VERSION ""

NS_ :

BS_:

BU_: T_Box HUT DMS DVR GW Tester

BO_ 696 ACC_FD4: 64 GW
 SG_ ACC_DataRecReq : 487|3@0+ (1,0) [0|7] ""  DVR

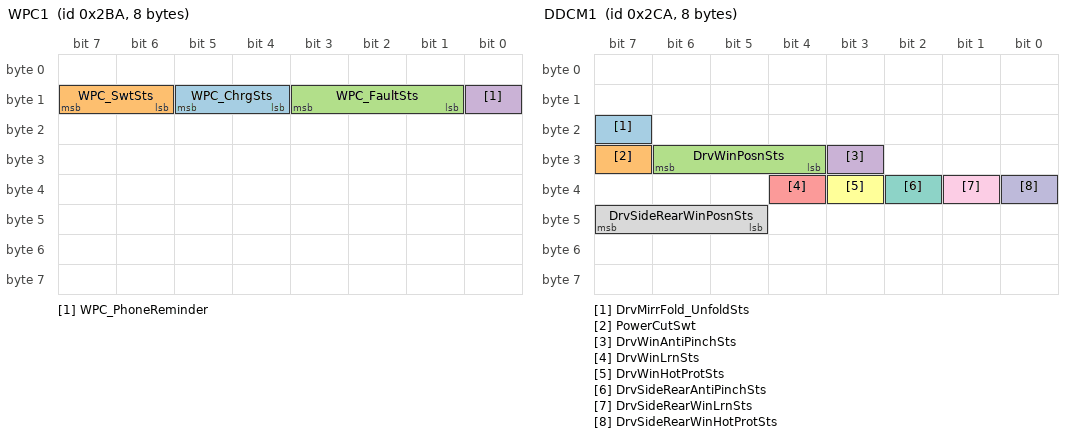
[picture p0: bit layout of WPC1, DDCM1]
BO_ 698 WPC1: 8 GW
 SG_ WPC_ChrgSts : 13|2@0+ (1,0) [0|3] ""  HUT
 SG_ WPC_SwtSts : 15|2@0+ (1,0) [0|3] ""  HUT
 SG_ WPC_FaultSts : 11|3@0+ (1,0) [0|7] ""  HUT
 SG_ WPC_PhoneReminder : 8|1@0+ (1,0) [0|1] ""  HUT

BO_ 699 GW_FD1: 64 GW
 SG_ U_BATT : 71|14@0+ (0.0009765625,3) [3|18] "V"  HUT,T_Box
 SG_ I_RANGE : 73|2@0+ (1,0) [0|3] ""  HUT
 SG_ I_BATT : 87|16@0+ (1,-32768) [-1500|1500] "A"  HUT
 SG_ SOC : 135|8@0+ (1,0) [0|100] "%"  HUT,DVR
 SG_ SOH_SUL : 143|8@0+ (1,0) [0|100] "%"  HUT
 SG_ SOC_STATE : 183|2@0+ (1,0) [0|3] ""  HUT
 SG_ SOH_SUL_STATE : 181|2@0+ (1,0) [0|3] ""  HUT

BO_ 705 DSM1: 8 GW
 SG_ DSM_BuzSoundCmd : 11|2@0+ (1,0) [0|3] ""  HUT

BO_ 707 HUT_FD1: 64 HUT
 SG_ SSSSet_HUT : 64|1@0+ (1,0) [0|1] ""  GW
 SG_ IFC_SnvtySet : 77|2@0+ (1,0) [0|3] ""  GW
 SG_ DOWSwtReq : 104|1@0+ (1,0) [0|1] ""  GW
 SG_ AEB_PedSwtReq : 105|1@0+ (1,0) [0|1] ""  GW
 SG_ ALCMLightLvlSet : 75|4@0+ (1,0) [0|15] "" Vector__XXX
 SG_ FlashLmpSwtReq : 86|1@0+ (1,0) [0|1] ""  GW
 SG_ LCASwtReq : 85|1@0+ (1,0) [0|1] ""  GW
 SG_ RCTASwtReq : 84|1@0+ (1,0) [0|1] ""  GW
 SG_ RCTABrkSwtReq : 83|1@0+ (1,0) [0|1] ""  GW
 SG_ RCWSwtReq : 82|1@0+ (1,0) [0|1] ""  GW
 SG_ FCW_SnvtySet : 81|2@0+ (1,0) [0|3] ""  GW
 SG_ AEB_VehSwtReq : 95|1@0+ (1,0) [0|1] ""  GW
 SG_ LKASwtReq : 93|1@0+ (1,0) [0|1] ""  GW
 SG_ LCKSwtReq : 92|1@0+ (1,0) [0|1] ""  GW
 SG_ ELKSwtReq : 91|1@0+ (1,0) [0|1] ""  GW
 SG_ ESS_PedSwtReq : 90|1@0+ (1,0) [0|1] ""  GW
 SG_ ESS_VehSwtReq : 89|1@0+ (1,0) [0|1] ""  GW
 SG_ LDWSwtReq : 88|1@0+ (1,0) [0|1] ""  GW
 SG_ TSRSwtReq : 102|1@0+ (1,0) [0|1] ""  GW
 SG_ TSRWarnSwtReq : 101|1@0+ (1,0) [0|1] ""  GW
 SG_ ICA_HandsOffSwtReq : 127|1@0+ (1,0) [0|1] ""  GW
 SG_ ISLSwtReq : 126|1@0+ (1,0) [0|1] ""  GW
 SG_ TSR_SnvtySet : 125|5@0+ (1,-15) [-15|15] "km/h"  GW
 SG_ BrkPedalFeelReq : 79|2@0+ (1,0) [0|3] "" Vector__XXX
 SG_ HFASwtSts : 87|1@0+ (1,0) [0|1] ""  GW
 SG_ EPSSteerModSwtReq : 114|2@0+ (1,0) [0|3] ""  GW
 SG_ DSTSwtReq : 112|1@0+ (1,0) [0|1] ""  GW
 SG_ HUT_ESPFuncOffSwtSts : 98|1@0+ (1,0) [0|1] ""  GW
 SG_ DrivingModReq_HUT : 111|4@0+ (1,0) [0|15] ""  GW
 SG_ LSSSwtReq : 106|1@0+ (1,0) [0|1] ""  GW
 SG_ LSSWarnFormSwtReq : 100|2@0+ (1,0) [0|3] ""  GW
 SG_ IntelligentEvaSwtReq : 107|1@0+ (1,0) [0|1] ""  GW
 SG_ HUT_BattSOCLimSaveMod : 119|5@0+ (1,0) [0|31] ""  GW
 SG_ HUTRadioFrq : 143|12@0+ (1,0) [0|4095] "AM; kHzFM; MHz" Vector__XXX
 SG_ MediaPlaySrc : 159|4@0+ (1,0) [0|15] "" Vector__XXX
 SG_ HUT_DrvModReq : 167|4@0+ (1,0) [0|15] ""  GW
 SG_ USB_AudioSts : 169|2@0+ (1,0) [0|3] "" Vector__XXX
 SG_ USB_VideoSts : 177|2@0+ (1,0) [0|3] "" Vector__XXX
 SG_ BT_AudioSts : 179|2@0+ (1,0) [0|3] "" Vector__XXX
 SG_ IPod_Sts : 181|2@0+ (1,0) [0|3] "" Vector__XXX
 SG_ AM_Sts : 183|2@0+ (1,0) [0|3] "" Vector__XXX
 SG_ FM_Sts : 185|2@0+ (1,0) [0|3] "" Vector__XXX
 SG_ APPLink_Sts : 187|2@0+ (1,0) [0|3] "" Vector__XXX
 SG_ QQMusic_Sts : 189|2@0+ (1,0) [0|3] "" Vector__XXX
 SG_ KaolaFM_Sts : 191|2@0+ (1,0) [0|3] "" Vector__XXX
 SG_ OnlineNews_Sts : 145|2@0+ (1,0) [0|3] "" Vector__XXX
 SG_ ChairMemPosnSet : 244|2@0+ (1,0) [0|3] "" Vector__XXX
 SG_ CCOSwtReq_HUT : 242|1@0+ (1,0) [0|1] ""  GW
 SG_ ChairMemPosnSetResult : 255|4@0+ (1,0) [0|15] "" Vector__XXX
 SG_ TABSwtReq_HUT : 224|1@0+ (1,0) [0|1] ""  GW
 SG_ NavVehToTrafEyeDist : 239|10@0+ (1,0) [0|1023] ""  GW
 SG_ NavRoadType : 311|4@0+ (1,0) [0|15] ""  GW
 SG_ NavSpdLimType : 307|2@0+ (1,0) [0|3] ""  GW
 SG_ NavSpdLimValue : 271|6@0+ (1,0) [0|63] ""  GW
 SG_ NavSpdLimUnit_HUT : 265|2@0+ (1,0) [0|3] ""  GW
 SG_ NavCtryType : 279|10@0+ (1,0) [0|1023] ""  GW
 SG_ NavSpdLimSignSts : 285|3@0+ (1,0) [0|7] ""  GW
 SG_ NavTSRTrafSign : 295|8@0+ (1,0) [0|255] ""  GW
 SG_ FCTASwtReq : 301|1@0+ (1,0) [0|1] "" Vector__XXX
 SG_ FCTABrkSwtReq : 300|1@0+ (1,0) [0|1] "" Vector__XXX
 SG_ AEB_JASwtReq : 299|1@0+ (1,0) [0|1] ""  GW
 SG_ AESSwtReq : 298|1@0+ (1,0) [0|1] ""  GW
 SG_ ADAS_Posn_MsgTye : 327|3@0+ (1,0) [0|7] ""  GW
 SG_ ADAS_Posn_Offset : 324|13@0+ (1,0) [0|8190] "m"  GW
 SG_ ADAS_Posn_CycCnt : 343|2@0+ (1,0) [0|3] ""  GW
 SG_ ADAS_Posn_Pathldx : 341|6@0+ (1,0) [0|63] ""  GW
 SG_ ADAS_Posn_Idx : 351|2@0+ (1,0) [0|3] "m"  GW
 SG_ ADAS_Posn_PosProbb : 349|5@0+ (3.33,0) [0|100] ""  GW
 SG_ ADAS_Posn_Age : 344|9@0+ (5,0) [0|2545] "ms"  GW
 SG_ ADAS_Posn_PosConfdc : 366|3@0+ (1,0) [0|7] ""  GW
 SG_ ADAS_Posn_CurLane : 363|3@0+ (1,0) [0|7] ""  GW
 SG_ ADAS_Posn_Spd : 360|9@0+ (0.2,-12.8) [-12.8|89.2] "m/s"  GW
 SG_ ADAS_Posn_Rehead : 383|8@0+ (360,0) [0|358.583] ""  GW
 SG_ FreshnessValue_HUT_FD1 : 455|16@0+ (1,0) [0|65535] ""  GW
 SG_ MAC_Check_HUT_FD1 : 471|48@0+ (1,0) [0|281474976710655] ""  GW

BO_ 708 BMS35: 8 GW
 SG_ BMS_BattSOC : 15|10@0+ (0.1,0) [0|100] "%"  HUT

BO_ 714 DDCM1: 8 GW
 SG_ DrvMirrFold_UnfoldSts : 23|1@0+ (1,0) [0|1] ""  HUT
 SG_ PowerCutSwt : 31|1@0+ (1,0) [0|1] ""  HUT
 SG_ DrvWinPosnSts : 30|3@0+ (1,0) [0|3] ""  HUT,T_Box
 SG_ DrvWinAntiPinchSts : 27|1@0+ (1,0) [0|1] ""  HUT,T_Box
 SG_ DrvWinLrnSts : 36|1@0+ (1,0) [0|1] ""  HUT,T_Box
 SG_ DrvWinHotProtSts : 35|1@0+ (1,0) [0|1] ""  HUT
 SG_ DrvSideRearAntiPinchSts : 34|1@0+ (1,0) [0|1] ""  HUT,T_Box
 SG_ DrvSideRearWinPosnSts : 47|3@0+ (1,0) [0|3] ""  HUT,T_Box
 SG_ DrvSideRearWinLrnSts : 33|1@0+ (1,0) [0|1] ""  HUT,T_Box
 SG_ DrvSideRearWinHotProtSts : 32|1@0+ (1,0) [0|1] ""  HUT

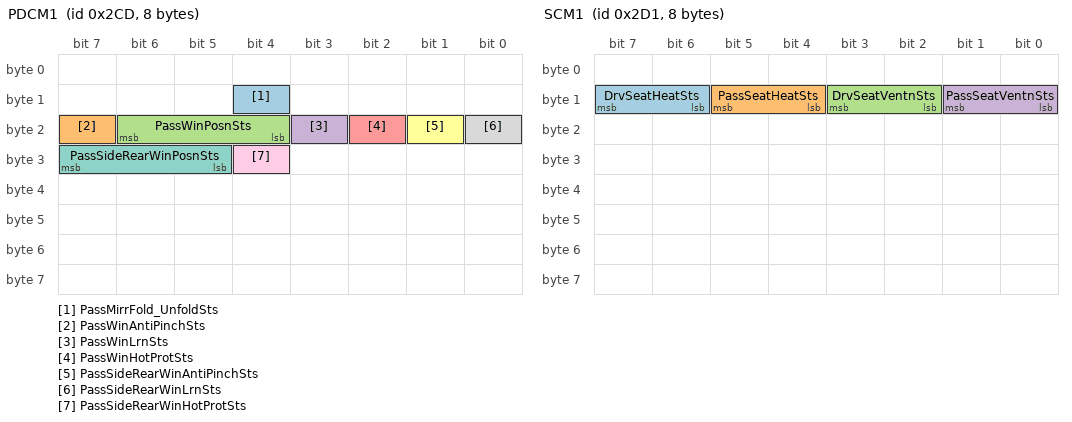
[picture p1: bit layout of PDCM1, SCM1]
BO_ 717 PDCM1: 8 GW
 SG_ PassMirrFold_UnfoldSts : 12|1@0+ (1,0) [0|1] ""  HUT
 SG_ PassWinAntiPinchSts : 23|1@0+ (1,0) [0|1] ""  HUT,T_Box
 SG_ PassWinPosnSts : 22|3@0+ (1,0) [0|3] ""  HUT,T_Box
 SG_ PassWinLrnSts : 19|1@0+ (1,0) [0|1] ""  HUT,T_Box
 SG_ PassWinHotProtSts : 18|1@0+ (1,0) [0|1] ""  HUT
 SG_ PassSideRearWinAntiPinchSts : 17|1@0+ (1,0) [0|1] ""  HUT,T_Box
 SG_ PassSideRearWinPosnSts : 31|3@0+ (1,0) [0|3] ""  HUT,T_Box
 SG_ PassSideRearWinLrnSts : 16|1@0+ (1,0) [0|1] ""  HUT,T_Box
 SG_ PassSideRearWinHotProtSts : 28|1@0+ (1,0) [0|1] ""  HUT

BO_ 719 IFC_FD3: 64 GW
 SG_ TSRResp : 79|1@0+ (1,0) [0|1] ""  HUT
 SG_ TSRSpdLimUnit : 78|2@0+ (1,0) [0|3] ""  HUT
 SG_ TSRSpdLim : 87|6@0+ (1,0) [0|63] ""  HUT
 SG_ TSRSpdLimCfdc : 76|2@0+ (1,0) [0|3] ""  HUT
 SG_ TSRSts : 74|3@0+ (1,0) [0|7] ""  HUT
 SG_ TSRSpdLimSts : 81|2@0+ (1,0) [0|3] ""  HUT
 SG_ TSRTrfcSignValCfdc : 95|2@0+ (1,0) [0|3] ""  HUT
 SG_ TSRTrfcSignVal : 93|8@0+ (1,0) [0|255] ""  HUT
 SG_ TSRSpdLimWarn : 101|1@0+ (1,0) [0|1] ""  HUT
 SG_ TSRWarnResp : 108|1@0+ (1,0) [0|1] ""  HUT
 SG_ TSR_Snvty : 100|5@0+ (1,-15) [-15|15] "km/h"  HUT

BO_ 721 SCM1: 8 GW
 SG_ DrvSeatHeatSts : 15|2@0+ (1,0) [0|3] ""  HUT,T_Box
 SG_ PassSeatHeatSts : 13|2@0+ (1,0) [0|3] ""  HUT,T_Box
 SG_ DrvSeatVentnSts : 11|2@0+ (1,0) [0|3] ""  HUT,T_Box
 SG_ PassSeatVentnSts : 9|2@0+ (1,0) [0|3] ""  HUT,T_Box

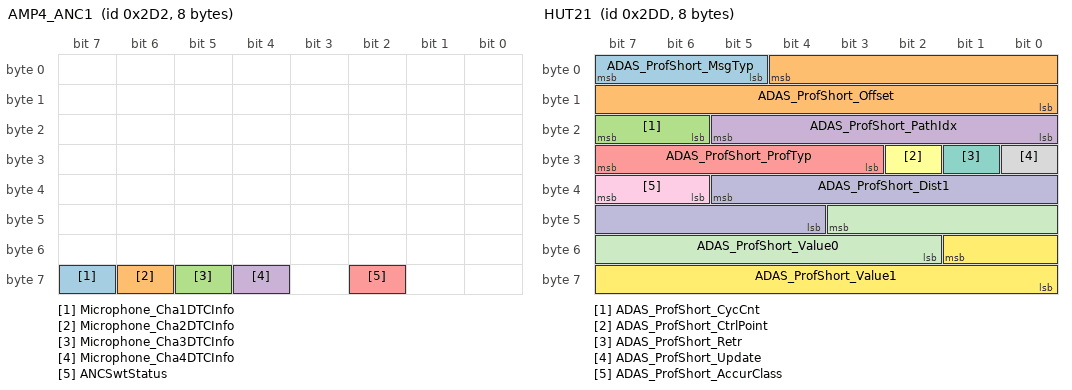
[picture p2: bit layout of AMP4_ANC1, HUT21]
BO_ 722 AMP4_ANC1: 8 GW
 SG_ Microphone_Cha1DTCInfo : 63|1@0+ (1,0) [0|1] ""  HUT
 SG_ Microphone_Cha2DTCInfo : 62|1@0+ (1,0) [0|1] ""  HUT
 SG_ Microphone_Cha3DTCInfo : 61|1@0+ (1,0) [0|1] ""  HUT
 SG_ Microphone_Cha4DTCInfo : 60|1@0+ (1,0) [0|1] ""  HUT
 SG_ ANCSwtStatus : 58|1@0+ (1,0) [0|1] ""  HUT

BO_ 723 ECM11: 8 GW
 SG_ EngSpd_ForIP : 47|16@0+ (0.125,0) [0|8191.875] "rpm"  HUT
 SG_ EWP_Err : 32|1@0+ (1,0) [1|1] ""  HUT

BO_ 728 HUT23: 8 HUT
 SG_ ADAS_Stub_MsgTyp : 7|3@0+ (1,0) [0|7] ""  GW
 SG_ ADAS_Stub_Offset : 4|13@0+ (1,0) [0|8190] "m"  GW
 SG_ ADAS_Stub_CycCnt : 23|2@0+ (1,0) [0|3] ""  GW
 SG_ ADAS_Stub_PathIdx : 21|6@0+ (1,0) [0|63] ""  GW
 SG_ ADAS_Stub_StubPathIdx : 31|6@0+ (1,0) [0|63] ""  GW
 SG_ ADAS_Stub_Retr : 25|1@0+ (1,0) [0|1] ""  GW
 SG_ ADAS_Stub_Update : 24|1@0+ (1,0) [0|1] ""  GW
 SG_ ADAS_Stub_RelProbb : 39|5@0+ (100,0) [0|100] ""  GW
 SG_ ADAS_Stub_FuncRoadClass : 34|3@0+ (1,0) [0|7] ""  GW
 SG_ ADAS_Stub_PartOfCalcRoute : 47|2@0+ (1,0) [0|3] ""  GW
 SG_ ADAS_Stub_CmplxInsct : 45|2@0+ (1,0) [0|3] ""  GW
 SG_ ADAS_Stub_FormOfWay : 43|4@0+ (1,0) [0|15] ""  GW
 SG_ ADAS_Stub_TurnAngl : 55|8@0+ (360,0) [0|358.583] ""  GW
 SG_ ADAS_Stub_LastStub : 63|1@0+ (1,0) [0|1] ""  GW
 SG_ ADAS_Stub_RtOfWay : 62|2@0+ (1,0) [0|3] ""  GW
 SG_ ADAS_Stub_NumOfLaneOppDir : 60|2@0+ (1,0) [0|3] ""  GW
 SG_ ADAS_Stub_NumOfLaneDrvDir : 58|3@0+ (1,0) [0|7] ""  GW

BO_ 730 HUT22: 8 HUT
 SG_ ADAS_Seg_MsgTyp : 7|3@0+ (1,0) [0|7] ""  GW
 SG_ ADAS_Seg_Offset : 4|13@0+ (1,0) [0|8190] "m"  GW
 SG_ ADAS_Seg_CycCnt : 23|2@0+ (1,0) [0|3] ""  GW
 SG_ ADAS_Seg_PathIdx : 21|6@0+ (1,0) [0|63] ""  GW
 SG_ ADAS_Seg_Tunnel : 31|2@0+ (1,0) [0|3] ""  GW
 SG_ ADAS_Seg_Brdg : 29|2@0+ (1,0) [0|3] ""  GW
 SG_ ADAS_Seg_BuildUpArea : 27|2@0+ (1,0) [0|3] ""  GW
 SG_ ADAS_Seg_Retr : 25|1@0+ (1,0) [0|1] ""  GW
 SG_ ADAS_Seg_Update : 24|1@0+ (1,0) [0|1] ""  GW
 SG_ ADAS_Seg_RelProbb : 39|5@0+ (100,0) [0|100] ""  GW
 SG_ ADAS_Seg_FuncRoadClass : 34|3@0+ (1,0) [0|7] ""  GW
 SG_ ADAS_Seg_PartOfCalcRoute : 47|2@0+ (1,0) [0|3] ""  GW
 SG_ ADAS_Seg_CmplxInsct : 45|2@0+ (1,0) [0|3] ""  GW
 SG_ ADAS_Seg_FormOfWay : 43|4@0+ (1,0) [0|15] ""  GW
 SG_ ADAS_Seg_EffSpdLmt : 55|5@0+ (1,0) [0|31] ""  GW
 SG_ ADAS_Seg_EffSpdLmtTyp : 50|3@0+ (1,0) [0|7] ""  GW
 SG_ ADAS_Seg_DivideRoad : 62|2@0+ (1,0) [0|3] ""  GW
 SG_ ADAS_Seg_NumOfLaneOppDir : 60|2@0+ (1,0) [0|3] ""  GW
 SG_ ADAS_Seg_NumOfLaneDrvDir : 58|3@0+ (1,0) [0|7] ""  GW

BO_ 731 ALCM1: 8 GW
 SG_ ALCMSwtSts : 8|1@0+ (1,0) [0|1] ""  HUT

BO_ 733 HUT21: 8 HUT
 SG_ ADAS_ProfShort_MsgTyp : 7|3@0+ (1,0) [0|7] ""  GW
 SG_ ADAS_ProfShort_Offset : 4|13@0+ (1,0) [0|8190] "m"  GW
 SG_ ADAS_ProfShort_CycCnt : 23|2@0+ (1,0) [0|3] ""  GW
 SG_ ADAS_ProfShort_PathIdx : 21|6@0+ (1,0) [0|63] ""  GW
 SG_ ADAS_ProfShort_ProfTyp : 31|5@0+ (1,0) [0|31] ""  GW
 SG_ ADAS_ProfShort_CtrlPoint : 26|1@0+ (1,0) [0|1] ""  GW
 SG_ ADAS_ProfShort_Retr : 25|1@0+ (1,0) [0|1] ""  GW
 SG_ ADAS_ProfShort_Update : 24|1@0+ (1,0) [0|1] ""  GW
 SG_ ADAS_ProfShort_AccurClass : 39|2@0+ (1,0) [0|3] ""  GW
 SG_ ADAS_ProfShort_Dist1 : 37|10@0+ (1,0) [0|1022] "m"  GW
 SG_ ADAS_ProfShort_Value0 : 43|10@0+ (1,0) [0|1022] ""  GW
 SG_ ADAS_ProfShort_Value1 : 49|10@0+ (1,0) [0|1022] ""  GW

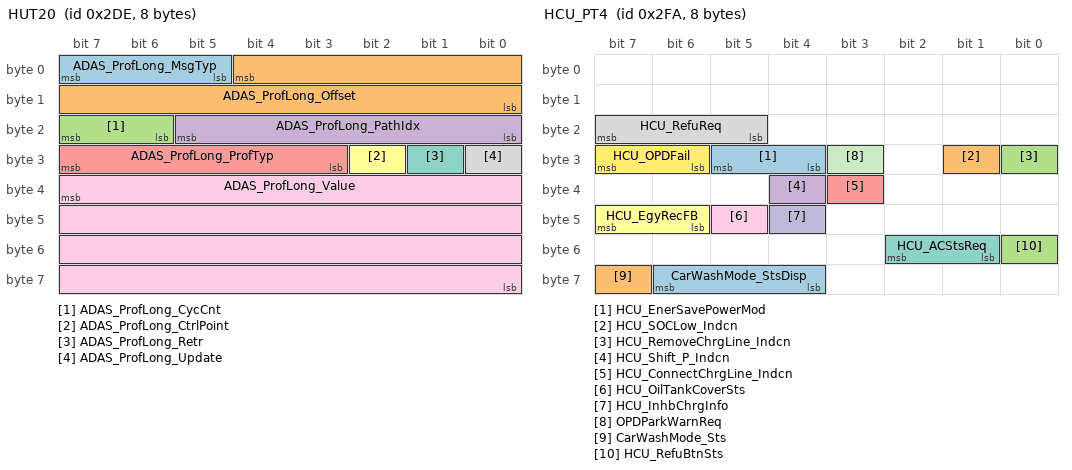
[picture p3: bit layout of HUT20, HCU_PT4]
BO_ 734 HUT20: 8 HUT
 SG_ ADAS_ProfLong_MsgTyp : 7|3@0+ (1,0) [0|7] ""  GW
 SG_ ADAS_ProfLong_Offset : 4|13@0+ (1,0) [0|8190] "m"  GW
 SG_ ADAS_ProfLong_CycCnt : 23|2@0+ (1,0) [0|3] ""  GW
 SG_ ADAS_ProfLong_PathIdx : 21|6@0+ (1,0) [0|63] ""  GW
 SG_ ADAS_ProfLong_ProfTyp : 31|5@0+ (1,0) [0|31] ""  GW
 SG_ ADAS_ProfLong_CtrlPoint : 26|1@0+ (1,0) [0|1] ""  GW
 SG_ ADAS_ProfLong_Retr : 25|1@0+ (1,0) [0|1] ""  GW
 SG_ ADAS_ProfLong_Update : 24|1@0+ (1,0) [0|1] ""  GW
 SG_ ADAS_ProfLong_Value : 39|32@0+ (1,0) [0|4294967295] ""  GW

BO_ 737 VSG1: 8 GW
 SG_ VSG_Sts : 15|2@0+ (1,0) [0|3] ""  HUT
 SG_ VSG_HUTSoundResp : 11|2@0+ (1,0) [0|3] ""  HUT

BO_ 748 DVR_FD1: 64 DVR
 SG_ DVRRemtCnSts : 11|2@0+ (1,0) [0|3] ""  T_Box
 SG_ DVR_360VideoCaptureReq : 9|1@0+ (1,0) [0|1] ""  GW
 SG_ DVRSN : 71|48@0+ (1,0) [0|1] ""  T_Box

BO_ 749 RPAS2: 8 GW
 SG_ RPAS_NearBrrdstn : 15|8@0+ (1,0) [0|150] ""  HUT

BO_ 762 HCU_PT4: 8 GW
 SG_ HCU_EnerSavePowerMod : 29|2@0+ (1,0) [0|3] ""  HUT
 SG_ HCU_SOCLow_Indcn : 25|1@0+ (1,0) [0|1] ""  HUT
 SG_ HCU_RemoveChrgLine_Indcn : 24|1@0+ (1,0) [0|1] ""  HUT
 SG_ HCU_Shift_P_Indcn : 36|1@0+ (1,0) [0|1] ""  HUT
 SG_ HCU_ConnectChrgLine_Indcn : 35|1@0+ (1,0) [0|1] ""  HUT
 SG_ HCU_EgyRecFB : 47|2@0+ (1,0) [0|3] ""  HUT
 SG_ HCU_ACStsReq : 50|2@0+ (1,0) [0|3] ""  HUT
 SG_ HCU_RefuReq : 23|3@0+ (1,0) [0|7] ""  HUT
 SG_ HCU_OilTankCoverSts : 45|1@0+ (1,0) [0|1] ""  HUT
 SG_ HCU_InhbChrgInfo : 44|1@0+ (1,0) [0|1] ""  HUT
 SG_ OPDParkWarnReq : 27|1@0+ (1,0) [0|1] ""  HUT
 SG_ HCU_OPDFail : 31|2@0+ (1,0) [0|3] ""  HUT
 SG_ CarWashMode_StsDisp : 62|3@0+ (1,0) [0|7] ""  HUT
 SG_ CarWashMode_Sts : 63|1@0+ (1,0) [0|1] ""  HUT
 SG_ HCU_RefuBtnSts : 48|1@0+ (1,0) [0|1] ""  T_Box

BO_ 766 PLG_1: 8 GW
 SG_ PLG_Sts : 15|3@0+ (1,0) [0|7] ""  HUT

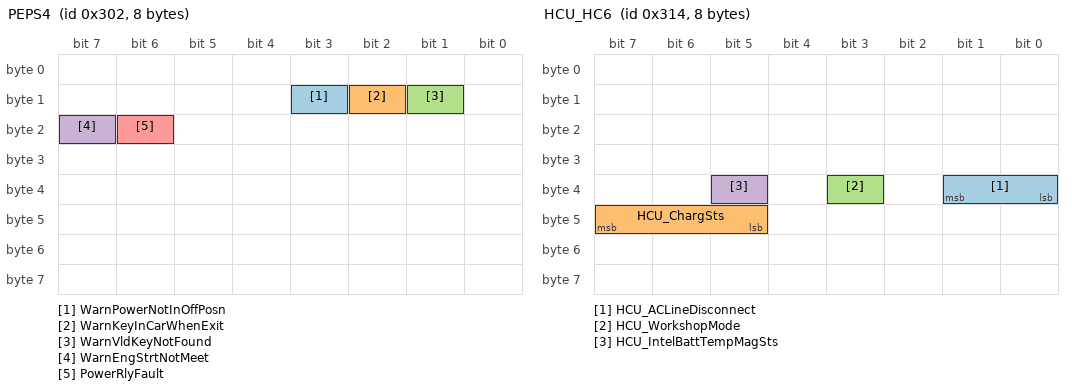
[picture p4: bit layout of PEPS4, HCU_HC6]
BO_ 770 PEPS4: 8 GW
 SG_ WarnPowerNotInOffPosn : 11|1@0+ (1,0) [0|1] ""  HUT
 SG_ WarnKeyInCarWhenExit : 10|1@0+ (1,0) [0|1] ""  HUT
 SG_ WarnVldKeyNotFound : 9|1@0+ (1,0) [0|1] ""  HUT
 SG_ WarnEngStrtNotMeet : 23|1@0+ (1,0) [0|1] ""  HUT
 SG_ PowerRlyFault : 22|1@0+ (1,0) [0|1] ""  HUT

BO_ 771 ESCL2: 8 GW
 SG_ RotSteerWheel : 21|1@0+ (1,0) [0|1] ""  HUT

BO_ 773 BCM11: 8 GW
 SG_ ClsWinRmd : 16|1@0+ (1,0) [0|1] ""  T_Box

BO_ 788 HCU_HC6: 8 GW
 SG_ HCU_ACLineDisconnect : 33|2@0+ (1,0) [0|3] ""  HUT,T_Box
 SG_ HCU_ChargSts : 47|3@0+ (1,0) [0|7] ""  HUT,T_Box
 SG_ HCU_WorkshopMode : 35|1@0+ (1,0) [0|1] ""  HUT
 SG_ HCU_IntelBattTempMagSts : 37|1@0+ (1,0) [0|1] ""  HUT,T_Box

BO_ 790 OBC1: 8 GW
 SG_ OBC_ModSts : 19|4@0+ (1,0) [0|15] ""  HUT

BO_ 791 OBC2: 8 GW
 SG_ OBC_ConnectSts : 15|2@0+ (1,0) [0|3] ""  HUT

BO_ 793 BCM1: 16 GW
 SG_ IPBackgroundLmpCmd : 18|1@0+ (1,0) [0|1] ""  HUT
 SG_ TrunkSts : 23|1@0+ (1,0) [0|1] ""  HUT,T_Box,DVR
 SG_ DrvDoorSts : 22|1@0+ (1,0) [0|1] ""  HUT,T_Box,DMS,DVR
 SG_ LRDoorSts : 21|1@0+ (1,0) [0|1] ""  HUT,T_Box,DVR
 SG_ PassengerDoorSts : 20|1@0+ (1,0) [0|1] ""  HUT,T_Box,DVR
 SG_ RRDoorSts : 19|1@0+ (1,0) [0|1] ""  HUT,T_Box,DVR
 SG_ BrkPedalSts_BCM : 16|1@0+ (1,0) [0|1] ""  HUT
 SG_ BackgroundLightLvl : 39|8@0+ (1,0) [0|255] ""  HUT
 SG_ DrowsyDrvDetWarn : 44|2@0+ (1,0) [0|3] ""  HUT
 SG_ RLSFailSts : 63|1@0+ (1,0) [0|1] ""  HUT
 SG_ ReversGearSts : 42|2@0+ (1,0) [0|3] ""  T_Box
 SG_ PosnLightReq : 61|1@0+ (1,0) [0|1] ""  HUT
 SG_ FreshnessValue_BCM1 : 71|16@0+ (1,0) [0|65535] ""  HUT,T_Box
 SG_ MAC_Check_BCM1 : 87|48@0+ (1,0) [0|281474976710655] ""  HUT,T_Box

BO_ 796 HUT13: 8 HUT
 SG_ AudioMuteSts : 15|2@0+ (1,0) [0|3] ""  T_Box
 SG_ VSGSwtSet : 8|1@0+ (1,0) [0|1] ""  GW

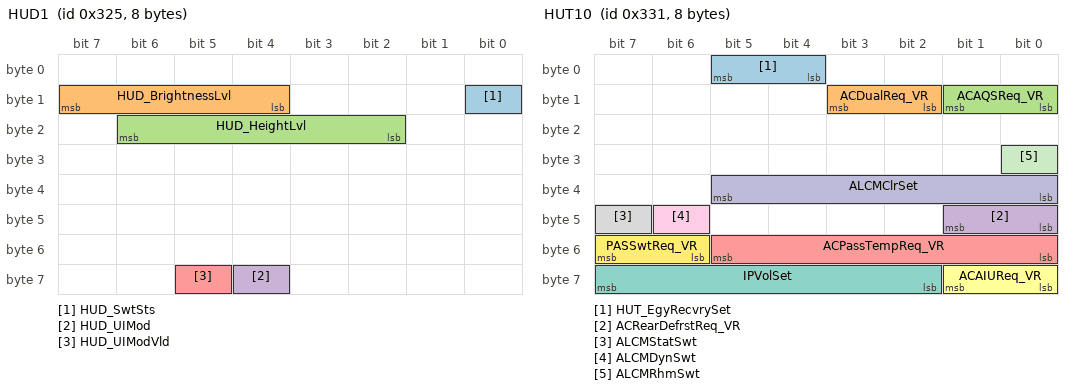
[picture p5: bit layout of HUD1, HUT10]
BO_ 805 HUD1: 8 GW
 SG_ HUD_SwtSts : 8|1@0+ (1,0) [0|1] ""  HUT
 SG_ HUD_BrightnessLvl : 15|4@0+ (1,0) [0|15] ""  HUT
 SG_ HUD_HeightLvl : 22|5@0+ (1,0) [0|31] ""  HUT
 SG_ HUD_UIMod : 60|1@0+ (1,0) [0|1] ""  HUT
 SG_ HUD_UIModVld : 61|1@0+ (1,0) [0|1] ""  HUT

BO_ 817 HUT10: 8 HUT
 SG_ HUT_EgyRecvrySet : 5|2@0+ (1,0) [0|3] ""  GW
 SG_ ACDualReq_VR : 11|2@0+ (1,0) [0|3] ""  GW
 SG_ ACAQSReq_VR : 9|2@0+ (1,0) [0|3] ""  GW
 SG_ ACRearDefrstReq_VR : 41|2@0+ (1,0) [0|3] ""  GW
 SG_ ACPassTempReq_VR : 53|6@0+ (0.5,15.5) [16|32] "°C"  GW
 SG_ ACAIUReq_VR : 57|2@0+ (1,0) [0|3] ""  GW
 SG_ IPVolSet : 63|6@0+ (1,0) [0|63] ""  GW
 SG_ ALCMStatSwt : 47|1@0+ (1,0) [0|1] "" Vector__XXX
 SG_ ALCMDynSwt : 46|1@0+ (1,0) [0|1] "" Vector__XXX
 SG_ ALCMClrSet : 37|6@0+ (1,0) [0|63] "" Vector__XXX
 SG_ ALCMRhmSwt : 24|1@0+ (1,0) [0|1] "" Vector__XXX
 SG_ PASSwtReq_VR : 55|2@0+ (1,0) [0|3] ""  GW

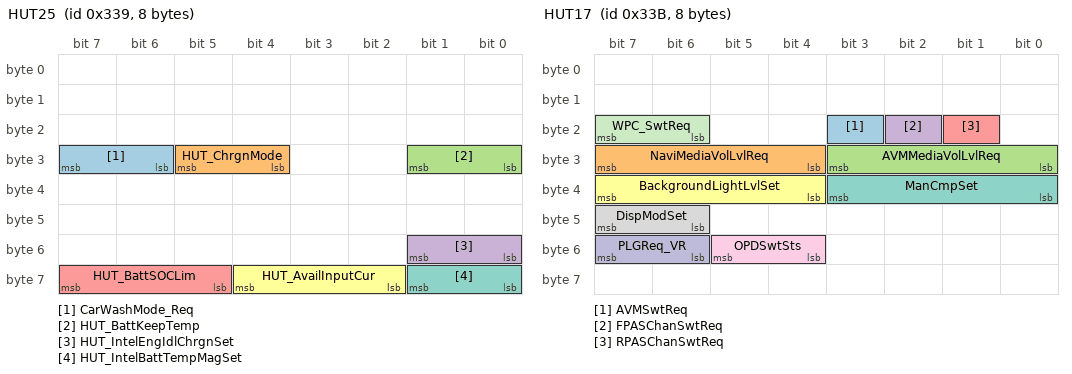
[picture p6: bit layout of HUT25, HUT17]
BO_ 825 HUT25: 8 HUT
 SG_ CarWashMode_Req : 31|2@0+ (1,0) [0|3] ""  GW
 SG_ HUT_ChrgnMode : 29|2@0+ (1,0) [0|3] ""  GW,T_Box
 SG_ HUT_BattKeepTemp : 25|2@0+ (1,0) [0|3] ""  GW,T_Box
 SG_ HUT_IntelEngIdlChrgnSet : 49|2@0+ (1,0) [0|3] ""  GW
 SG_ HUT_BattSOCLim : 63|3@0+ (1,0) [0|7] ""  GW,T_Box
 SG_ HUT_AvailInputCur : 60|3@0+ (1,0) [0|7] ""  GW,T_Box
 SG_ HUT_IntelBattTempMagSet : 57|2@0+ (1,0) [0|3] ""  GW,T_Box

BO_ 827 HUT17: 8 HUT
 SG_ AVMSwtReq : 19|1@0+ (1,0) [0|1] ""  GW
 SG_ NaviMediaVolLvlReq : 31|4@0+ (1,0) [0|15] ""  GW
 SG_ AVMMediaVolLvlReq : 27|4@0+ (1,0) [0|15] ""  GW
 SG_ FPASChanSwtReq : 18|1@0+ (1,0) [0|1] ""  GW
 SG_ RPASChanSwtReq : 17|1@0+ (1,0) [0|1] ""  GW
 SG_ BackgroundLightLvlSet : 39|4@0+ (1,0) [0|15] ""  GW
 SG_ ManCmpSet : 35|4@0+ (1,0) [0|15] "" Vector__XXX
 SG_ DispModSet : 47|2@0+ (1,0) [0|3] "" Vector__XXX
 SG_ OPDSwtSts : 53|2@0+ (1,0) [0|3] ""  GW
 SG_ PLGReq_VR : 55|2@0+ (1,0) [0|3] ""  GW
 SG_ WPC_SwtReq : 23|2@0+ (1,0) [0|3] ""  GW

BO_ 833 TPMS1: 16 GW
 SG_ FLTirePressIndSts : 15|3@0+ (1,0) [0|7] ""  HUT,T_Box
 SG_ FRTirePressIndSts : 12|3@0+ (1,0) [0|7] ""  HUT,T_Box
 SG_ TirePressSysFailrIndcn : 9|2@0+ (1,0) [0|3] ""  HUT,T_Box
 SG_ RLTirePressIndSts : 23|3@0+ (1,0) [0|7] ""  HUT,T_Box
 SG_ RRTirePressIndSts : 20|3@0+ (1,0) [0|7] ""  HUT,T_Box
 SG_ FLTireTempSts : 31|2@0+ (1,0) [0|3] ""  HUT,T_Box
 SG_ FRTireTempSts : 29|2@0+ (1,0) [0|3] ""  HUT,T_Box
 SG_ RLTireTempSts : 27|2@0+ (1,0) [0|3] ""  HUT,T_Box
 SG_ RRTireTempSts : 25|2@0+ (1,0) [0|3] ""  HUT,T_Box
 SG_ TPMS_AutoLoctSts : 39|4@0+ (1,0) [0|5] ""  T_Box
 SG_ FreshnessValue_TPMS1 : 71|16@0+ (1,0) [0|65535] ""  HUT,T_Box
 SG_ MAC_Check_TPMS1 : 87|48@0+ (1,0) [0|281474976710655] ""  HUT,T_Box

BO_ 837 BCM3: 16 GW
 SG_ LasHdLmpSts : 35|1@0+ (1,0) [0|1] ""  HUT
 SG_ AntitheftSts : 15|2@0+ (1,0) [0|3] ""  T_Box,DVR
 SG_ DrvDoorLockSts : 34|1@0+ (1,0) [0|1] ""  HUT,T_Box,DMS
 SG_ DoorLockSts : 13|2@0+ (1,0) [0|3] ""  HUT,T_Box
 SG_ RLDoorLockSts : 11|1@0+ (1,0) [0|1] ""  T_Box
 SG_ PassDoorLockSts : 10|1@0+ (1,0) [0|1] ""  T_Box
 SG_ RRDoorLockSts : 9|1@0+ (1,0) [0|1] ""  T_Box
 SG_ HiLowBeamSts : 33|2@0+ (1,0) [0|2] ""  HUT
 SG_ FreshnessValue_BCM3 : 71|16@0+ (1,0) [0|65535] ""  HUT,T_Box
 SG_ MAC_Check_BCM3 : 87|48@0+ (1,0) [0|281474976710655] ""  HUT,T_Box

BO_ 840 HUT16: 8 HUT
 SG_ PowerSet : 39|1@0+ (1,0) [0|1] ""  GW

BO_ 842 HUT_IP3: 16 HUT
 SG_ IP_RemainDistance : 15|12@0+ (1,0) [0|2000] "km"  T_Box
 SG_ IP_InstFuelConsUnit : 19|1@0+ (1,0) [0|1] "" Vector__XXX
 SG_ IP_EBDFailSts : 18|1@0+ (1,0) [0|1] "" Vector__XXX
 SG_ IP_AvgFuelCons : 31|12@0+ (0.01,0) [0|29.99] "L/100km"  T_Box
 SG_ IP_InstFuelCons : 35|14@0+ (0.01,0) [0|99.99] "L/100km
"  T_Box

BO_ 849 ABM1: 16 GW
 SG_ CheckSum_ABM1 : 7|8@0+ (1,0) [0|255] ""  HUT
 SG_ SecRowLSBR : 14|1@0+ (1,0) [0|1] ""  HUT
 SG_ AirbFailLmpCmd : 13|1@0+ (1,0) [0|1] ""  HUT
 SG_ SecRowMidSBR : 12|1@0+ (1,0) [0|1] ""  HUT
 SG_ DrvSBR : 11|1@0+ (1,0) [0|1] ""  HUT
 SG_ SecRowRSBR : 10|1@0+ (1,0) [0|1] ""  HUT
 SG_ PassSBR : 9|1@0+ (1,0) [0|1] ""  HUT
 SG_ PassSBR_Visual : 27|2@0+ (1,0) [0|3] ""  HUT
 SG_ DrvSBR_Visual : 25|2@0+ (1,0) [0|3] ""  HUT
 SG_ SecRowLSBR_Visual : 29|2@0+ (1,0) [0|3] ""  HUT
 SG_ SecRowMidSBR_Visual : 31|2@0+ (1,0) [0|3] ""  HUT
 SG_ SecRowRSBR_Visual : 33|2@0+ (1,0) [0|3] ""  HUT
 SG_ CrashOutputSts : 23|8@0+ (1,0) [0|18] ""  T_Box,DVR
 SG_ RollingCounter_ABM1 : 59|4@0+ (1,0) [0|15] ""  HUT
 SG_ FreshnessValue_ABM1 : 71|16@0+ (1,0) [0|65535] ""  HUT,T_Box
 SG_ MAC_Check_ABM1 : 87|48@0+ (1,0) [0|281474976710655] ""  HUT,T_Box

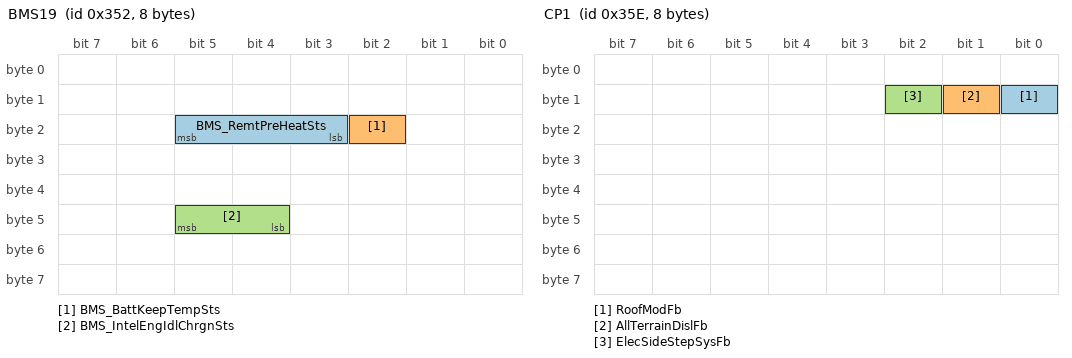
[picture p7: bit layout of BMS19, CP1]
BO_ 850 BMS19: 8 GW
 SG_ BMS_RemtPreHeatSts : 21|3@0+ (1,0) [0|7] ""  T_Box
 SG_ BMS_BattKeepTempSts : 18|1@0+ (1,0) [0|1] ""  HUT,T_Box
 SG_ BMS_IntelEngIdlChrgnSts : 45|2@0+ (1,0) [0|3] ""  HUT,T_Box

BO_ 862 CP1: 8 GW
 SG_ RoofModFb : 8|1@0+ (1,0) [0|1] ""  HUT
 SG_ AllTerrainDislFb : 9|1@0+ (1,0) [0|1] ""  HUT
 SG_ ElecSideStepSysFb : 10|1@0+ (1,0) [0|1] ""  HUT

BO_ 871 HUT1: 8 HUT
 SG_ DomeLmpDlyTimSet : 7|3@0+ (1,0) [0|7] ""  GW
 SG_ FolwMeHomeDlyTimSet : 3|3@0+ (1,0) [0|7] ""  GW
 SG_ TranPMode_Req : 15|1@0+ (1,0) [0|1] ""  GW
 SG_ RearviewFoldModSet : 14|1@0+ (1,0) [0|1] ""  GW
 SG_ BattSaveDelayTimeSet : 13|2@0+ (1,0) [0|3] ""  GW
 SG_ ACDualReq_TC : 21|2@0+ (1,0) [0|3] ""  GW
 SG_ ACAutoModReq_TC : 19|2@0+ (1,0) [0|3] ""  GW
 SG_ ACAirInletReq_TC : 17|2@0+ (1,0) [0|3] ""  GW
 SG_ ACAQSReq_TC : 31|2@0+ (1,0) [0|3] ""  GW
 SG_ ACCmprReq_TC : 29|2@0+ (1,0) [0|3] ""  GW
 SG_ ACFrntDefrstReq_TC : 27|2@0+ (1,0) [0|3] ""  GW
 SG_ ACFrntBlwrSpdDecReq_TC : 25|2@0+ (1,0) [0|3] ""  GW
 SG_ DrvDrowsnsDetnSet : 36|1@0+ (1,0) [0|1] ""  GW
 SG_ ACFrntBlwrSpdIncReq_TC : 47|2@0+ (1,0) [0|3] ""  GW
 SG_ ACDrvAirDistribModReq_TC : 45|3@0+ (1,0) [0|7] ""  GW
 SG_ ACDrvTempDecReq_TC : 42|2@0+ (1,0) [0|3] ""  GW
 SG_ ChairMemPosnEna : 40|1@0+ (1,0) [0|1] "" Vector__XXX
 SG_ ACDrvTempIncReq_TC : 55|2@0+ (1,0) [0|3] ""  GW
 SG_ ACFrntPassTempDecReq_TC : 53|2@0+ (1,0) [0|3] ""  GW
 SG_ ACFrntPassTempIncReq_TC : 51|2@0+ (1,0) [0|3] ""  GW
 SG_ ACAIUReq_TC : 48|1@0+ (1,0) [0|1] ""  GW
 SG_ ACOffReq_TC : 63|2@0+ (1,0) [0|3] ""  GW
 SG_ ACBlwrsteplsSpdReq_TC : 59|4@0+ (1,0) [0|15] ""  GW

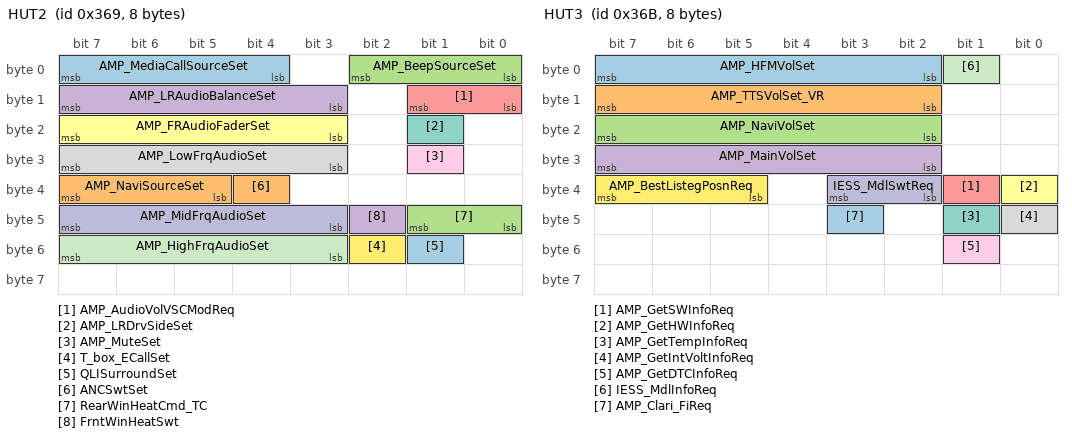
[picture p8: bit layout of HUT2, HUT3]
BO_ 873 HUT2: 8 HUT
 SG_ AMP_MediaCallSourceSet : 7|4@0+ (1,0) [0|15] ""  GW
 SG_ AMP_NaviSourceSet : 39|3@0+ (1,0) [0|7] ""  GW
 SG_ AMP_BeepSourceSet : 2|3@0+ (1,0) [0|7] ""  GW
 SG_ AMP_LRAudioBalanceSet : 15|5@0+ (1,0) [0|20] ""  GW
 SG_ AMP_AudioVolVSCModReq : 9|2@0+ (1,0) [0|3] ""  GW
 SG_ AMP_FRAudioFaderSet : 23|5@0+ (1,0) [0|20] ""  GW
 SG_ AMP_LRDrvSideSet : 17|1@0+ (1,0) [0|1] ""  GW
 SG_ AMP_LowFrqAudioSet : 31|5@0+ (1,0) [0|20] ""  GW
 SG_ AMP_MuteSet : 25|1@0+ (1,0) [0|1] ""  GW
 SG_ AMP_MidFrqAudioSet : 47|5@0+ (1,0) [0|20] ""  GW
 SG_ AMP_HighFrqAudioSet : 55|5@0+ (1,0) [0|20] ""  GW
 SG_ T_box_ECallSet : 50|1@0+ (1,0) [0|1] ""  GW
 SG_ QLISurroundSet : 49|1@0+ (1,0) [0|1] ""  GW
 SG_ ANCSwtSet : 36|1@0+ (1,0) [0|1] ""  GW
 SG_ RearWinHeatCmd_TC : 41|2@0+ (1,0) [0|3] ""  GW
 SG_ FrntWinHeatSwt : 42|1@0+ (1,0) [0|1] ""  GW

BO_ 875 HUT3: 8 HUT
 SG_ AMP_HFMVolSet : 7|6@0+ (1,0) [0|39] ""  GW
 SG_ AMP_TTSVolSet_VR : 15|6@0+ (1,0) [0|39] ""  GW
 SG_ AMP_NaviVolSet : 23|6@0+ (1,0) [0|39] ""  GW
 SG_ AMP_MainVolSet : 31|6@0+ (1,0) [0|39] ""  GW
 SG_ AMP_GetSWInfoReq : 33|1@0+ (1,0) [0|1] ""  GW
 SG_ AMP_GetHWInfoReq : 32|1@0+ (1,0) [0|1] ""  GW
 SG_ AMP_GetTempInfoReq : 41|1@0+ (1,0) [0|1] ""  GW
 SG_ AMP_GetIntVoltInfoReq : 40|1@0+ (1,0) [0|1] ""  GW
 SG_ AMP_GetDTCInfoReq : 49|1@0+ (1,0) [0|1] ""  GW
 SG_ IESS_MdlSwtReq : 35|2@0+ (1,0) [0|3] ""  GW
 SG_ IESS_MdlInfoReq : 1|1@0+ (1,0) [0|1] ""  GW
 SG_ AMP_BestListegPosnReq : 39|3@0+ (1,0) [0|7] ""  GW
 SG_ AMP_Clari_FiReq : 43|1@0+ (1,0) [0|1] ""  GW

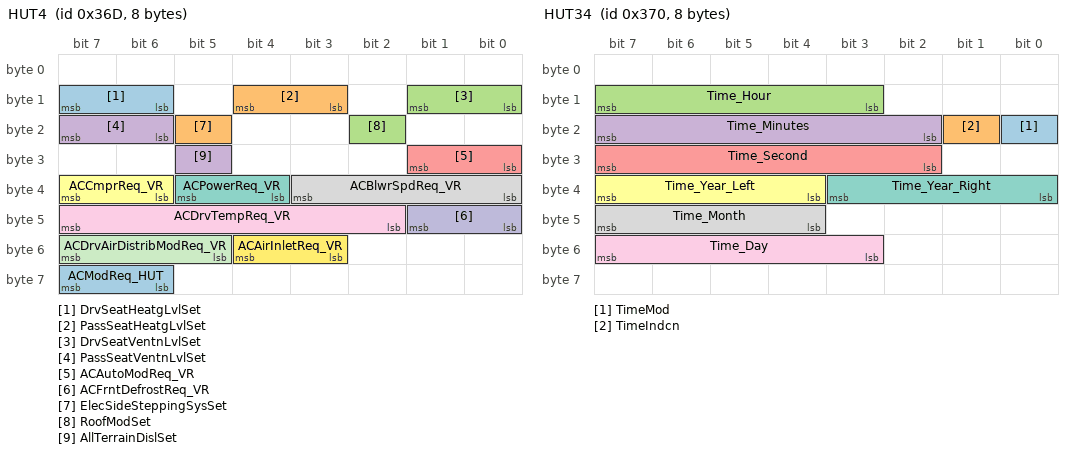
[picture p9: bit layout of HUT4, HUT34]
BO_ 877 HUT4: 8 HUT
 SG_ DrvSeatHeatgLvlSet : 15|2@0+ (1,0) [0|3] ""  GW
 SG_ PassSeatHeatgLvlSet : 12|2@0+ (1,0) [0|3] ""  GW
 SG_ DrvSeatVentnLvlSet : 9|2@0+ (1,0) [0|3] ""  GW
 SG_ PassSeatVentnLvlSet : 23|2@0+ (1,0) [0|3] ""  GW
 SG_ ACAutoModReq_VR : 25|2@0+ (1,0) [0|3] ""  GW
 SG_ ACCmprReq_VR : 39|2@0+ (1,0) [0|3] ""  GW
 SG_ ACPowerReq_VR : 37|2@0+ (1,0) [0|3] ""  GW
 SG_ ACBlwrSpdReq_VR : 35|4@0+ (1,0) [0|15] ""  GW
 SG_ ACDrvTempReq_VR : 47|6@0+ (0.5,15.5) [16|32] "°C"  GW
 SG_ ACFrntDefrostReq_VR : 41|2@0+ (1,0) [0|3] ""  GW
 SG_ ACDrvAirDistribModReq_VR : 55|3@0+ (1,0) [0|7] ""  GW
 SG_ ACAirInletReq_VR : 52|2@0+ (1,0) [0|3] ""  GW
 SG_ ACModReq_HUT : 63|2@0+ (1,0) [0|3] "" Vector__XXX
 SG_ ElecSideSteppingSysSet : 21|1@0+ (1,0) [0|1] ""  GW
 SG_ RoofModSet : 18|1@0+ (1,0) [0|1] ""  GW
 SG_ AllTerrainDislSet : 29|1@0+ (1,0) [0|1] ""  GW

BO_ 880 HUT34: 8 HUT
 SG_ TimeMod : 16|1@0+ (1,0) [0|1] ""  GW,DMS,DVR
 SG_ TimeIndcn : 17|1@0+ (1,0) [0|1] ""  GW,DMS,DVR
 SG_ Time_Hour : 15|5@0+ (1,0) [0|31] ""  GW,T_Box,DMS,DVR
 SG_ Time_Minutes : 23|6@0+ (1,0) [0|63] ""  GW,T_Box,DMS,DVR
 SG_ Time_Second : 31|6@0+ (1,0) [0|63] ""  GW,T_Box,DMS,DVR
 SG_ Time_Year_Left : 39|4@0+ (1,0) [0|15] ""  GW,T_Box,DMS,DVR
 SG_ Time_Year_Right : 35|4@0+ (1,0) [0|15] ""  GW,T_Box,DMS,DVR
 SG_ Time_Month : 47|4@0+ (1,0) [0|15] ""  GW,T_Box,DMS,DVR
 SG_ Time_Day : 55|5@0+ (1,0) [0|31] ""  GW,T_Box,DMS,DVR

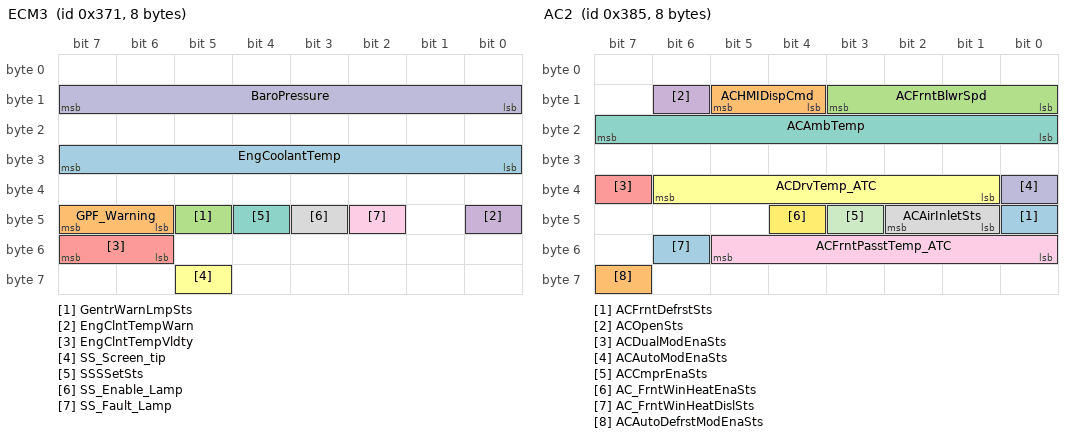
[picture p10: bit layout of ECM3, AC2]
BO_ 881 ECM3: 8 GW
 SG_ EngCoolantTemp : 31|8@0+ (0.75,-48) [-48|143.25] "Deg C"  HUT,T_Box
 SG_ GPF_Warning : 47|2@0+ (1,0) [0|3] ""  HUT
 SG_ GentrWarnLmpSts : 45|1@0+ (1,0) [0|1] ""  HUT
 SG_ EngClntTempWarn : 40|1@0+ (1,0) [0|1] ""  HUT,T_Box
 SG_ EngClntTempVldty : 55|2@0+ (1,0) [0|2] ""  HUT,T_Box
 SG_ SS_Screen_tip : 61|1@0+ (1,0) [0|1] ""  HUT
 SG_ SSSSetSts : 44|1@0+ (1,0) [0|1] ""  HUT
 SG_ SS_Enable_Lamp : 43|1@0+ (1,0) [0|1] ""  HUT
 SG_ SS_Fault_Lamp : 42|1@0+ (1,0) [0|1] ""  HUT
 SG_ BaroPressure : 15|8@0+ (0.59,0) [0|149.86] "kPa"  HUT

BO_ 901 AC2: 8 GW
 SG_ ACFrntDefrstSts : 40|1@0+ (1,0) [0|1] ""  HUT,T_Box
 SG_ ACHMIDispCmd : 13|2@0+ (1,0) [0|3] ""  HUT,T_Box
 SG_ ACFrntBlwrSpd : 11|4@0+ (1,0) [0|15] ""  HUT,T_Box
 SG_ ACOpenSts : 14|1@0+ (1,0) [0|1] ""  HUT,T_Box
 SG_ ACDualModEnaSts : 39|1@0+ (1,0) [0|1] ""  HUT
 SG_ ACDrvTemp_ATC : 38|6@0+ (0.5,16) [16|32] "°C"  HUT,T_Box
 SG_ ACAmbTemp : 23|8@0+ (0.5,-40) [-40|86.5] "°C"  HUT
 SG_ ACAirInletSts : 42|2@0+ (1,0) [0|3] ""  HUT
 SG_ ACFrntPasstTemp_ATC : 53|6@0+ (0.5,16) [16|32] "°C"  HUT,T_Box
 SG_ ACAutoModEnaSts : 32|1@0+ (1,0) [0|1] ""  HUT,T_Box
 SG_ ACCmprEnaSts : 43|1@0+ (1,0) [0|1] ""  HUT
 SG_ AC_FrntWinHeatEnaSts : 44|1@0+ (1,0) [0|1] ""  HUT
 SG_ AC_FrntWinHeatDislSts : 54|1@0+ (1,0) [0|1] ""  HUT
 SG_ ACAutoDefrstModEnaSts : 63|1@0+ (1,0) [0|1] ""  HUT

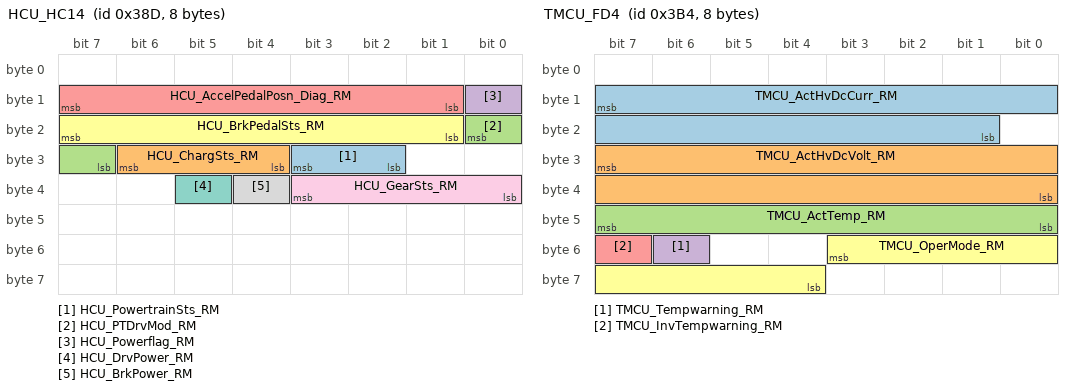
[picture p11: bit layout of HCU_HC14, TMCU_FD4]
BO_ 909 HCU_HC14: 8 GW
 SG_ HCU_PowertrainSts_RM : 27|2@0+ (1,0) [0|3] ""  T_Box
 SG_ HCU_ChargSts_RM : 30|3@0+ (1,0) [0|7] ""  T_Box
 SG_ HCU_PTDrvMod_RM : 16|2@0+ (1,0) [0|3] ""  T_Box
 SG_ HCU_Powerflag_RM : 8|1@0+ (1,0) [0|1] ""  T_Box
 SG_ HCU_AccelPedalPosn_Diag_RM : 15|7@0+ (1,0) [0|100] "%"  T_Box
 SG_ HCU_BrkPedalSts_RM : 23|7@0+ (1,0) [0|101] ""  T_Box
 SG_ HCU_DrvPower_RM : 37|1@0+ (1,0) [0|1] ""  T_Box
 SG_ HCU_BrkPower_RM : 36|1@0+ (1,0) [0|1] ""  T_Box
 SG_ HCU_GearSts_RM : 35|4@0+ (1,0) [0|15] ""  T_Box

BO_ 917 TPMS2: 16 GW
 SG_ FLTirePress : 7|8@0+ (1.3725,0) [0|348.615] "kPa"  HUT,T_Box
 SG_ FLTireTemp : 15|8@0+ (1,-50) [-50|204] "°C"  HUT,T_Box
 SG_ FRTirePress : 23|8@0+ (1.3725,0) [0|348.615] "kPa"  HUT,T_Box
 SG_ FRTireTemp : 31|8@0+ (1,-50) [-50|204] "°C"  HUT,T_Box
 SG_ RLTirePress : 39|8@0+ (1.3725,0) [0|348.615] "kPa"  HUT,T_Box
 SG_ RLTireTemp : 47|8@0+ (1,-50) [-50|204] "°C"  HUT,T_Box
 SG_ RRTirePress : 55|8@0+ (1.3725,0) [0|348.615] "kPa"  HUT,T_Box
 SG_ RRTireTemp : 63|8@0+ (1,-50) [-50|204] "°C"  HUT,T_Box
 SG_ FreshnessValue_TPMS2 : 71|16@0+ (1,0) [0|65535] ""  HUT,T_Box
 SG_ MAC_Check_TPMS2 : 87|48@0+ (1,0) [0|281474976710655] ""  HUT,T_Box

BO_ 929 AMP5_IESS1: 8 GW
 SG_ IESS_SwitchModel : 53|2@0+ (1,0) [0|3] ""  HUT

BO_ 948 TMCU_FD4: 8 GW
 SG_ TMCU_ActHvDcCurr_RM : 15|15@0+ (0.1,-1000) [-1000|1000] "A"  T_Box
 SG_ TMCU_ActHvDcVolt_RM : 31|16@0+ (0.1,0) [0|6000] "V"  T_Box
 SG_ TMCU_ActTemp_RM : 47|8@0+ (1,-40) [-40|210] "°C"  T_Box
 SG_ TMCU_Tempwarning_RM : 54|1@0+ (1,0) [0|1] ""  T_Box
 SG_ TMCU_InvTempwarning_RM : 55|1@0+ (1,0) [0|1] ""  T_Box
 SG_ TMCU_OperMode_RM : 51|8@0+ (1,0) [0|255] ""  T_Box

BO_ 949 ECM19: 8 GW
 SG_ ECM_VIN : 7|64@0+ (1,0) [0|1.84467440737096E+019] ""  HUT

BO_ 951 ECM20: 8 GW
 SG_ ECM_VehDstBackup : 7|24@0+ (0.1,0) [0|999999.9] "Km"  HUT
 SG_ EngRoStrt_Failure : 47|11@0+ (1,0) [0|2047] ""  T_Box

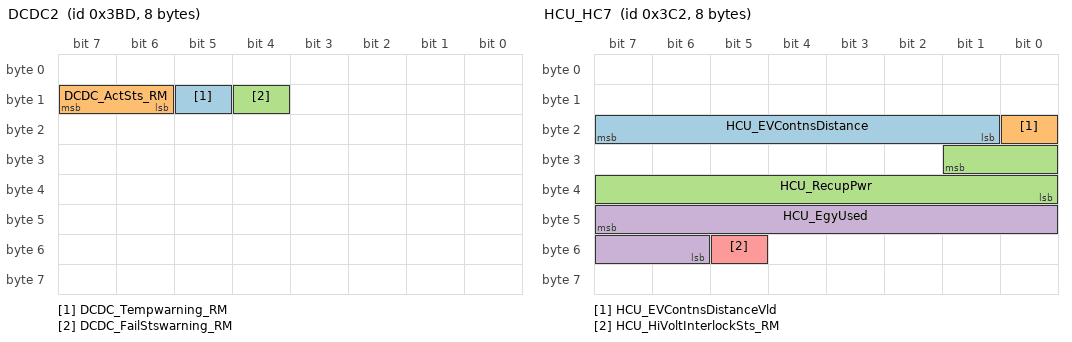
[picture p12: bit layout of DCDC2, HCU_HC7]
BO_ 957 DCDC2: 8 GW
 SG_ DCDC_Tempwarning_RM : 13|1@0+ (1,0) [0|1] ""  T_Box
 SG_ DCDC_ActSts_RM : 15|2@0+ (1,0) [0|3] ""  T_Box
 SG_ DCDC_FailStswarning_RM : 12|1@0+ (1,0) [0|1] ""  T_Box

BO_ 959 BMS22: 8 GW
 SG_ BMS_ChrgDurationTime : 47|10@0+ (1,0) [0|1022] "minute"  HUT

BO_ 962 HCU_HC7: 8 GW
 SG_ HCU_EVContnsDistance : 23|7@0+ (1,0) [0|100] "Km"  HUT,T_Box
 SG_ HCU_EVContnsDistanceVld : 16|1@0+ (1,0) [0|1] ""  HUT
 SG_ HCU_RecupPwr : 25|10@0+ (10,0) [0|10230] "Wh"  HUT
 SG_ HCU_EgyUsed : 47|10@0+ (0.01,0) [0|10.23] "KWh"  HUT
 SG_ HCU_HiVoltInterlockSts_RM : 53|1@0+ (1,0) [0|1] ""  T_Box

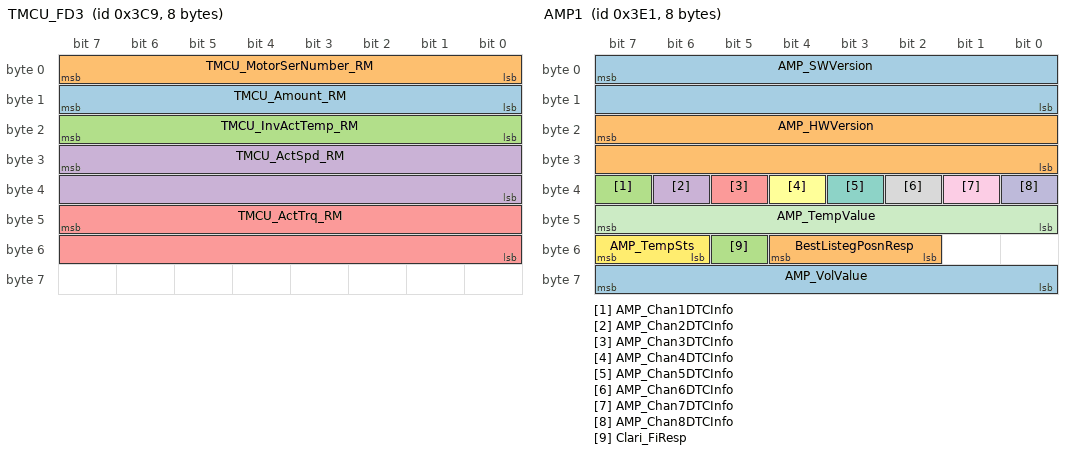
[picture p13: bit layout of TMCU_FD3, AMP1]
BO_ 969 TMCU_FD3: 8 GW
 SG_ TMCU_Amount_RM : 15|8@0+ (1,0) [1|253] ""  T_Box
 SG_ TMCU_MotorSerNumber_RM : 7|8@0+ (1,0) [1|253] ""  T_Box
 SG_ TMCU_InvActTemp_RM : 23|8@0+ (1,-40) [-40|210] "°C"  T_Box
 SG_ TMCU_ActSpd_RM : 31|16@0+ (1,-20000) [-20000|45531] "rpm"  T_Box
 SG_ TMCU_ActTrq_RM : 47|16@0+ (0.1,-2000) [-2000|4553.1] "Nm"  T_Box

BO_ 976 BMS26: 8 GW
 SG_ BMS_BattTempMax : 15|8@0+ (1,-40) [-40|125] "°C"  T_Box
 SG_ BMS_BattTempMin : 23|8@0+ (1,-40) [-40|125] "°C"  T_Box

BO_ 977 BMS_FD5: 64 GW
 SG_ BMS_BattModuleTe_11 : 135|8@0+ (1,-40) [-40|125] "°C"  T_Box
 SG_ BMS_BattModuleTe_12 : 143|8@0+ (1,-40) [-40|125] "°C"  T_Box
 SG_ BMS_BattModuleTe_21 : 151|8@0+ (1,-40) [-40|125] "°C"  T_Box
 SG_ BMS_BattModuleTe_22 : 159|8@0+ (1,-40) [-40|125] "°C"  T_Box
 SG_ BMS_BattModuleTe_31 : 167|8@0+ (1,-40) [-40|125] "°C"  T_Box
 SG_ BMS_BattModuleTe_32 : 175|8@0+ (1,-40) [-40|125] "°C"  T_Box
 SG_ BMS_BattModuleTe_41 : 183|8@0+ (1,-40) [-40|125] "°C"  T_Box
 SG_ BMS_BattModuleTe_42 : 191|8@0+ (1,-40) [-40|125] "°C"  T_Box
 SG_ BMS_BattModuleTe_51 : 71|8@0+ (1,-40) [-40|125] "oC"  T_Box
 SG_ BMS_BattModuleTe_52 : 79|8@0+ (1,-40) [-40|125] "oC"  T_Box
 SG_ BMS_BattModuleTe_61 : 87|8@0+ (1,-40) [-40|125] "oC"  T_Box
 SG_ BMS_BattModuleTe_62 : 95|8@0+ (1,-40) [-40|125] "oC"  T_Box
 SG_ BMS_BattModuleTe_71 : 103|8@0+ (1,-40) [-40|125] "oC"  T_Box
 SG_ BMS_BattModuleTe_72 : 111|8@0+ (1,-40) [-40|125] "oC"  T_Box
 SG_ BMS_BattModuleTe_81 : 119|8@0+ (1,-40) [-40|125] "oC"  T_Box
 SG_ BMS_BattModuleTe_82 : 127|8@0+ (1,-40) [-40|125] "oC"  T_Box
 SG_ BMS_SingleCellVolt_1 : 263|16@0+ (0.001,0) [0|60] "V"  T_Box
 SG_ BMS_SingleCellVolt_2 : 279|16@0+ (0.001,0) [0|60] "V"  T_Box
 SG_ BMS_SingleCellVolt_3 : 295|16@0+ (0.001,0) [0|60] "V"  T_Box
 SG_ BMS_SingleCellVolt_4 : 311|16@0+ (0.001,0) [0|60] "V"  T_Box
 SG_ BMS_SingleCellVolt_5 : 327|16@0+ (0.001,0) [0|60] "V"  T_Box
 SG_ BMS_SingleCellVolt_6 : 343|16@0+ (0.001,0) [0|60] "V"  T_Box
 SG_ BMS_SingleCellVolt_7 : 359|16@0+ (0.001,0) [0|60] "V"  T_Box
 SG_ BMS_SingleCellVolt_8 : 375|16@0+ (0.001,0) [0|60] "V"  T_Box
 SG_ BMS_SingleCellVolt_9 : 391|16@0+ (0.001,0) [0|60] "V"  T_Box
 SG_ BMS_SingleCellVolt_10 : 407|16@0+ (0.001,0) [0|60] "V"  T_Box
 SG_ BMS_SingleCellVolt_11 : 423|16@0+ (0.001,0) [0|60] "V"  T_Box
 SG_ BMS_SingleCellVolt_12 : 439|16@0+ (0.001,0) [0|60] "V"  T_Box

BO_ 978 BMS_FD6: 64 GW
 SG_ BMS_SingleCellVolt_13 : 7|16@0+ (0.001,0) [0|60] "V"  T_Box
 SG_ BMS_SingleCellVolt_14 : 23|16@0+ (0.001,0) [0|60] "V"  T_Box
 SG_ BMS_SingleCellVolt_15 : 39|16@0+ (0.001,0) [0|60] "V"  T_Box
 SG_ BMS_SingleCellVolt_16 : 55|16@0+ (0.001,0) [0|60] "V"  T_Box
 SG_ BMS_SingleCellVolt_17 : 71|16@0+ (0.001,0) [0|60] "V"  T_Box
 SG_ BMS_SingleCellVolt_18 : 87|16@0+ (0.001,0) [0|60] "V"  T_Box
 SG_ BMS_SingleCellVolt_19 : 103|16@0+ (0.001,0) [0|60] "V"  T_Box
 SG_ BMS_SingleCellVolt_20 : 119|16@0+ (0.001,0) [0|60] "V"  T_Box
 SG_ BMS_SingleCellVolt_21 : 135|16@0+ (0.001,0) [0|60] "V"  T_Box
 SG_ BMS_SingleCellVolt_22 : 151|16@0+ (0.001,0) [0|60] "V"  T_Box
 SG_ BMS_SingleCellVolt_23 : 167|16@0+ (0.001,0) [0|60] "V"  T_Box
 SG_ BMS_SingleCellVolt_24 : 183|16@0+ (0.001,0) [0|60] "V"  T_Box
 SG_ BMS_SingleCellVolt_25 : 199|16@0+ (0.001,0) [0|60] "V"  T_Box
 SG_ BMS_SingleCellVolt_26 : 215|16@0+ (0.001,0) [0|60] "V"  T_Box
 SG_ BMS_SingleCellVolt_27 : 231|16@0+ (0.001,0) [0|60] "V"  T_Box
 SG_ BMS_SingleCellVolt_28 : 247|16@0+ (0.001,0) [0|60] "V"  T_Box
 SG_ BMS_SingleCellVolt_29 : 263|16@0+ (0.001,0) [0|60] "V"  T_Box
 SG_ BMS_SingleCellVolt_30 : 279|16@0+ (0.001,0) [0|60] "V"  T_Box
 SG_ BMS_SingleCellVolt_31 : 295|16@0+ (0.001,0) [0|60] "V"  T_Box
 SG_ BMS_SingleCellVolt_32 : 311|16@0+ (0.001,0) [0|60] "V"  T_Box
 SG_ BMS_SingleCellVolt_33 : 327|16@0+ (0.001,0) [0|60] "V"  T_Box
 SG_ BMS_SingleCellVolt_34 : 343|16@0+ (0.001,0) [0|60] "V"  T_Box
 SG_ BMS_SingleCellVolt_35 : 359|16@0+ (0.001,0) [0|60] "V"  T_Box
 SG_ BMS_SingleCellVolt_36 : 375|16@0+ (0.001,0) [0|60] "V"  T_Box
 SG_ BMS_SingleCellVolt_37 : 391|16@0+ (0.001,0) [0|60] "V"  T_Box
 SG_ BMS_SingleCellVolt_38 : 407|16@0+ (0.001,0) [0|60] "V"  T_Box
 SG_ BMS_SingleCellVolt_39 : 423|16@0+ (0.001,0) [0|60] "V"  T_Box
 SG_ BMS_SingleCellVolt_40 : 439|16@0+ (0.001,0) [0|60] "V"  T_Box

BO_ 979 BMS_FD7: 64 GW
 SG_ BMS_SingleCellVolt_41 : 7|16@0+ (0.001,0) [0|60] "V"  T_Box
 SG_ BMS_SingleCellVolt_42 : 23|16@0+ (0.001,0) [0|60] "V"  T_Box
 SG_ BMS_SingleCellVolt_43 : 39|16@0+ (0.001,0) [0|60] "V"  T_Box
 SG_ BMS_SingleCellVolt_44 : 55|16@0+ (0.001,0) [0|60] "V"  T_Box
 SG_ BMS_SingleCellVolt_45 : 71|16@0+ (0.001,0) [0|60] "V"  T_Box
 SG_ BMS_SingleCellVolt_46 : 87|16@0+ (0.001,0) [0|60] "V"  T_Box
 SG_ BMS_SingleCellVolt_47 : 103|16@0+ (0.001,0) [0|60] "V"  T_Box
 SG_ BMS_SingleCellVolt_48 : 119|16@0+ (0.001,0) [0|60] "V"  T_Box
 SG_ BMS_SingleCellVolt_49 : 135|16@0+ (0.001,0) [0|60] "V"  T_Box
 SG_ BMS_SingleCellVolt_50 : 151|16@0+ (0.001,0) [0|60] "V"  T_Box
 SG_ BMS_SingleCellVolt_51 : 167|16@0+ (0.001,0) [0|60] "V"  T_Box
 SG_ BMS_SingleCellVolt_52 : 183|16@0+ (0.001,0) [0|60] "V"  T_Box
 SG_ BMS_SingleCellVolt_53 : 199|16@0+ (0.001,0) [0|60] "V"  T_Box
 SG_ BMS_SingleCellVolt_54 : 215|16@0+ (0.001,0) [0|60] "V"  T_Box
 SG_ BMS_SingleCellVolt_55 : 231|16@0+ (0.001,0) [0|60] "V"  T_Box
 SG_ BMS_SingleCellVolt_56 : 247|16@0+ (0.001,0) [0|60] "V"  T_Box
 SG_ BMS_SingleCellVolt_57 : 263|16@0+ (0.001,0) [0|60] "V"  T_Box
 SG_ BMS_SingleCellVolt_58 : 279|16@0+ (0.001,0) [0|60] "V"  T_Box
 SG_ BMS_SingleCellVolt_59 : 295|16@0+ (0.001,0) [0|60] "V"  T_Box
 SG_ BMS_SingleCellVolt_60 : 311|16@0+ (0.001,0) [0|60] "V"  T_Box
 SG_ BMS_SingleCellVolt_61 : 327|16@0+ (0.001,0) [0|60] "V"  T_Box
 SG_ BMS_SingleCellVolt_62 : 343|16@0+ (0.001,0) [0|60] "V"  T_Box
 SG_ BMS_SingleCellVolt_63 : 359|16@0+ (0.001,0) [0|60] "V"  T_Box
 SG_ BMS_SingleCellVolt_64 : 375|16@0+ (0.001,0) [0|60] "V"  T_Box
 SG_ BMS_SingleCellVolt_65 : 391|16@0+ (0.001,0) [0|60] "V"  T_Box
 SG_ BMS_SingleCellVolt_66 : 407|16@0+ (0.001,0) [0|60] "V"  T_Box
 SG_ BMS_SingleCellVolt_67 : 423|16@0+ (0.001,0) [0|60] "V"  T_Box
 SG_ BMS_SingleCellVolt_68 : 439|16@0+ (0.001,0) [0|60] "V"  T_Box

BO_ 980 BMS_FD8: 64 GW
 SG_ BMS_SingleCellVolt_69 : 7|16@0+ (0.001,0) [0|60] "V"  T_Box
 SG_ BMS_SingleCellVolt_70 : 23|16@0+ (0.001,0) [0|60] "V"  T_Box
 SG_ BMS_SingleCellVolt_71 : 39|16@0+ (0.001,0) [0|60] "V"  T_Box
 SG_ BMS_SingleCellVolt_72 : 55|16@0+ (0.001,0) [0|60] "V"  T_Box
 SG_ BMS_SingleCellVolt_73 : 71|16@0+ (0.001,0) [0|60] "V"  T_Box
 SG_ BMS_SingleCellVolt_74 : 87|16@0+ (0.001,0) [0|60] "V"  T_Box
 SG_ BMS_SingleCellVolt_75 : 103|16@0+ (0.001,0) [0|60] "V"  T_Box
 SG_ BMS_SingleCellVolt_76 : 119|16@0+ (0.001,0) [0|60] "V"  T_Box
 SG_ BMS_SingleCellVolt_77 : 135|16@0+ (0.001,0) [0|60] "V"  T_Box
 SG_ BMS_SingleCellVolt_78 : 151|16@0+ (0.001,0) [0|60] "V"  T_Box
 SG_ BMS_SingleCellVolt_79 : 167|16@0+ (0.001,0) [0|60] "V"  T_Box
 SG_ BMS_SingleCellVolt_80 : 183|16@0+ (0.001,0) [0|60] "V"  T_Box
 SG_ BMS_SingleCellVolt_81 : 199|16@0+ (0.001,0) [0|60] "V"  T_Box
 SG_ BMS_SingleCellVolt_82 : 215|16@0+ (0.001,0) [0|60] "V"  T_Box
 SG_ BMS_SingleCellVolt_83 : 231|16@0+ (0.001,0) [0|60] "V"  T_Box
 SG_ BMS_SingleCellVolt_84 : 247|16@0+ (0.001,0) [0|60] "V"  T_Box
 SG_ BMS_SingleCellVolt_85 : 263|16@0+ (0.001,0) [0|60] "V"  T_Box
 SG_ BMS_SingleCellVolt_86 : 279|16@0+ (0.001,0) [0|60] "V"  T_Box
 SG_ BMS_SingleCellVolt_87 : 295|16@0+ (0.001,0) [0|60] "V"  T_Box
 SG_ BMS_SingleCellVolt_88 : 311|16@0+ (0.001,0) [0|60] "V"  T_Box
 SG_ BMS_SingleCellVolt_89 : 327|16@0+ (0.001,0) [0|60] "V"  T_Box
 SG_ BMS_SingleCellVolt_90 : 343|16@0+ (0.001,0) [0|60] "V"  T_Box
 SG_ BMS_SingleCellVolt_91 : 359|16@0+ (0.001,0) [0|60] "V"  T_Box
 SG_ BMS_SingleCellVolt_92 : 375|16@0+ (0.001,0) [0|60] "V"  T_Box
 SG_ BMS_SingleCellVolt_93 : 391|16@0+ (0.001,0) [0|60] "V"  T_Box
 SG_ BMS_SingleCellVolt_94 : 407|16@0+ (0.001,0) [0|60] "V"  T_Box
 SG_ BMS_SingleCellVolt_95 : 423|16@0+ (0.001,0) [0|60] "V"  T_Box
 SG_ BMS_SingleCellVolt_96 : 439|16@0+ (0.001,0) [0|60] "V"  T_Box

BO_ 981 BMS_FD9: 64 GW
 SG_ BMS_SingleCellVolt_97 : 7|16@0+ (0.001,0) [0|60] "V"  T_Box
 SG_ BMS_SingleCellVolt_98 : 23|16@0+ (0.001,0) [0|60] "V"  T_Box
 SG_ BMS_SingleCellVolt_99 : 39|16@0+ (0.001,0) [0|60] "V"  T_Box
 SG_ BMS_SingleCellVolt_100 : 55|16@0+ (0.001,0) [0|60] "V"  T_Box
 SG_ BMS_SingleCellVolt_101 : 71|16@0+ (0.001,0) [0|60] "V"  T_Box
 SG_ BMS_SingleCellVolt_102 : 87|16@0+ (0.001,0) [0|60] "V"  T_Box
 SG_ BMS_SingleCellVolt_103 : 103|16@0+ (0.001,0) [0|60] "V"  T_Box
 SG_ BMS_SingleCellVolt_104 : 119|16@0+ (0.001,0) [0|60] "V"  T_Box
 SG_ BMS_SingleCellVolt_105 : 135|16@0+ (0.001,0) [0|60] "V"  T_Box
 SG_ BMS_SingleCellVolt_106 : 151|16@0+ (0.001,0) [0|60] "V"  T_Box
 SG_ BMS_SingleCellVolt_107 : 167|16@0+ (0.001,0) [0|60] "V"  T_Box
 SG_ BMS_SingleCellVolt_108 : 183|16@0+ (0.001,0) [0|60] "V"  T_Box
 SG_ BMS_SingleCellVolt_109 : 199|16@0+ (0.001,0) [0|60] "V"  T_Box
 SG_ BMS_SingleCellVolt_110 : 215|16@0+ (0.001,0) [0|60] "V"  T_Box
 SG_ BMS_SingleCellVolt_111 : 231|16@0+ (0.001,0) [0|60] "V"  T_Box
 SG_ BMS_SingleCellVolt_112 : 247|16@0+ (0.001,0) [0|60] "V"  T_Box
 SG_ BMS_BattModuleTe_91 : 263|8@0+ (1,-40) [-40|125] "°C"  T_Box
 SG_ BMS_BattModuleTe_92 : 271|8@0+ (1,-40) [-40|125] "°C"  T_Box
 SG_ BMS_DTCNumber : 279|9@0+ (1,0) [0|501] ""  T_Box
 SG_ BMS_SWVersion_PHEV : 286|16@0+ (1,0) [0|65535] ""  T_Box
 SG_ BMS_NumberCellVoltMin_RM : 311|8@0+ (1,0) [1|250] ""  T_Box
 SG_ BMS_ModuleMaxTemp_RM : 319|8@0+ (1,-40) [-40|210] "℃"  T_Box

BO_ 993 AMP1: 8 GW
 SG_ AMP_SWVersion : 7|16@0+ (1,0) [0|65535] ""  HUT
 SG_ AMP_HWVersion : 23|16@0+ (1,0) [0|65535] ""  HUT
 SG_ AMP_Chan1DTCInfo : 39|1@0+ (1,0) [0|1] ""  HUT
 SG_ AMP_Chan2DTCInfo : 38|1@0+ (1,0) [0|1] ""  HUT
 SG_ AMP_Chan3DTCInfo : 37|1@0+ (1,0) [0|1] ""  HUT
 SG_ AMP_Chan4DTCInfo : 36|1@0+ (1,0) [0|1] ""  HUT
 SG_ AMP_Chan5DTCInfo : 35|1@0+ (1,0) [0|1] ""  HUT
 SG_ AMP_Chan6DTCInfo : 34|1@0+ (1,0) [0|1] ""  HUT
 SG_ AMP_Chan7DTCInfo : 33|1@0+ (1,0) [0|1] ""  HUT
 SG_ AMP_Chan8DTCInfo : 32|1@0+ (1,0) [0|1] ""  HUT
 SG_ AMP_TempValue : 47|8@0+ (1,-50) [-50|204] ""  HUT
 SG_ AMP_TempSts : 55|2@0+ (1,0) [0|3] ""  HUT
 SG_ AMP_VolValue : 63|8@0+ (0.1,0) [0|25.5] ""  HUT
 SG_ BestListegPosnResp : 52|3@0+ (1,0) [0|7] ""  HUT
 SG_ Clari_FiResp : 53|1@0+ (1,0) [0|1] ""  HUT

BO_ 995 AMP2: 16 GW
 SG_ MediaCallSourceState : 7|4@0+ (1,0) [0|15] ""  HUT
 SG_ BeepSourceSts : 2|3@0+ (1,0) [0|7] ""  HUT
 SG_ BalanceSetState : 15|5@0+ (1,0) [0|20] ""  HUT
 SG_ VSCModeState : 9|2@0+ (1,0) [0|3] ""  HUT
 SG_ FadeSetState : 23|5@0+ (1,0) [0|20] ""  HUT
 SG_ DriveSideSts : 17|1@0+ (1,0) [0|1] ""  HUT
 SG_ BassSetState : 31|5@0+ (1,0) [0|20] ""  HUT
 SG_ MuteState : 25|1@0+ (1,0) [0|1] ""  HUT
 SG_ NaviSourceState : 39|3@0+ (1,0) [0|7] ""  HUT
 SG_ MidrangeSetState : 47|5@0+ (1,0) [0|20] ""  HUT
 SG_ T_box_ECallSts : 42|1@0+ (1,0) [0|1] ""  HUT
 SG_ GetHUTInfoSts : 41|1@0+ (1,0) [0|1] ""  HUT
 SG_ TrebleSetState : 55|5@0+ (1,0) [0|20] ""  HUT
 SG_ QLISurroundSetSt : 49|1@0+ (1,0) [0|1] ""  HUT
 SG_ AVMStResp : 3|1@0+ (1,0) [0|1] ""  HUT
 SG_ NaviMediaVolLvlResp : 63|4@0+ (1,0) [0|15] ""  HUT
 SG_ AVMMediaVolLvlResp : 59|4@0+ (1,0) [0|15] ""  HUT
 SG_ FPASChStResp : 10|1@0+ (1,0) [0|1] ""  HUT
 SG_ RPASChStResp : 18|1@0+ (1,0) [0|1] ""  HUT
 SG_ FreshnessValue_AMP2 : 71|16@0+ (1,0) [0|65535] ""  HUT
 SG_ MAC_Check_AMP2 : 87|48@0+ (1,0) [0|281474976710655] ""  HUT

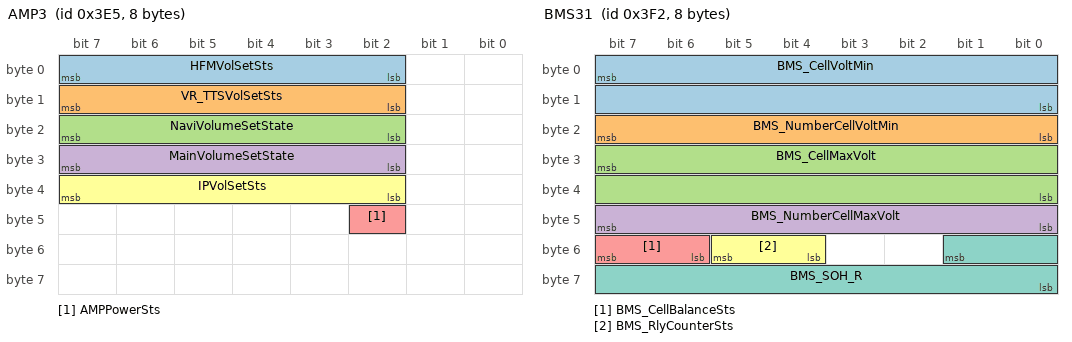
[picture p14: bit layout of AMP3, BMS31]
BO_ 997 AMP3: 8 GW
 SG_ HFMVolSetSts : 7|6@0+ (1,0) [0|39] ""  HUT
 SG_ VR_TTSVolSetSts : 15|6@0+ (1,0) [0|39] ""  HUT
 SG_ NaviVolumeSetState : 23|6@0+ (1,0) [0|39] ""  HUT
 SG_ MainVolumeSetState : 31|6@0+ (1,0) [0|39] ""  HUT
 SG_ AMPPowerSts : 42|1@0+ (1,0) [0|1] ""  HUT
 SG_ IPVolSetSts : 39|6@0+ (1,0) [0|39] ""  HUT

BO_ 1001 T_Box_FD3: 16 T_Box
 SG_ T_Box_SWUpdSts : 18|3@0+ (1,0) [0|7] ""  HUT
 SG_ T_Box_SysErrSts : 7|5@0+ (1,0) [0|1] ""  GW,HUT
 SG_ FreshnessValue_T_Box_FD3 : 71|16@0+ (1,0) [0|65535] ""  GW,HUT
 SG_ MAC_Check_T_Box_FD3 : 87|48@0+ (1,0) [0|281474976710655] ""  GW,HUT

BO_ 1008 BMS_FD12: 64 GW
 SG_ BMS_CellMaxVolt_RM : 327|16@0+ (0.001,0) [0|15] "V"  T_Box
 SG_ BMS_CellVoltMin_RM : 343|16@0+ (0.001,0) [0|15] "V"  T_Box
 SG_ BMS_NumCellMaxTemp_RM : 359|8@0+ (1,0) [1|250] ""  T_Box
 SG_ BMS_NumCellMinTemp_RM : 367|8@0+ (1,0) [1|250] ""  T_Box
 SG_ BMS_ModuleMinTemp_RM : 375|8@0+ (1,-40) [-40|210] "℃"  T_Box
 SG_ BMS_NumberCellVoltMax_RM : 383|8@0+ (1,0) [1|250] ""  T_Box
 SG_ BMS_SocJumpWarn_RM : 391|1@0+ (1,0) [0|1] ""  T_Box
 SG_ BMS_PackOverChrgWarn_RM : 390|1@0+ (1,0) [0|1] ""  T_Box
 SG_ BMS_IsolationRValue_RM : 399|16@0+ (1,0) [0|60000] "Kohm"  T_Box
 SG_ BMS_PackCurr_RM : 415|15@0+ (0.1,-1000) [-1000|1000] "A"  T_Box
 SG_ BMS_SocOverWarn_RM : 416|1@0+ (1,0) [0|1] ""  T_Box
 SG_ BMS_BattOverTempRank_RM : 431|1@0+ (1,0) [0|1] ""  T_Box
 SG_ BMS_BattOverVoltRank_RM : 430|1@0+ (1,0) [0|1] ""  T_Box
 SG_ BMS_BattSOCLowRank_RM : 429|1@0+ (1,0) [0|1] ""  T_Box
 SG_ BMS_VCUIsolateErr_RM : 428|1@0+ (1,0) [0|1] ""  T_Box
 SG_ BMS_BattUnderVoltRank_RM : 427|1@0+ (1,0) [0|1] ""  T_Box
 SG_ BMS_CellDeltaVoltRank_RM : 426|1@0+ (1,0) [0|1] ""  T_Box
 SG_ BMS_CellOverVoltRank_RM : 425|1@0+ (1,0) [0|1] ""  T_Box
 SG_ BMS_CellUnderVoltRank_RM : 424|1@0+ (1,0) [0|1] ""  T_Box
 SG_ BMS_DeltaTempRank_RM : 439|1@0+ (1,0) [0|1] ""  T_Box
 SG_ BMS_PackMismatchWarn_RM : 438|1@0+ (1,0) [0|1] ""  T_Box
 SG_ BMS_PackVolt_RM : 437|14@0+ (0.1,0) [0|1000] "V"  T_Box
 SG_ BMS_SysNumberCellVoltMax_RM : 455|8@0+ (1,0) [1|250] ""  T_Box
 SG_ BMS_SysNumberCellVoltMin_RM : 463|8@0+ (1,0) [1|250] ""  T_Box
 SG_ BMS_SysNumCellMaxTemp_RM : 471|8@0+ (1,0) [0|250] ""  T_Box
 SG_ BMS_SysNumCellMinTemp_RM : 479|8@0+ (1,0) [0|250] ""  T_Box
 SG_ BMS_BattSysNum_RM : 487|8@0+ (1,0) [0|250] ""  T_Box

BO_ 1009 BMS30: 8 GW
 SG_ BMS_CellUnderVolt : 15|1@0+ (1,0) [0|1] ""  T_Box
 SG_ BMS_CellOverVolt : 14|1@0+ (1,0) [0|1] ""  T_Box
 SG_ BMS_CellDeltaVolt : 13|1@0+ (1,0) [0|1] ""  T_Box
 SG_ BMS_BattUnderVolt : 12|1@0+ (1,0) [0|1] ""  T_Box
 SG_ BMS_BattOverVolt : 11|1@0+ (1,0) [0|1] ""  T_Box
 SG_ BMS_BattUnderTemp : 10|1@0+ (1,0) [0|1] ""  T_Box
 SG_ BMS_SOC_Plaucheck : 9|1@0+ (1,0) [0|1] ""  T_Box
 SG_ BMS_DeltaTemp : 8|1@0+ (1,0) [0|1] ""  T_Box
 SG_ BMS_CANComErr : 23|1@0+ (1,0) [0|1] ""  T_Box
 SG_ BMS_SOCLowWarn : 31|1@0+ (1,0) [0|1] ""  HUT
 SG_ BMS_BattSOCLow : 22|1@0+ (1,0) [0|1] ""  T_Box
 SG_ BMS_BattSOCTooLow : 21|1@0+ (1,0) [0|1] ""  T_Box
 SG_ BMS_BattSOCHigh : 20|1@0+ (1,0) [0|1] ""  T_Box
 SG_ BMS_ChrgnCurrLager : 19|1@0+ (1,0) [0|1] ""  T_Box
 SG_ BMS_DischrgnCurrLager : 18|1@0+ (1,0) [0|1] ""  T_Box
 SG_ BMS_ModuleMismatchWarn : 17|1@0+ (1,0) [0|1] ""  T_Box
 SG_ BMS_cohrnc : 16|1@0+ (1,0) [0|1] ""  T_Box
 SG_ BMS_moduleNumber : 43|4@0+ (1,1) [1|8] ""  T_Box
 SG_ BMS_NumModuleTempSnsr : 28|5@0+ (1,1) [1|15] ""  T_Box
 SG_ BMS_NumCell : 39|8@0+ (1,1) [1|108] ""  T_Box

BO_ 1010 BMS31: 8 GW
 SG_ BMS_CellVoltMin : 7|16@0+ (0.001,0) [0|5] "V"  T_Box
 SG_ BMS_NumberCellVoltMin : 23|8@0+ (1,1) [1|108] ""  T_Box
 SG_ BMS_CellMaxVolt : 31|16@0+ (0.001,0) [0|5] "V"  T_Box
 SG_ BMS_NumberCellMaxVolt : 47|8@0+ (1,1) [1|108] ""  T_Box
 SG_ BMS_CellBalanceSts : 55|2@0+ (1,0) [0|1] ""  T_Box
 SG_ BMS_RlyCounterSts : 53|2@0+ (1,0) [0|3] ""  T_Box
 SG_ BMS_SOH_R : 49|10@0+ (0.1,100) [100|200] "%"  T_Box

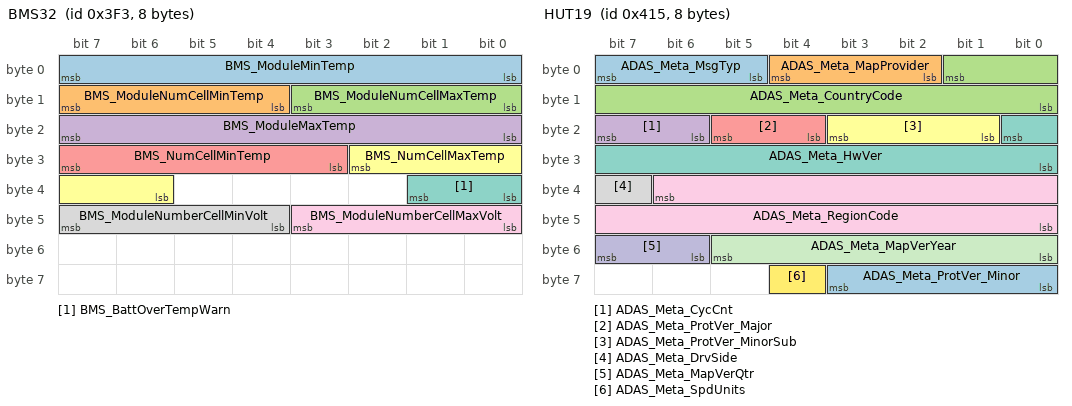
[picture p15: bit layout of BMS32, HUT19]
BO_ 1011 BMS32: 8 GW
 SG_ BMS_ModuleMinTemp : 7|8@0+ (1,-40) [-40|90] "oC"  T_Box
 SG_ BMS_ModuleNumCellMinTemp : 15|4@0+ (1,1) [1|9] ""  T_Box
 SG_ BMS_ModuleNumCellMaxTemp : 11|4@0+ (1,1) [1|9] ""  T_Box
 SG_ BMS_ModuleMaxTemp : 23|8@0+ (1,-40) [-40|90] "oC"  T_Box
 SG_ BMS_NumCellMinTemp : 31|5@0+ (1,1) [1|18] "_"  T_Box
 SG_ BMS_NumCellMaxTemp : 26|5@0+ (1,1) [1|18] "_"  T_Box
 SG_ BMS_BattOverTempWarn : 33|2@0+ (1,0) [0|3] ""  T_Box
 SG_ BMS_ModuleNumberCellMinVolt : 47|4@0+ (1,1) [1|9] ""  T_Box
 SG_ BMS_ModuleNumberCellMaxVolt : 43|4@0+ (1,1) [1|9] ""  T_Box

BO_ 1045 HUT19: 8 HUT
 SG_ ADAS_Meta_MsgTyp : 7|3@0+ (1,0) [0|7] ""  GW
 SG_ ADAS_Meta_MapProvider : 4|3@0+ (1,0) [0|7] ""  GW
 SG_ ADAS_Meta_CountryCode : 1|10@0+ (1,0) [0|1023] ""  GW
 SG_ ADAS_Meta_CycCnt : 23|2@0+ (1,0) [0|3] ""  GW
 SG_ ADAS_Meta_ProtVer_Major : 21|2@0+ (1,0) [0|3] ""  GW
 SG_ ADAS_Meta_ProtVer_MinorSub : 19|3@0+ (1,0) [0|7] ""  GW
 SG_ ADAS_Meta_HwVer : 16|9@0+ (1,0) [0|511] ""  GW
 SG_ ADAS_Meta_DrvSide : 39|1@0+ (1,0) [0|1] ""  GW
 SG_ ADAS_Meta_RegionCode : 38|15@0+ (1,0) [0|32767] ""  GW
 SG_ ADAS_Meta_MapVerQtr : 55|2@0+ (1,0) [0|3] ""  GW
 SG_ ADAS_Meta_MapVerYear : 53|6@0+ (1,0) [0|63] ""  GW
 SG_ ADAS_Meta_SpdUnits : 60|1@0+ (1,0) [0|1] ""  GW
 SG_ ADAS_Meta_ProtVer_Minor : 59|4@0+ (1,0) [0|15] ""  GW

BO_ 1290 T_Box_NM: 8 T_Box
 SG_ Destination_T_Box_NM : 7|8@0+ (1,0) [0|63] ""  GW,HUT,DMS,DVR
 SG_ OpCode_T_Box_NM : 15|8@0+ (1,0) [0|63] ""  GW,HUT,DMS,DVR

BO_ 1289 HUT_NM: 8 HUT
 SG_ Destination_HUT_NM : 7|8@0+ (1,0) [0|63] ""  GW,T_Box,DMS,DVR
 SG_ OpCode_HUT_NM : 15|8@0+ (1,0) [0|63] ""  GW,T_Box,DMS,DVR

BO_ 1302 DMS_NM: 8 DMS
 SG_ Destination_DMS_NM : 7|8@0+ (1,0) [0|63] ""  GW,T_Box,HUT,DVR
 SG_ OpCode_DMS_NM : 15|8@0+ (1,0) [0|63] ""  GW,T_Box,HUT,DVR

BO_ 1303 DVR_NM: 8 DVR
 SG_ Destination_DVR_NM : 7|8@0+ (1,0) [0|63] ""  GW,T_Box,HUT,DMS
 SG_ OpCode_DVR_NM : 15|8@0+ (1,0) [0|63] ""  GW,T_Box,HUT,DMS

BO_ 1281 GW_NM: 8 GW
 SG_ Destination_GW_NM : 7|8@0+ (1,0) [0|63] ""  T_Box,HUT,DMS,DVR
 SG_ OpCode_GW_NM : 15|8@0+ (1,0) [0|63] ""  T_Box,HUT,DMS,DVR

BO_ 1888 DiagFuncReq: 8 Tester
 SG_ DiagFuncReq : 7|64@0+ (1,0) [0|1.84467440737096E+019] ""  GW,T_Box,HUT,DMS,DVR

BO_ 1889 GW_Phy_Req: 8 Tester
 SG_ GW_Phy_Req : 7|64@0+ (1,0) [0|1.84467440737096E+019] ""  GW

BO_ 1918 T_Box_Phy_Req: 8 Tester
 SG_ T_Box_Phy_Req : 7|64@0+ (1,0) [0|1.84467440737096E+019] ""  GW,T_Box

BO_ 1907 HUT_Phy_Req: 8 Tester
 SG_ HUT_Phy_Req : 7|64@0+ (1,0) [0|1.84467440737096E+019] ""  GW,HUT

BO_ 1566 DMS_Phy_Req: 8 Tester
 SG_ DMS_Phy_Req : 7|64@0+ (1,0) [0|1.84467440737096E+019] ""  GW,DMS

BO_ 1560 DVR_Phy_Req: 8 Tester
 SG_ DVR_Phy_Req : 7|64@0+ (1,0) [0|1.84467440737096E+019] ""  GW,DVR

BO_ 1953 GW_Phy_Resp: 8 GW
 SG_ GW_Phy_Resp : 7|64@0+ (1,0) [0|1.84467440737096E+019] ""  Tester

BO_ 1982 T_Box_Phy_Resp: 8 T_Box
 SG_ T_Box_Phy_Resp : 7|64@0+ (1,0) [0|1.84467440737096E+019] ""  GW

BO_ 1971 HUT_Phy_Resp: 8 HUT
 SG_ HUT_Phy_Resp : 7|64@0+ (1,0) [0|1.84467440737096E+019] ""  GW,Tester

BO_ 1567 DMS_Phy_Resp: 8 DMS
 SG_ DMS_Phy_Resp : 7|64@0+ (1,0) [0|1.84467440737096E+019] ""  GW,Tester

BO_ 1561 DVR_Phy_Resp: 8 DVR
 SG_ DVR_Phy_Resp : 7|64@0+ (1,0) [0|1.84467440737096E+019] ""  GW,Tester

CM_ SG_ 762 HCU_RefuReq "/";
CM_ SG_ 762 HCU_OilTankCoverSts "/";
CM_ SG_ 762 HCU_InhbChrgInfo "/";
CM_ SG_ 862 RoofModFb "QM";
CM_ SG_ 862 AllTerrainDislFb "QM";
CM_ SG_ 862 ElecSideStepSysFb "QM";
BA_DEF_ BO_  "DiagState" ENUM  "No","Yes";
BA_DEF_ BO_  "NmMessage" ENUM  "no","yes";
BA_DEF_ BO_  "GenMsgILSupport" ENUM  "No","Yes";
BA_DEF_ BO_  "GenMsgCycleTime" INT 0 65535;
BA_DEF_ BO_  "GenMsgMinAcceptLength" INT 0 8;
BA_DEF_ BO_  "GenMsgSendType" ENUM  "Cyclic","CyclicAndSpontanX","Event";
BA_DEF_ BO_  "CANFD_BRS" ENUM  "0","1";
BA_DEF_ BO_  "VFrameFormat" ENUM  "StandardCAN","ExtendedCAN","reserved","reserved","reserved","reserved","reserved","reserved","reserved","reserved","reserved","reserved","reserved","reserved","StandardCAN_FD","ExtendedCAN_FD";
BA_DEF_ SG_  "GenSigEnvVarType" ENUM  "undef","int","float";
BA_DEF_ SG_  "GenSigSendType" ENUM  "Cyclic","OnWrite","OnWriteWithRepetition","OnChange","OnChangeWithRepetition","IfActive","IfActiveWithRepetition","NoSigSendType","NotUsed","NotUsed","NotUsed","NotUsed","NotUsed";
BA_DEF_ SG_  "GenSigStartValue" FLOAT 0 1215752192;
BA_DEF_DEF_  "DiagState" "No";
BA_DEF_DEF_  "NmMessage" "no";
BA_DEF_DEF_  "GenMsgILSupport" "Yes";
BA_DEF_DEF_  "GenMsgCycleTime" 10;
BA_DEF_DEF_  "GenMsgMinAcceptLength" 8;
BA_DEF_DEF_  "GenMsgSendType" "Cyclic";
BA_DEF_DEF_  "CANFD_BRS" "1";
BA_DEF_DEF_  "VFrameFormat" "StandardCAN";
BA_DEF_DEF_  "GenSigEnvVarType" "undef";
BA_DEF_DEF_  "GenSigSendType" "Cyclic";
BA_DEF_DEF_  "GenSigStartValue" 0;
BA_ "GenMsgCycleTime" BO_ 696 100;
BA_ "VFrameFormat" BO_ 696 14;
BA_ "GenMsgCycleTime" BO_ 698 100;
BA_ "VFrameFormat" BO_ 698 14;
BA_ "GenMsgCycleTime" BO_ 699 100;
BA_ "VFrameFormat" BO_ 699 14;
BA_ "GenMsgCycleTime" BO_ 705 100;
BA_ "VFrameFormat" BO_ 705 14;
BA_ "GenMsgCycleTime" BO_ 707 100;
BA_ "VFrameFormat" BO_ 707 14;
BA_ "GenMsgCycleTime" BO_ 708 100;
BA_ "VFrameFormat" BO_ 708 14;
BA_ "GenMsgCycleTime" BO_ 714 100;
BA_ "VFrameFormat" BO_ 714 14;
BA_ "GenMsgCycleTime" BO_ 717 100;
BA_ "VFrameFormat" BO_ 717 14;
BA_ "GenMsgCycleTime" BO_ 719 100;
BA_ "VFrameFormat" BO_ 719 14;
BA_ "GenMsgCycleTime" BO_ 721 100;
BA_ "VFrameFormat" BO_ 721 14;
BA_ "GenMsgSendType" BO_ 722 2;
BA_ "GenMsgCycleTime" BO_ 722 0;
BA_ "VFrameFormat" BO_ 722 14;
BA_ "GenMsgCycleTime" BO_ 723 100;
BA_ "VFrameFormat" BO_ 723 14;
BA_ "GenMsgSendType" BO_ 728 2;
BA_ "GenMsgCycleTime" BO_ 728 0;
BA_ "VFrameFormat" BO_ 728 14;
BA_ "GenMsgSendType" BO_ 730 2;
BA_ "GenMsgCycleTime" BO_ 730 0;
BA_ "VFrameFormat" BO_ 730 14;
BA_ "GenMsgSendType" BO_ 731 2;
BA_ "GenMsgCycleTime" BO_ 731 0;
BA_ "VFrameFormat" BO_ 731 14;
BA_ "GenMsgSendType" BO_ 733 2;
BA_ "GenMsgCycleTime" BO_ 733 0;
BA_ "VFrameFormat" BO_ 733 14;
BA_ "GenMsgSendType" BO_ 734 2;
BA_ "GenMsgCycleTime" BO_ 734 0;
BA_ "VFrameFormat" BO_ 734 14;
BA_ "GenMsgCycleTime" BO_ 737 100;
BA_ "VFrameFormat" BO_ 737 14;
BA_ "GenMsgCycleTime" BO_ 748 100;
BA_ "VFrameFormat" BO_ 748 14;
BA_ "GenMsgCycleTime" BO_ 749 100;
BA_ "VFrameFormat" BO_ 749 14;
BA_ "GenMsgCycleTime" BO_ 762 100;
BA_ "VFrameFormat" BO_ 762 14;
BA_ "GenMsgCycleTime" BO_ 766 100;
BA_ "VFrameFormat" BO_ 766 14;
BA_ "GenMsgSendType" BO_ 770 1;
BA_ "GenMsgCycleTime" BO_ 770 200;
BA_ "VFrameFormat" BO_ 770 14;
BA_ "GenMsgSendType" BO_ 771 1;
BA_ "GenMsgCycleTime" BO_ 771 200;
BA_ "VFrameFormat" BO_ 771 14;
BA_ "GenMsgCycleTime" BO_ 773 100;
BA_ "VFrameFormat" BO_ 773 14;
BA_ "GenMsgCycleTime" BO_ 788 200;
BA_ "VFrameFormat" BO_ 788 14;
BA_ "GenMsgCycleTime" BO_ 790 200;
BA_ "VFrameFormat" BO_ 790 14;
BA_ "GenMsgCycleTime" BO_ 791 200;
BA_ "VFrameFormat" BO_ 791 14;
BA_ "GenMsgCycleTime" BO_ 793 50;
BA_ "VFrameFormat" BO_ 793 14;
BA_ "GenMsgCycleTime" BO_ 796 100;
BA_ "VFrameFormat" BO_ 796 14;
BA_ "GenMsgCycleTime" BO_ 805 200;
BA_ "VFrameFormat" BO_ 805 14;
BA_ "GenMsgSendType" BO_ 817 2;
BA_ "GenMsgCycleTime" BO_ 817 0;
BA_ "VFrameFormat" BO_ 817 14;
BA_ "GenMsgSendType" BO_ 825 2;
BA_ "GenMsgCycleTime" BO_ 825 0;
BA_ "VFrameFormat" BO_ 825 14;
BA_ "GenMsgSendType" BO_ 827 2;
BA_ "GenMsgCycleTime" BO_ 827 0;
BA_ "VFrameFormat" BO_ 827 14;
BA_ "GenMsgCycleTime" BO_ 833 500;
BA_ "VFrameFormat" BO_ 833 14;
BA_ "GenMsgCycleTime" BO_ 837 50;
BA_ "VFrameFormat" BO_ 837 14;
BA_ "GenMsgCycleTime" BO_ 840 500;
BA_ "VFrameFormat" BO_ 840 14;
BA_ "GenMsgCycleTime" BO_ 842 500;
BA_ "VFrameFormat" BO_ 842 14;
BA_ "GenMsgSendType" BO_ 849 1;
BA_ "GenMsgCycleTime" BO_ 849 500;
BA_ "VFrameFormat" BO_ 849 14;
BA_ "GenMsgCycleTime" BO_ 850 500;
BA_ "VFrameFormat" BO_ 850 14;
BA_ "GenMsgCycleTime" BO_ 862 500;
BA_ "VFrameFormat" BO_ 862 14;
BA_ "GenMsgSendType" BO_ 871 2;
BA_ "GenMsgCycleTime" BO_ 871 0;
BA_ "VFrameFormat" BO_ 871 14;
BA_ "GenMsgSendType" BO_ 873 2;
BA_ "GenMsgCycleTime" BO_ 873 0;
BA_ "VFrameFormat" BO_ 873 14;
BA_ "GenMsgSendType" BO_ 875 2;
BA_ "GenMsgCycleTime" BO_ 875 0;
BA_ "VFrameFormat" BO_ 875 14;
BA_ "GenMsgSendType" BO_ 877 2;
BA_ "GenMsgCycleTime" BO_ 877 0;
BA_ "VFrameFormat" BO_ 877 14;
BA_ "GenMsgCycleTime" BO_ 880 1000;
BA_ "VFrameFormat" BO_ 880 14;
BA_ "GenMsgCycleTime" BO_ 881 100;
BA_ "VFrameFormat" BO_ 881 14;
BA_ "GenMsgCycleTime" BO_ 901 100;
BA_ "VFrameFormat" BO_ 901 14;
BA_ "GenMsgCycleTime" BO_ 909 1000;
BA_ "VFrameFormat" BO_ 909 14;
BA_ "GenMsgCycleTime" BO_ 917 500;
BA_ "VFrameFormat" BO_ 917 14;
BA_ "GenMsgSendType" BO_ 929 2;
BA_ "GenMsgCycleTime" BO_ 929 0;
BA_ "VFrameFormat" BO_ 929 14;
BA_ "GenMsgCycleTime" BO_ 948 1000;
BA_ "VFrameFormat" BO_ 948 14;
BA_ "GenMsgCycleTime" BO_ 949 1000;
BA_ "VFrameFormat" BO_ 949 14;
BA_ "GenMsgCycleTime" BO_ 951 1000;
BA_ "VFrameFormat" BO_ 951 14;
BA_ "GenMsgCycleTime" BO_ 957 1000;
BA_ "VFrameFormat" BO_ 957 14;
BA_ "GenMsgCycleTime" BO_ 959 1000;
BA_ "VFrameFormat" BO_ 959 14;
BA_ "GenMsgCycleTime" BO_ 962 1000;
BA_ "VFrameFormat" BO_ 962 14;
BA_ "GenMsgCycleTime" BO_ 969 1000;
BA_ "VFrameFormat" BO_ 969 14;
BA_ "GenMsgCycleTime" BO_ 976 1000;
BA_ "VFrameFormat" BO_ 976 14;
BA_ "GenMsgCycleTime" BO_ 977 1000;
BA_ "VFrameFormat" BO_ 977 14;
BA_ "GenMsgCycleTime" BO_ 978 1000;
BA_ "VFrameFormat" BO_ 978 14;
BA_ "GenMsgCycleTime" BO_ 979 1000;
BA_ "VFrameFormat" BO_ 979 14;
BA_ "GenMsgCycleTime" BO_ 980 1000;
BA_ "VFrameFormat" BO_ 980 14;
BA_ "GenMsgCycleTime" BO_ 981 1000;
BA_ "VFrameFormat" BO_ 981 14;
BA_ "GenMsgSendType" BO_ 993 2;
BA_ "GenMsgCycleTime" BO_ 993 0;
BA_ "VFrameFormat" BO_ 993 14;
BA_ "GenMsgSendType" BO_ 995 2;
BA_ "GenMsgCycleTime" BO_ 995 0;
BA_ "VFrameFormat" BO_ 995 14;
BA_ "GenMsgSendType" BO_ 997 2;
BA_ "GenMsgCycleTime" BO_ 997 0;
BA_ "VFrameFormat" BO_ 997 14;
BA_ "GenMsgCycleTime" BO_ 1001 1000;
BA_ "VFrameFormat" BO_ 1001 14;
BA_ "GenMsgCycleTime" BO_ 1008 1000;
BA_ "VFrameFormat" BO_ 1008 14;
BA_ "GenMsgCycleTime" BO_ 1009 1000;
BA_ "VFrameFormat" BO_ 1009 14;
BA_ "GenMsgCycleTime" BO_ 1010 1000;
BA_ "VFrameFormat" BO_ 1010 14;
BA_ "GenMsgCycleTime" BO_ 1011 1000;
BA_ "VFrameFormat" BO_ 1011 14;
BA_ "GenMsgCycleTime" BO_ 1045 5000;
BA_ "VFrameFormat" BO_ 1045 14;
BA_ "GenMsgSendType" BO_ 1290 2;
BA_ "GenMsgCycleTime" BO_ 1290 0;
BA_ "NmMessage" BO_ 1290 1;
BA_ "GenMsgSendType" BO_ 1289 2;
BA_ "GenMsgCycleTime" BO_ 1289 0;
BA_ "NmMessage" BO_ 1289 1;
BA_ "GenMsgSendType" BO_ 1302 2;
BA_ "GenMsgCycleTime" BO_ 1302 0;
BA_ "NmMessage" BO_ 1302 1;
BA_ "GenMsgSendType" BO_ 1303 2;
BA_ "GenMsgCycleTime" BO_ 1303 0;
BA_ "NmMessage" BO_ 1303 1;
BA_ "GenMsgSendType" BO_ 1281 2;
BA_ "GenMsgCycleTime" BO_ 1281 0;
BA_ "NmMessage" BO_ 1281 1;
BA_ "GenMsgSendType" BO_ 1888 2;
BA_ "GenMsgCycleTime" BO_ 1888 0;
BA_ "DiagState" BO_ 1888 1;
BA_ "GenMsgSendType" BO_ 1889 2;
BA_ "GenMsgCycleTime" BO_ 1889 0;
BA_ "GenMsgSendType" BO_ 1918 2;
BA_ "GenMsgCycleTime" BO_ 1918 0;
BA_ "GenMsgSendType" BO_ 1907 2;
BA_ "GenMsgCycleTime" BO_ 1907 0;
BA_ "GenMsgSendType" BO_ 1566 2;
BA_ "GenMsgCycleTime" BO_ 1566 0;
BA_ "GenMsgSendType" BO_ 1560 2;
BA_ "GenMsgCycleTime" BO_ 1560 0;
BA_ "GenMsgSendType" BO_ 1953 2;
BA_ "GenMsgCycleTime" BO_ 1953 0;
BA_ "GenMsgSendType" BO_ 1982 2;
BA_ "GenMsgCycleTime" BO_ 1982 0;
BA_ "GenMsgSendType" BO_ 1971 2;
BA_ "GenMsgCycleTime" BO_ 1971 0;
BA_ "GenMsgSendType" BO_ 1567 2;
BA_ "GenMsgCycleTime" BO_ 1567 0;
BA_ "GenMsgSendType" BO_ 1561 2;
BA_ "GenMsgCycleTime" BO_ 1561 0;
BA_ "GenSigStartValue" SG_ 699 U_BATT 16383;
BA_ "GenSigStartValue" SG_ 699 I_RANGE 3;
BA_ "GenSigStartValue" SG_ 699 I_BATT 65535;
BA_ "GenSigStartValue" SG_ 699 SOC 255;
BA_ "GenSigStartValue" SG_ 699 SOH_SUL 255;
BA_ "GenSigStartValue" SG_ 699 SOC_STATE 3;
BA_ "GenSigStartValue" SG_ 699 SOH_SUL_STATE 3;
BA_ "GenSigStartValue" SG_ 707 SSSSet_HUT 1;
BA_ "GenSigStartValue" SG_ 707 AEB_PedSwtReq 1;
BA_ "GenSigStartValue" SG_ 707 ALCMLightLvlSet 5;
BA_ "GenSigStartValue" SG_ 707 FlashLmpSwtReq 1;
BA_ "GenSigStartValue" SG_ 707 AEB_VehSwtReq 1;
BA_ "GenSigStartValue" SG_ 707 TSR_SnvtySet 15;
BA_ "GenSigStartValue" SG_ 707 HFASwtSts 1;
BA_ "GenSigStartValue" SG_ 707 HUT_BattSOCLimSaveMod 4;
BA_ "GenSigStartValue" SG_ 707 NavSpdLimUnit_HUT 1;
BA_ "GenSigStartValue" SG_ 707 NavCtryType 156;
BA_ "GenSigStartValue" SG_ 707 ADAS_Posn_Offset 8191;
BA_ "GenSigStartValue" SG_ 707 ADAS_Posn_Spd 511;
BA_ "GenSigStartValue" SG_ 719 TSRSpdLimUnit 1;
BA_ "GenSigStartValue" SG_ 719 TSR_Snvty 15;
BA_ "GenSigSendType" SG_ 722 Microphone_Cha1DTCInfo 10;
BA_ "GenSigSendType" SG_ 722 Microphone_Cha2DTCInfo 10;
BA_ "GenSigSendType" SG_ 722 Microphone_Cha3DTCInfo 10;
BA_ "GenSigSendType" SG_ 722 Microphone_Cha4DTCInfo 10;
BA_ "GenSigSendType" SG_ 722 ANCSwtStatus 10;
BA_ "GenSigStartValue" SG_ 722 ANCSwtStatus 1;
BA_ "GenSigSendType" SG_ 728 ADAS_Stub_MsgTyp 10;
BA_ "GenSigSendType" SG_ 728 ADAS_Stub_Offset 10;
BA_ "GenSigSendType" SG_ 728 ADAS_Stub_CycCnt 10;
BA_ "GenSigSendType" SG_ 728 ADAS_Stub_PathIdx 10;
BA_ "GenSigSendType" SG_ 728 ADAS_Stub_StubPathIdx 10;
BA_ "GenSigSendType" SG_ 728 ADAS_Stub_Retr 10;
BA_ "GenSigSendType" SG_ 728 ADAS_Stub_Update 10;
BA_ "GenSigSendType" SG_ 728 ADAS_Stub_RelProbb 10;
BA_ "GenSigSendType" SG_ 728 ADAS_Stub_FuncRoadClass 10;
BA_ "GenSigSendType" SG_ 728 ADAS_Stub_PartOfCalcRoute 10;
BA_ "GenSigSendType" SG_ 728 ADAS_Stub_CmplxInsct 10;
BA_ "GenSigSendType" SG_ 728 ADAS_Stub_FormOfWay 10;
BA_ "GenSigSendType" SG_ 728 ADAS_Stub_TurnAngl 10;
BA_ "GenSigSendType" SG_ 728 ADAS_Stub_LastStub 10;
BA_ "GenSigSendType" SG_ 728 ADAS_Stub_RtOfWay 10;
BA_ "GenSigSendType" SG_ 728 ADAS_Stub_NumOfLaneOppDir 10;
BA_ "GenSigSendType" SG_ 728 ADAS_Stub_NumOfLaneDrvDir 10;
BA_ "GenSigSendType" SG_ 730 ADAS_Seg_MsgTyp 10;
BA_ "GenSigSendType" SG_ 730 ADAS_Seg_Offset 10;
BA_ "GenSigSendType" SG_ 730 ADAS_Seg_CycCnt 10;
BA_ "GenSigSendType" SG_ 730 ADAS_Seg_PathIdx 10;
BA_ "GenSigSendType" SG_ 730 ADAS_Seg_Tunnel 10;
BA_ "GenSigSendType" SG_ 730 ADAS_Seg_Brdg 10;
BA_ "GenSigSendType" SG_ 730 ADAS_Seg_BuildUpArea 10;
BA_ "GenSigSendType" SG_ 730 ADAS_Seg_Retr 10;
BA_ "GenSigSendType" SG_ 730 ADAS_Seg_Update 10;
BA_ "GenSigSendType" SG_ 730 ADAS_Seg_RelProbb 10;
BA_ "GenSigSendType" SG_ 730 ADAS_Seg_FuncRoadClass 10;
BA_ "GenSigSendType" SG_ 730 ADAS_Seg_PartOfCalcRoute 10;
BA_ "GenSigSendType" SG_ 730 ADAS_Seg_CmplxInsct 10;
BA_ "GenSigSendType" SG_ 730 ADAS_Seg_FormOfWay 10;
BA_ "GenSigSendType" SG_ 730 ADAS_Seg_EffSpdLmt 10;
BA_ "GenSigSendType" SG_ 730 ADAS_Seg_EffSpdLmtTyp 10;
BA_ "GenSigSendType" SG_ 730 ADAS_Seg_DivideRoad 10;
BA_ "GenSigSendType" SG_ 730 ADAS_Seg_NumOfLaneOppDir 10;
BA_ "GenSigSendType" SG_ 730 ADAS_Seg_NumOfLaneDrvDir 10;
BA_ "GenSigSendType" SG_ 731 ALCMSwtSts 10;
BA_ "GenSigSendType" SG_ 733 ADAS_ProfShort_MsgTyp 10;
BA_ "GenSigSendType" SG_ 733 ADAS_ProfShort_Offset 10;
BA_ "GenSigSendType" SG_ 733 ADAS_ProfShort_CycCnt 10;
BA_ "GenSigSendType" SG_ 733 ADAS_ProfShort_PathIdx 10;
BA_ "GenSigSendType" SG_ 733 ADAS_ProfShort_ProfTyp 10;
BA_ "GenSigSendType" SG_ 733 ADAS_ProfShort_CtrlPoint 10;
BA_ "GenSigSendType" SG_ 733 ADAS_ProfShort_Retr 10;
BA_ "GenSigSendType" SG_ 733 ADAS_ProfShort_Update 10;
BA_ "GenSigSendType" SG_ 733 ADAS_ProfShort_AccurClass 10;
BA_ "GenSigStartValue" SG_ 733 ADAS_ProfShort_AccurClass 3;
BA_ "GenSigSendType" SG_ 733 ADAS_ProfShort_Dist1 10;
BA_ "GenSigSendType" SG_ 733 ADAS_ProfShort_Value0 10;
BA_ "GenSigSendType" SG_ 733 ADAS_ProfShort_Value1 10;
BA_ "GenSigSendType" SG_ 734 ADAS_ProfLong_MsgTyp 10;
BA_ "GenSigSendType" SG_ 734 ADAS_ProfLong_Offset 10;
BA_ "GenSigSendType" SG_ 734 ADAS_ProfLong_CycCnt 10;
BA_ "GenSigSendType" SG_ 734 ADAS_ProfLong_PathIdx 10;
BA_ "GenSigSendType" SG_ 734 ADAS_ProfLong_ProfTyp 10;
BA_ "GenSigSendType" SG_ 734 ADAS_ProfLong_CtrlPoint 10;
BA_ "GenSigSendType" SG_ 734 ADAS_ProfLong_Retr 10;
BA_ "GenSigSendType" SG_ 734 ADAS_ProfLong_Update 10;
BA_ "GenSigSendType" SG_ 734 ADAS_ProfLong_Value 10;
BA_ "GenSigStartValue" SG_ 749 RPAS_NearBrrdstn 255;
BA_ "GenSigStartValue" SG_ 762 HCU_ACStsReq 2;
BA_ "GenSigStartValue" SG_ 790 OBC_ModSts 1;
BA_ "GenSigStartValue" SG_ 793 BackgroundLightLvl 128;
BA_ "GenSigStartValue" SG_ 796 VSGSwtSet 1;
BA_ "GenSigStartValue" SG_ 805 HUD_SwtSts 1;
BA_ "GenSigStartValue" SG_ 805 HUD_BrightnessLvl 4;
BA_ "GenSigStartValue" SG_ 805 HUD_HeightLvl 10;
BA_ "GenSigSendType" SG_ 817 HUT_EgyRecvrySet 10;
BA_ "GenSigSendType" SG_ 817 ACDualReq_VR 10;
BA_ "GenSigSendType" SG_ 817 ACAQSReq_VR 10;
BA_ "GenSigSendType" SG_ 817 ACRearDefrstReq_VR 10;
BA_ "GenSigSendType" SG_ 817 ACPassTempReq_VR 10;
BA_ "GenSigSendType" SG_ 817 ACAIUReq_VR 10;
BA_ "GenSigSendType" SG_ 817 IPVolSet 10;
BA_ "GenSigStartValue" SG_ 817 IPVolSet 15;
BA_ "GenSigSendType" SG_ 817 ALCMStatSwt 10;
BA_ "GenSigSendType" SG_ 817 ALCMDynSwt 10;
BA_ "GenSigSendType" SG_ 817 ALCMClrSet 10;
BA_ "GenSigSendType" SG_ 817 ALCMRhmSwt 10;
BA_ "GenSigStartValue" SG_ 817 ALCMRhmSwt 1;
BA_ "GenSigSendType" SG_ 817 PASSwtReq_VR 10;
BA_ "GenSigSendType" SG_ 825 CarWashMode_Req 10;
BA_ "GenSigSendType" SG_ 825 HUT_ChrgnMode 10;
BA_ "GenSigSendType" SG_ 825 HUT_BattKeepTemp 10;
BA_ "GenSigSendType" SG_ 825 HUT_IntelEngIdlChrgnSet 10;
BA_ "GenSigSendType" SG_ 825 HUT_BattSOCLim 10;
BA_ "GenSigSendType" SG_ 825 HUT_AvailInputCur 10;
BA_ "GenSigSendType" SG_ 825 HUT_IntelBattTempMagSet 10;
BA_ "GenSigSendType" SG_ 827 AVMSwtReq 10;
BA_ "GenSigSendType" SG_ 827 NaviMediaVolLvlReq 10;
BA_ "GenSigStartValue" SG_ 827 NaviMediaVolLvlReq 3;
BA_ "GenSigSendType" SG_ 827 AVMMediaVolLvlReq 10;
BA_ "GenSigStartValue" SG_ 827 AVMMediaVolLvlReq 3;
BA_ "GenSigSendType" SG_ 827 FPASChanSwtReq 10;
BA_ "GenSigSendType" SG_ 827 RPASChanSwtReq 10;
BA_ "GenSigSendType" SG_ 827 BackgroundLightLvlSet 10;
BA_ "GenSigStartValue" SG_ 827 BackgroundLightLvlSet 4;
BA_ "GenSigSendType" SG_ 827 ManCmpSet 10;
BA_ "GenSigStartValue" SG_ 827 ManCmpSet 5;
BA_ "GenSigSendType" SG_ 827 DispModSet 10;
BA_ "GenSigSendType" SG_ 827 OPDSwtSts 10;
BA_ "GenSigStartValue" SG_ 827 OPDSwtSts 1;
BA_ "GenSigSendType" SG_ 827 PLGReq_VR 10;
BA_ "GenSigSendType" SG_ 827 WPC_SwtReq 10;
BA_ "GenSigStartValue" SG_ 827 WPC_SwtReq 1;
BA_ "GenSigStartValue" SG_ 840 PowerSet 1;
BA_ "GenSigStartValue" SG_ 842 IP_AvgFuelCons 4095;
BA_ "GenSigStartValue" SG_ 842 IP_InstFuelCons 16383;
BA_ "GenSigStartValue" SG_ 849 SecRowLSBR 1;
BA_ "GenSigStartValue" SG_ 849 AirbFailLmpCmd 1;
BA_ "GenSigStartValue" SG_ 849 SecRowMidSBR 1;
BA_ "GenSigStartValue" SG_ 849 DrvSBR 1;
BA_ "GenSigStartValue" SG_ 849 SecRowRSBR 1;
BA_ "GenSigStartValue" SG_ 849 PassSBR 1;
BA_ "GenSigStartValue" SG_ 849 PassSBR_Visual 1;
BA_ "GenSigStartValue" SG_ 849 DrvSBR_Visual 1;
BA_ "GenSigStartValue" SG_ 849 SecRowLSBR_Visual 1;
BA_ "GenSigStartValue" SG_ 849 SecRowMidSBR_Visual 1;
BA_ "GenSigStartValue" SG_ 849 SecRowRSBR_Visual 1;
BA_ "GenSigSendType" SG_ 871 DomeLmpDlyTimSet 10;
BA_ "GenSigStartValue" SG_ 871 DomeLmpDlyTimSet 1;
BA_ "GenSigSendType" SG_ 871 FolwMeHomeDlyTimSet 10;
BA_ "GenSigStartValue" SG_ 871 FolwMeHomeDlyTimSet 1;
BA_ "GenSigSendType" SG_ 871 TranPMode_Req 10;
BA_ "GenSigSendType" SG_ 871 RearviewFoldModSet 10;
BA_ "GenSigStartValue" SG_ 871 RearviewFoldModSet 1;
BA_ "GenSigSendType" SG_ 871 BattSaveDelayTimeSet 10;
BA_ "GenSigStartValue" SG_ 871 BattSaveDelayTimeSet 1;
BA_ "GenSigSendType" SG_ 871 ACDualReq_TC 10;
BA_ "GenSigSendType" SG_ 871 ACAutoModReq_TC 10;
BA_ "GenSigSendType" SG_ 871 ACAirInletReq_TC 10;
BA_ "GenSigSendType" SG_ 871 ACAQSReq_TC 10;
BA_ "GenSigSendType" SG_ 871 ACCmprReq_TC 10;
BA_ "GenSigSendType" SG_ 871 ACFrntDefrstReq_TC 10;
BA_ "GenSigSendType" SG_ 871 ACFrntBlwrSpdDecReq_TC 10;
BA_ "GenSigSendType" SG_ 871 DrvDrowsnsDetnSet 10;
BA_ "GenSigStartValue" SG_ 871 DrvDrowsnsDetnSet 1;
BA_ "GenSigSendType" SG_ 871 ACFrntBlwrSpdIncReq_TC 10;
BA_ "GenSigSendType" SG_ 871 ACDrvAirDistribModReq_TC 10;
BA_ "GenSigSendType" SG_ 871 ACDrvTempDecReq_TC 10;
BA_ "GenSigSendType" SG_ 871 ChairMemPosnEna 10;
BA_ "GenSigStartValue" SG_ 871 ChairMemPosnEna 1;
BA_ "GenSigSendType" SG_ 871 ACDrvTempIncReq_TC 10;
BA_ "GenSigSendType" SG_ 871 ACFrntPassTempDecReq_TC 10;
BA_ "GenSigSendType" SG_ 871 ACFrntPassTempIncReq_TC 10;
BA_ "GenSigSendType" SG_ 871 ACAIUReq_TC 10;
BA_ "GenSigSendType" SG_ 871 ACOffReq_TC 10;
BA_ "GenSigSendType" SG_ 871 ACBlwrsteplsSpdReq_TC 10;
BA_ "GenSigSendType" SG_ 873 AMP_MediaCallSourceSet 10;
BA_ "GenSigSendType" SG_ 873 AMP_NaviSourceSet 10;
BA_ "GenSigSendType" SG_ 873 AMP_BeepSourceSet 10;
BA_ "GenSigSendType" SG_ 873 AMP_LRAudioBalanceSet 10;
BA_ "GenSigStartValue" SG_ 873 AMP_LRAudioBalanceSet 10;
BA_ "GenSigSendType" SG_ 873 AMP_AudioVolVSCModReq 10;
BA_ "GenSigStartValue" SG_ 873 AMP_AudioVolVSCModReq 2;
BA_ "GenSigSendType" SG_ 873 AMP_FRAudioFaderSet 10;
BA_ "GenSigStartValue" SG_ 873 AMP_FRAudioFaderSet 10;
BA_ "GenSigSendType" SG_ 873 AMP_LRDrvSideSet 10;
BA_ "GenSigSendType" SG_ 873 AMP_LowFrqAudioSet 10;
BA_ "GenSigStartValue" SG_ 873 AMP_LowFrqAudioSet 10;
BA_ "GenSigSendType" SG_ 873 AMP_MuteSet 10;
BA_ "GenSigStartValue" SG_ 873 AMP_MuteSet 1;
BA_ "GenSigSendType" SG_ 873 AMP_MidFrqAudioSet 10;
BA_ "GenSigStartValue" SG_ 873 AMP_MidFrqAudioSet 10;
BA_ "GenSigSendType" SG_ 873 AMP_HighFrqAudioSet 10;
BA_ "GenSigStartValue" SG_ 873 AMP_HighFrqAudioSet 10;
BA_ "GenSigSendType" SG_ 873 T_box_ECallSet 10;
BA_ "GenSigSendType" SG_ 873 QLISurroundSet 10;
BA_ "GenSigStartValue" SG_ 873 QLISurroundSet 1;
BA_ "GenSigSendType" SG_ 873 ANCSwtSet 10;
BA_ "GenSigStartValue" SG_ 873 ANCSwtSet 1;
BA_ "GenSigSendType" SG_ 873 RearWinHeatCmd_TC 10;
BA_ "GenSigSendType" SG_ 873 FrntWinHeatSwt 10;
BA_ "GenSigSendType" SG_ 875 AMP_HFMVolSet 10;
BA_ "GenSigStartValue" SG_ 875 AMP_HFMVolSet 10;
BA_ "GenSigSendType" SG_ 875 AMP_TTSVolSet_VR 10;
BA_ "GenSigStartValue" SG_ 875 AMP_TTSVolSet_VR 10;
BA_ "GenSigSendType" SG_ 875 AMP_NaviVolSet 10;
BA_ "GenSigStartValue" SG_ 875 AMP_NaviVolSet 10;
BA_ "GenSigSendType" SG_ 875 AMP_MainVolSet 10;
BA_ "GenSigStartValue" SG_ 875 AMP_MainVolSet 10;
BA_ "GenSigSendType" SG_ 875 AMP_GetSWInfoReq 10;
BA_ "GenSigSendType" SG_ 875 AMP_GetHWInfoReq 10;
BA_ "GenSigSendType" SG_ 875 AMP_GetTempInfoReq 10;
BA_ "GenSigSendType" SG_ 875 AMP_GetIntVoltInfoReq 10;
BA_ "GenSigSendType" SG_ 875 AMP_GetDTCInfoReq 10;
BA_ "GenSigSendType" SG_ 875 IESS_MdlSwtReq 10;
BA_ "GenSigSendType" SG_ 875 IESS_MdlInfoReq 10;
BA_ "GenSigSendType" SG_ 875 AMP_BestListegPosnReq 10;
BA_ "GenSigSendType" SG_ 875 AMP_Clari_FiReq 10;
BA_ "GenSigStartValue" SG_ 875 AMP_Clari_FiReq 1;
BA_ "GenSigSendType" SG_ 877 DrvSeatHeatgLvlSet 10;
BA_ "GenSigSendType" SG_ 877 PassSeatHeatgLvlSet 10;
BA_ "GenSigSendType" SG_ 877 DrvSeatVentnLvlSet 10;
BA_ "GenSigSendType" SG_ 877 PassSeatVentnLvlSet 10;
BA_ "GenSigSendType" SG_ 877 ACAutoModReq_VR 10;
BA_ "GenSigSendType" SG_ 877 ACCmprReq_VR 10;
BA_ "GenSigSendType" SG_ 877 ACPowerReq_VR 10;
BA_ "GenSigSendType" SG_ 877 ACBlwrSpdReq_VR 10;
BA_ "GenSigSendType" SG_ 877 ACDrvTempReq_VR 10;
BA_ "GenSigSendType" SG_ 877 ACFrntDefrostReq_VR 10;
BA_ "GenSigSendType" SG_ 877 ACDrvAirDistribModReq_VR 10;
BA_ "GenSigSendType" SG_ 877 ACAirInletReq_VR 10;
BA_ "GenSigSendType" SG_ 877 ACModReq_HUT 10;
BA_ "GenSigStartValue" SG_ 877 ACModReq_HUT 1;
BA_ "GenSigSendType" SG_ 877 ElecSideSteppingSysSet 10;
BA_ "GenSigStartValue" SG_ 877 ElecSideSteppingSysSet 1;
BA_ "GenSigSendType" SG_ 877 RoofModSet 10;
BA_ "GenSigSendType" SG_ 877 AllTerrainDislSet 10;
BA_ "GenSigStartValue" SG_ 880 Time_Hour 31;
BA_ "GenSigStartValue" SG_ 880 Time_Minutes 63;
BA_ "GenSigStartValue" SG_ 880 Time_Second 63;
BA_ "GenSigStartValue" SG_ 880 Time_Year_Left 15;
BA_ "GenSigStartValue" SG_ 880 Time_Year_Right 15;
BA_ "GenSigStartValue" SG_ 881 EngClntTempVldty 2;
BA_ "GenSigStartValue" SG_ 881 SSSSetSts 1;
BA_ "GenSigStartValue" SG_ 901 ACFrntBlwrSpd 15;
BA_ "GenSigStartValue" SG_ 901 ACDrvTemp_ATC 33;
BA_ "GenSigStartValue" SG_ 901 ACAmbTemp 254;
BA_ "GenSigStartValue" SG_ 901 ACAirInletSts 3;
BA_ "GenSigStartValue" SG_ 901 ACFrntPasstTemp_ATC 33;
BA_ "GenSigStartValue" SG_ 909 HCU_ChargSts_RM 3;
BA_ "GenSigSendType" SG_ 929 IESS_SwitchModel 10;
BA_ "GenSigStartValue" SG_ 948 TMCU_ActHvDcCurr_RM 1000;
BA_ "GenSigStartValue" SG_ 948 TMCU_ActTemp_RM 65;
BA_ "GenSigStartValue" SG_ 948 TMCU_OperMode_RM 4;
BA_ "GenSigStartValue" SG_ 969 TMCU_InvActTemp_RM 65;
BA_ "GenSigStartValue" SG_ 969 TMCU_ActSpd_RM 20000;
BA_ "GenSigStartValue" SG_ 969 TMCU_ActTrq_RM 20000;
BA_ "GenSigStartValue" SG_ 976 BMS_BattTempMax 65;
BA_ "GenSigStartValue" SG_ 976 BMS_BattTempMin 65;
BA_ "GenSigStartValue" SG_ 977 BMS_BattModuleTe_11 65;
BA_ "GenSigStartValue" SG_ 977 BMS_BattModuleTe_12 65;
BA_ "GenSigStartValue" SG_ 977 BMS_BattModuleTe_21 65;
BA_ "GenSigStartValue" SG_ 977 BMS_BattModuleTe_22 65;
BA_ "GenSigStartValue" SG_ 977 BMS_BattModuleTe_31 65;
BA_ "GenSigStartValue" SG_ 977 BMS_BattModuleTe_32 65;
BA_ "GenSigStartValue" SG_ 977 BMS_BattModuleTe_41 65;
BA_ "GenSigStartValue" SG_ 977 BMS_BattModuleTe_42 65;
BA_ "GenSigStartValue" SG_ 977 BMS_BattModuleTe_51 65;
BA_ "GenSigStartValue" SG_ 977 BMS_BattModuleTe_52 65;
BA_ "GenSigStartValue" SG_ 977 BMS_BattModuleTe_61 65;
BA_ "GenSigStartValue" SG_ 977 BMS_BattModuleTe_62 65;
BA_ "GenSigStartValue" SG_ 977 BMS_BattModuleTe_71 65;
BA_ "GenSigStartValue" SG_ 977 BMS_BattModuleTe_72 65;
BA_ "GenSigStartValue" SG_ 977 BMS_BattModuleTe_81 65;
BA_ "GenSigStartValue" SG_ 977 BMS_BattModuleTe_82 65;
BA_ "GenSigStartValue" SG_ 981 BMS_BattModuleTe_91 65;
BA_ "GenSigStartValue" SG_ 981 BMS_BattModuleTe_92 65;
BA_ "GenSigStartValue" SG_ 981 BMS_NumberCellVoltMin_RM 1;
BA_ "GenSigSendType" SG_ 993 AMP_SWVersion 10;
BA_ "GenSigSendType" SG_ 993 AMP_HWVersion 10;
BA_ "GenSigSendType" SG_ 993 AMP_Chan1DTCInfo 10;
BA_ "GenSigSendType" SG_ 993 AMP_Chan2DTCInfo 10;
BA_ "GenSigSendType" SG_ 993 AMP_Chan3DTCInfo 10;
BA_ "GenSigSendType" SG_ 993 AMP_Chan4DTCInfo 10;
BA_ "GenSigSendType" SG_ 993 AMP_Chan5DTCInfo 10;
BA_ "GenSigSendType" SG_ 993 AMP_Chan6DTCInfo 10;
BA_ "GenSigSendType" SG_ 993 AMP_Chan7DTCInfo 10;
BA_ "GenSigSendType" SG_ 993 AMP_Chan8DTCInfo 10;
BA_ "GenSigSendType" SG_ 993 AMP_TempValue 10;
BA_ "GenSigSendType" SG_ 993 AMP_TempSts 10;
BA_ "GenSigSendType" SG_ 993 AMP_VolValue 10;
BA_ "GenSigSendType" SG_ 993 BestListegPosnResp 10;
BA_ "GenSigSendType" SG_ 993 Clari_FiResp 10;
BA_ "GenSigStartValue" SG_ 993 Clari_FiResp 1;
BA_ "GenSigSendType" SG_ 995 MediaCallSourceState 10;
BA_ "GenSigSendType" SG_ 995 BeepSourceSts 10;
BA_ "GenSigSendType" SG_ 995 BalanceSetState 10;
BA_ "GenSigStartValue" SG_ 995 BalanceSetState 10;
BA_ "GenSigSendType" SG_ 995 VSCModeState 10;
BA_ "GenSigStartValue" SG_ 995 VSCModeState 2;
BA_ "GenSigSendType" SG_ 995 FadeSetState 10;
BA_ "GenSigStartValue" SG_ 995 FadeSetState 10;
BA_ "GenSigSendType" SG_ 995 DriveSideSts 10;
BA_ "GenSigSendType" SG_ 995 BassSetState 10;
BA_ "GenSigStartValue" SG_ 995 BassSetState 10;
BA_ "GenSigSendType" SG_ 995 MuteState 10;
BA_ "GenSigStartValue" SG_ 995 MuteState 1;
BA_ "GenSigSendType" SG_ 995 NaviSourceState 10;
BA_ "GenSigSendType" SG_ 995 MidrangeSetState 10;
BA_ "GenSigStartValue" SG_ 995 MidrangeSetState 10;
BA_ "GenSigSendType" SG_ 995 T_box_ECallSts 10;
BA_ "GenSigSendType" SG_ 995 GetHUTInfoSts 10;
BA_ "GenSigStartValue" SG_ 995 GetHUTInfoSts 1;
BA_ "GenSigSendType" SG_ 995 TrebleSetState 10;
BA_ "GenSigStartValue" SG_ 995 TrebleSetState 10;
BA_ "GenSigSendType" SG_ 995 QLISurroundSetSt 10;
BA_ "GenSigStartValue" SG_ 995 QLISurroundSetSt 1;
BA_ "GenSigSendType" SG_ 995 AVMStResp 10;
BA_ "GenSigSendType" SG_ 995 NaviMediaVolLvlResp 10;
BA_ "GenSigStartValue" SG_ 995 NaviMediaVolLvlResp 3;
BA_ "GenSigSendType" SG_ 995 AVMMediaVolLvlResp 10;
BA_ "GenSigStartValue" SG_ 995 AVMMediaVolLvlResp 3;
BA_ "GenSigSendType" SG_ 995 FPASChStResp 10;
BA_ "GenSigSendType" SG_ 995 RPASChStResp 10;
BA_ "GenSigSendType" SG_ 995 FreshnessValue_AMP2 10;
BA_ "GenSigSendType" SG_ 995 MAC_Check_AMP2 10;
BA_ "GenSigSendType" SG_ 997 HFMVolSetSts 10;
BA_ "GenSigStartValue" SG_ 997 HFMVolSetSts 10;
BA_ "GenSigSendType" SG_ 997 VR_TTSVolSetSts 10;
BA_ "GenSigStartValue" SG_ 997 VR_TTSVolSetSts 10;
BA_ "GenSigSendType" SG_ 997 NaviVolumeSetState 10;
BA_ "GenSigStartValue" SG_ 997 NaviVolumeSetState 10;
BA_ "GenSigSendType" SG_ 997 MainVolumeSetState 10;
BA_ "GenSigStartValue" SG_ 997 MainVolumeSetState 10;
BA_ "GenSigSendType" SG_ 997 AMPPowerSts 10;
BA_ "GenSigStartValue" SG_ 997 AMPPowerSts 1;
BA_ "GenSigSendType" SG_ 997 IPVolSetSts 10;
BA_ "GenSigStartValue" SG_ 997 IPVolSetSts 15;
BA_ "GenSigStartValue" SG_ 1008 BMS_NumCellMaxTemp_RM 1;
BA_ "GenSigStartValue" SG_ 1008 BMS_NumCellMinTemp_RM 1;
BA_ "GenSigStartValue" SG_ 1008 BMS_NumberCellVoltMax_RM 1;
BA_ "GenSigStartValue" SG_ 1008 BMS_IsolationRValue_RM 10000;
BA_ "GenSigStartValue" SG_ 1008 BMS_SysNumberCellVoltMax_RM 1;
BA_ "GenSigStartValue" SG_ 1008 BMS_SysNumberCellVoltMin_RM 1;
BA_ "GenSigStartValue" SG_ 1008 BMS_SysNumCellMaxTemp_RM 1;
BA_ "GenSigStartValue" SG_ 1008 BMS_SysNumCellMinTemp_RM 1;
BA_ "GenSigStartValue" SG_ 1008 BMS_BattSysNum_RM 1;
BA_ "GenSigStartValue" SG_ 1009 BMS_moduleNumber 1;
BA_ "GenSigStartValue" SG_ 1009 BMS_NumModuleTempSnsr 1;
BA_ "GenSigStartValue" SG_ 1009 BMS_NumCell 1;
BA_ "GenSigStartValue" SG_ 1011 BMS_ModuleMinTemp 65;
BA_ "GenSigStartValue" SG_ 1011 BMS_ModuleNumCellMinTemp 1;
BA_ "GenSigStartValue" SG_ 1011 BMS_ModuleNumCellMaxTemp 1;
BA_ "GenSigStartValue" SG_ 1011 BMS_ModuleMaxTemp 65;
BA_ "GenSigStartValue" SG_ 1011 BMS_NumCellMinTemp 1;
BA_ "GenSigStartValue" SG_ 1011 BMS_NumCellMaxTemp 1;
BA_ "GenSigStartValue" SG_ 1011 BMS_ModuleNumberCellMinVolt 1;
BA_ "GenSigStartValue" SG_ 1011 BMS_ModuleNumberCellMaxVolt 1;
BA_ "GenSigStartValue" SG_ 1045 ADAS_Meta_DrvSide 1;
BA_ "GenSigSendType" SG_ 1290 Destination_T_Box_NM 10;
BA_ "GenSigSendType" SG_ 1290 OpCode_T_Box_NM 10;
BA_ "GenSigSendType" SG_ 1289 Destination_HUT_NM 10;
BA_ "GenSigSendType" SG_ 1289 OpCode_HUT_NM 10;
BA_ "GenSigSendType" SG_ 1302 Destination_DMS_NM 10;
BA_ "GenSigSendType" SG_ 1302 OpCode_DMS_NM 10;
BA_ "GenSigSendType" SG_ 1303 Destination_DVR_NM 10;
BA_ "GenSigSendType" SG_ 1303 OpCode_DVR_NM 10;
BA_ "GenSigSendType" SG_ 1281 Destination_GW_NM 10;
BA_ "GenSigSendType" SG_ 1281 OpCode_GW_NM 10;
BA_ "GenSigSendType" SG_ 1888 DiagFuncReq 10;
BA_ "GenSigSendType" SG_ 1889 GW_Phy_Req 10;
BA_ "GenSigSendType" SG_ 1918 T_Box_Phy_Req 10;
BA_ "GenSigSendType" SG_ 1907 HUT_Phy_Req 10;
BA_ "GenSigSendType" SG_ 1566 DMS_Phy_Req 10;
BA_ "GenSigSendType" SG_ 1560 DVR_Phy_Req 10;
BA_ "GenSigSendType" SG_ 1953 GW_Phy_Resp 10;
BA_ "GenSigSendType" SG_ 1982 T_Box_Phy_Resp 10;
BA_ "GenSigSendType" SG_ 1971 HUT_Phy_Resp 10;
BA_ "GenSigSendType" SG_ 1567 DMS_Phy_Resp 10;
BA_ "GenSigSendType" SG_ 1561 DVR_Phy_Resp 10;
VAL_ 696 ACC_DataRecReq 0 " No Demand " 1 " TakeOver Demand " 2 " SafeStop Demand " 3 " AEB Demand " 4 " Reserved " ;
VAL_ 698 WPC_ChrgSts 0 " Standby " 1 " Charging " 2 " Charging Completed " 3 " WPC Fault " ;
VAL_ 698 WPC_SwtSts 0 " Initial Value " 1 " ON " 2 " OFF " 3 " Reserved " ;
VAL_ 698 WPC_FaultSts 0 " No Fault " 1 " Foreign Object Detection_FOD " 2 " Over Voltage Protection_OVP " 3 " Low Voltage Protection_LVP " 4 " Over Temperature Protection_OTP " 5 " System Fault " 6 " Reserved " ;
VAL_ 698 WPC_PhoneReminder 0 " No need to remind " 1 " Remind forgotten phone " ;
VAL_ 699 U_BATT 0 " valid value " 15361 " Reserved " 16383 " Invalid " ;
VAL_ 699 I_RANGE 0 " current Range [-1, 1A] " 1 " current Range [-200, 200A] " 2 " current Range [-1500, 1500A] " 3 " Invalid " ;
VAL_ 699 I_BATT 31744 " valid value[-1, 1A] " 7168 " valid value [-200, 200A] " 8768 " valid value  [-1500, 1500A] " 65535 " Invalid " ;
VAL_ 699 SOC 0 " valid value " 101 " Reserved " 255 " Invalid " ;
VAL_ 699 SOH_SUL 0 " valid value " 101 " Reserved " 255 " Invalid " ;
VAL_ 699 SOC_STATE 0 " deviation > 15% " 1 " deviation <15% " 2 " deviation < 10% " 3 " Invalid " ;
VAL_ 699 SOH_SUL_STATE 0 " not learned " 1 " learned " 2 " Reserved " 3 " Invalid " ;
VAL_ 705 DSM_BuzSoundCmd 0 " no sound  " 1 " Ring once " 2 " Ring twice  " 3 " reserved " ;
VAL_ 707 SSSSet_HUT 0 " OFF " 1 " ON " ;
VAL_ 707 IFC_SnvtySet 0 " Normal " 1 " High sensitivity " 2 " Low sensitivity " 3 " Reserved " ;
VAL_ 707 DOWSwtReq 0 " OFF " 1 " ON " ;
VAL_ 707 AEB_PedSwtReq 0 " OFF " 1 " ON " ;
VAL_ 707 ALCMLightLvlSet 0 " Reserved " 1 " 10 " 2 " 20 " 3 " 30 " 4 " 40 " 5 " 50 " 6 " 60 " 7 " 70 " 8 " 80 " 9 " 90 " 10 " 100 " 11 " Reserved " ;
VAL_ 707 FlashLmpSwtReq 0 " OFF " 1 " ON " ;
VAL_ 707 LCASwtReq 0 " OFF " 1 " ON " ;
VAL_ 707 RCTASwtReq 0 " OFF " 1 " ON " ;
VAL_ 707 RCTABrkSwtReq 0 " OFF " 1 " ON " ;
VAL_ 707 RCWSwtReq 0 " OFF " 1 " ON " ;
VAL_ 707 FCW_SnvtySet 0 " Normal " 1 " High sensitivity " 2 " Low sensitivity " 3 " Reserved " ;
VAL_ 707 AEB_VehSwtReq 0 " OFF " 1 " ON " ;
VAL_ 707 LKASwtReq 0 " OFF " 1 " ON " ;
VAL_ 707 LCKSwtReq 0 " OFF " 1 " ON " ;
VAL_ 707 ELKSwtReq 0 " OFF " 1 " ON " ;
VAL_ 707 ESS_PedSwtReq 0 " OFF " 1 " ON " ;
VAL_ 707 ESS_VehSwtReq 0 " OFF " 1 " ON " ;
VAL_ 707 LDWSwtReq 0 " OFF " 1 " ON " ;
VAL_ 707 TSRSwtReq 0 " OFF " 1 " ON " ;
VAL_ 707 TSRWarnSwtReq 0 " OFF " 1 " ON " ;
VAL_ 707 ICA_HandsOffSwtReq 0 " OFF " 1 " ON " ;
VAL_ 707 ISLSwtReq 0 " OFF " 1 " ON " ;
VAL_ 707 TSR_SnvtySet 0 " valid " 31 " Invalid " ;
VAL_ 707 BrkPedalFeelReq 0 " Comfort " 1 " Sport  " 2 " Reserved " ;
VAL_ 707 HFASwtSts 0 " OFF " 1 " ON " ;
VAL_ 707 EPSSteerModSwtReq 0 " Comfort Mode " 1 " Sport?mode? " 2 " Handiness Mode " 3 " NO Hut Control " ;
VAL_ 707 DSTSwtReq 0 " OFF " 1 " ON " ;
VAL_ 707 HUT_ESPFuncOffSwtSts 0 " Not Pressed " 1 " Pressed " ;
VAL_ 707 DrivingModReq_HUT 0 " Standard/Normal Mode " 1 " Snow_Nex " 2 " Off Road " 3 " Economic " 4 " Sport " 5 " Reserved " 9 " Auto " 10 " 4L " 11 " Mud " 12 " Reserved " 13 " Sand " 14 " Reserved " 15 " Invalid Value " ;
VAL_ 707 LSSSwtReq 0 " OFF " 1 " ON " ;
VAL_ 707 LSSWarnFormSwtReq 0 " Voice " 1 " Haptic " 2 " Voice+Haptic " 3 " Reserved " ;
VAL_ 707 IntelligentEvaSwtReq 0 " OFF " 1 " ON " ;
VAL_ 707 HUT_BattSOCLimSaveMod 0 " 30% " 1 " 35% " 2 " 40% " 3 " 45% " 4 " 50% " 5 " 55% " 6 " 60% " 7 " 65% " 8 " 70% " 9 " 75% " 10 " 80% " 11 " 85% " 12 " 90% " 13 " 95% " 14 " 100% " 15 " Reserved " 31 " Invalid " ;
VAL_ 707 HUTRadioFrq 0 " Radio frequency value " 4095 " Invalid value " ;
VAL_ 707 MediaPlaySrc 0 " unknown  " 1 " USB Audio  " 2 " USB Video  " 3 " BT Audio  " 4 " iPod  " 5 " AM  " 6 " FM  " 7 " Applink  " 8 " QQ Music  " 9 " Kaola FM  " 10 " Online News  " 11 " TOD  " 12 " Reversed " ;
VAL_ 707 HUT_DrvModReq 0 " Auto/Normal Mode started " 1 " EV Mode started " 2 " Save Mode started " 3 " SPORT Mode started " 4 " AWD Normal Mode started " 5 " Snow Mode started " 6 " Muddy Mode started " 7 " Sand Mode started " 8 " ECO Mode started " 9 " SPORT Plus Mode started " 10 " Reserved " ;
VAL_ 707 USB_AudioSts 0 " Invalid  " 1 " Play  " 2 " Pause  " 3 " Reserved " ;
VAL_ 707 USB_VideoSts 0 " Invalid  " 1 " Play  " 2 " Pause  " 3 " Reserved " ;
VAL_ 707 BT_AudioSts 0 " Invalid  " 1 " Play  " 2 " Pause  " 3 " Reserved " ;
VAL_ 707 IPod_Sts 0 " Invalid  " 1 " Play  " 2 " Pause  " 3 " Reserved " ;
VAL_ 707 AM_Sts 0 " Invalid  " 1 " Play  " 2 " Pause  " 3 " Reserved " ;
VAL_ 707 FM_Sts 0 " Invalid  " 1 " Play  " 2 " Pause  " 3 " Reserved " ;
VAL_ 707 APPLink_Sts 0 " Invalid  " 1 " Play  " 2 " Pause  " 3 " Reserved " ;
VAL_ 707 QQMusic_Sts 0 " Invalid  " 1 " Play  " 2 " Pause  " 3 " Reserved " ;
VAL_ 707 KaolaFM_Sts 0 " Invalid  " 1 " Play  " 2 " Pause  " 3 " Reserved " ;
VAL_ 707 OnlineNews_Sts 0 " Invalid  " 1 " Play  " 2 " Pause  " 3 " Reserved " ;
VAL_ 707 ChairMemPosnSet 0 " No Command " 1 " Binding Account " 2 " Bring Up The Account " 3 " Unbinding Account " ;
VAL_ 707 CCOSwtReq_HUT 0 " No request " 1 " Request " ;
VAL_ 707 ChairMemPosnSetResult 0 " Factory Default " 1 " User ID1 " 2 " User ID2 " 3 " User ID3 " 4 " User ID4 " 5 " User ID5 " 6 " User ID6 " 7 " User ID7 " 8 " User ID8 " 9 " User ID9 " 10 " User ID10 " 11 " Reserved " ;
VAL_ 707 TABSwtReq_HUT 0 " Not activate " 1 " Activate " ;
VAL_ 707 NavVehToTrafEyeDist 0 " Valid value " ;
VAL_ 707 NavRoadType 0 " Unknown " 1 " Expressway " 2 " City expressway " 3 " National rode " 4 " Provincial rode " 5 " County rode " 6 " City or Village rode " 7 " ramp " 8 " Tunnel " 9 " Side rode " 10 " Channel " 11 " Reserved " ;
VAL_ 707 NavSpdLimType 0 " Unknown " 1 " Traffic sign " 2 " Electronic eye " 3 " Rode Default " ;
VAL_ 707 NavSpdLimValue 0 " No Display " 1 " SPL 5 " 2 " SPL 10 " 3 " SPL 15 " 4 " SPL 20 " 5 " SPL 25 " 6 " SPL 30 " 7 " SPL 35 " 8 " SPL 40 " 9 " SPL 45 " 10 " SPL 50 " 11 " SPL 55 " 12 " SPL 60 " 13 " SPL 65 " 14 " SPL 70 " 15 " SPL 75 " 16 " SPL 80 " 17 " SPL 85 " 18 " SPL 90 " 19 " SPL 95 " 20 " SPL 100 " 21 " SPL 105 " 22 " SPL 110 " 23 " SPL 115 " 24 " SPL 120 " 25 " SPL 125 " 26 " SPL 130 " 27 " SPL 135 " 28 " SPL 140 " 29 " SPL 145 " 30 " SPL 150 " 31 " Reserved " 63 " Invalid " ;
VAL_ 707 NavSpdLimUnit_HUT 0 " Unknown " 1 " KMH " 2 " MPH " 3 " Reserved " ;
VAL_ 707 NavCtryType 0 " Reserved " 156 " China " 157 " Reserved " ;
VAL_ 707 NavSpdLimSignSts 0 " Unknow " 1 " Exist SPL sign " 2 " Exist Traffic sign " 3 " Exist SPL and Traffic sign " 4 " None " 5 " Plural " 6 " Reserved " ;
VAL_ 707 NavTSRTrafSign 0 " None " 1 " Snow  " 2 " Fog  " 3 " ThunderStorm  " 4 " Rain  " 5 " FWay  " 6 " EFWay  " 7 " Straight  " 8 " FrontageLeft  " 9 " TurnLeftRight  " 10 " FrontageRight  " 11 " Right  " 12 " TurnRight  " 13 " Left  " 14 " TurnLeft  " 15 " RelieveNoOvertake  " 16 " NoOvertake  " 17 " StopGiveWay  " 18 " GiveWay  " 19 " NoPass  " 20 " NoEntry  " 21 " NoCar  " 22 " NoTruck  " 23 " NoBus  " 24 " NoTurnaround  " 25 " NoStraightLeftTurn  " 26 " NoStraightRightTurn  " 27 " NoLeftRightTurn  " 28 " NoLeftTurn  " 29 " NoRightTurn  " 30 " NoStraight  " 31 " WarnKids  " 32 " WarnPed  " 33 " WarnBike  " 34 " WarnWorks  " 35 " WarnWildanimal  " 36 " WarnCattle  " 37 " AccidentProneSection  " 38 " Town  " 39 " Slow  " 40 " SharpTurnR  " 41 " SharpTurnL  " 42 " ReverseCurveL  " 43 " ReverseCurveR  " 44 " ContinuousBend  " 45 " Crossroads  " 46 " ConfluenceR  " 47 " ConfluenceL  " 48 " Reserved  " 255 " Invalid  " ;
VAL_ 707 FCTASwtReq 0 " OFF " 1 " ON " ;
VAL_ 707 FCTABrkSwtReq 0 " OFF " 1 " ON " ;
VAL_ 707 AEB_JASwtReq 0 " OFF " 1 " ON " ;
VAL_ 707 AESSwtReq 0 " OFF " 1 " ON " ;
VAL_ 707 ADAS_Posn_MsgTye 0 " System Specific " 1 " Position " 2 " Segment " 3 " Stub " 4 " Profile Short " 5 " Profile Long " 6 " Meta-data " 7 " Reserved " ;
VAL_ 707 ADAS_Posn_Offset 0 " Valid value " 8191 " Invalid data " ;
VAL_ 707 ADAS_Posn_CycCnt 0 " Valid value " ;
VAL_ 707 ADAS_Posn_Pathldx 0 " Valid value " ;
VAL_ 707 ADAS_Posn_Idx 0 " Valid value " ;
VAL_ 707 ADAS_Posn_PosProbb 0 " Unknown " 1 " Valid data " 31 " Invalid " ;
VAL_ 707 ADAS_Posn_Age 0 " 0~2545ms " 510 " >2545ms " 511 " Invalid data " ;
VAL_ 707 ADAS_Posn_PosConfdc 0 " Valid value " 7 " Invalid value " ;
VAL_ 707 ADAS_Posn_CurLane 0 " Unknown " 1 " Emergency lane " 2 " Single-lane road " 3 " Left-most lane " 4 " Right-most lane " 5 " One of middle lanes on road with three or more lanes  " 6 " Reserved " 7 " Invalid data " ;
VAL_ 707 ADAS_Posn_Spd 0 " ≤ -12.8 m/s " 1 " (-12.6)~(-0.2)m/s " 64 " Standing still " 65 " (+0.2)~(+89.0)m/s " 510 " ≥ +89.2 m/s " 511 " Invalid data " ;
VAL_ 707 ADAS_Posn_Rehead 0 " In path direction " 1 " 1.417 degrees right " 2 " Right from path direction " 126 " 178.583 degrees right " 127 " Opposite direction " 128 " 178.583 degrees left (181.417 degrees right) " 129 " Left from path direction " 253 " 1.417 degrees left (358.583 degrees right) " 254 " Unknown " 255 " Invalid " ;
VAL_ 708 BMS_BattSOC 0 " Valid values " 1001 " Reserved " 1023 " Invalid values " ;
VAL_ 714 DrvMirrFold_UnfoldSts 0 " Unfold " 1 " Fold " ;
VAL_ 714 PowerCutSwt 0 " Released " 1 " Pressed " ;
VAL_ 714 DrvWinPosnSts 0 " Middle " 1 " Up " 2 " Down " 3 " Other " 4 " reserved " ;
VAL_ 714 DrvWinAntiPinchSts 0 " Not active " 1 " Active " ;
VAL_ 714 DrvWinLrnSts 0 " Unlearn " 1 " Learn " ;
VAL_ 714 DrvWinHotProtSts 0 " NO " 1 " Hot prtect " ;
VAL_ 714 DrvSideRearAntiPinchSts 0 " Not active " 1 " Active " ;
VAL_ 714 DrvSideRearWinPosnSts 0 " Middle " 1 " Up " 2 " Down " 3 " Other " 4 " reserved " ;
VAL_ 714 DrvSideRearWinLrnSts 0 " Unlearn " 1 " Learn " ;
VAL_ 714 DrvSideRearWinHotProtSts 0 " NO " 1 " Hot prtect " ;
VAL_ 717 PassMirrFold_UnfoldSts 0 " Unfold " 1 " Fold " ;
VAL_ 717 PassWinAntiPinchSts 0 " Not active " 1 " Active " ;
VAL_ 717 PassWinPosnSts 0 " Middle " 1 " Up " 2 " Down " 3 " Other " 4 " reserved " ;
VAL_ 717 PassWinLrnSts 0 " Unlearn " 1 " Learn " ;
VAL_ 717 PassWinHotProtSts 0 " NO " 1 " Hot prtect " ;
VAL_ 717 PassSideRearWinAntiPinchSts 0 " Not active " 1 " Active " ;
VAL_ 717 PassSideRearWinPosnSts 0 " Middle " 1 " Up " 2 " Down " 3 " Other " 4 " reserved " ;
VAL_ 717 PassSideRearWinLrnSts 0 " Unlearn " 1 " Learn " ;
VAL_ 717 PassSideRearWinHotProtSts 0 " NO " 1 " Hot prtect " ;
VAL_ 719 TSRResp 0 " OFF " 1 " ON " ;
VAL_ 719 TSRSpdLimUnit 0 " Unknown " 1 " KMH " 2 " MPH " 3 " Reserved " ;
VAL_ 719 TSRSpdLim 0 " No Display " 1 " SPL 5 " 2 " SPL 10 " 3 " SPL 15 " 4 " SPL 20 " 5 " SPL 25 " 6 " SPL 30 " 7 " SPL 35 " 8 " SPL 40 " 9 " SPL 45 " 10 " SPL 50 " 11 " SPL 55 " 12 " SPL 60 " 13 " SPL 65 " 14 " SPL 70 " 15 " SPL 75 " 16 " SPL 80 " 17 " SPL 85 " 18 " SPL 90 " 19 " SPL 95 " 20 " SPL 100 " 21 " SPL 105 " 22 " SPL 110 " 23 " SPL 115 " 24 " SPL 120 " 25 " SPL 125 " 26 " SPL 130 " 27 " SPL 135 " 28 " SPL 140 " 29 " SPL 145 " 30 " SPL 150 " 31 " Reserved " 63 " Invalid " ;
VAL_ 719 TSRSpdLimCfdc 0 " Null " 1 " Implicit " 2 " Explicit " 3 " Reserved " ;
VAL_ 719 TSRSts 0 " Off " 1 " Fusion mode " 2 " Vision mode " 3 " Navigation only mode " 4 " Failed " 5 " Reserved " ;
VAL_ 719 TSRSpdLimSts 0 " No Speed Limit " 1 " Speed Limit                       " 2 " Speed Limit Cancel   " 3 " Reserved " ;
VAL_ 719 TSRTrfcSignValCfdc 0 " Null " 1 " Implicit " 2 " Explicit " 3 " Reserved " ;
VAL_ 719 TSRTrfcSignVal 0 " None  " 1 " Snow  " 2 " Fog  " 3 " ThunderStorm  " 4 " Rain  " 5 " FWay  " 6 " EFWay  " 7 " Straight  " 8 " FrontageLeft  " 9 " TurnLeftRight  " 10 " FrontageRight  " 11 " Right  " 12 " TurnRight  " 13 " Left  " 14 " TurnLeft  " 15 " RelieveNoOvertake  " 16 " NoOvertake  " 17 " StopGiveWay  " 18 " GiveWay  " 19 " NoPass  " 20 " NoEntry  " 21 " NoCar  " 22 " NoTruck  " 23 " NoBus  " 24 " NoTurnaround  " 25 " NoStraightLeftTurn  " 26 " NoStraightRightTurn  " 27 " NoLeftRightTurn  " 28 " NoLeftTurn  " 29 " NoRightTurn  " 30 " NoStraight  " 31 " WarnKids  " 32 " WarnPed  " 33 " WarnBike  " 34 " WarnWorks  " 35 " WarnWildanimal  " 36 " WarnCattle  " 37 " AccidentProneSection  " 38 " Town  " 39 " Slow  " 40 " SharpTurnR  " 41 " SharpTurnL  " 42 " ReverseCurveL  " 43 " ReverseCurveR  " 44 " ContinuousBend  " 45 " Crossroads  " 46 " ConfluenceR  " 47 " ConfluenceL  " 48 " Rain/Wetness " 49 " Snow/Icy " 50 " Time " 51 " Distance For " 52 " Distance In " 53 " Straight " 54 " FrontageLeft " 55 " TurnLeftRight " 56 " FrontageRight " 57 " Right " 58 " Turn Right " 59 " Left " 60 " Turn Left " 61 " Highway Start " 62 " Highway End " 63 " Mortorway Start " 64 " Mortorway End " 65 " City Entry " 66 " City Exit " 67 " Residential zones Entry " 68 " Residential zones Exit " 69 " Trailer " 70 " Reserved " 255 " Invalid " ;
VAL_ 719 TSRSpdLimWarn 0 " No Warning " 1 " Warning " ;
VAL_ 719 TSRWarnResp 0 " OFF " 1 " ON " ;
VAL_ 719 TSR_Snvty 0 " valid " 31 " Invalid " ;
VAL_ 721 DrvSeatHeatSts 0 " OFF " 1 " Level 1_low " 2 " Level 2_middle " 3 " Level 3_high " ;
VAL_ 721 PassSeatHeatSts 0 " OFF " 1 " Level 1_low " 2 " Level 2_middle " 3 " Level 3_high " ;
VAL_ 721 DrvSeatVentnSts 0 " OFF " 1 " Level 1_low " 2 " Level 2_middle " 3 " Level 3_high " ;
VAL_ 721 PassSeatVentnSts 0 " OFF " 1 " Level 1_low " 2 " Level 2_middle " 3 " Level 3_high " ;
VAL_ 722 Microphone_Cha1DTCInfo 0 " No error in this channel " 1 " Short to ground/short to ACC/ open load error " ;
VAL_ 722 Microphone_Cha2DTCInfo 0 " No error in this channel " 1 " Short to ground/short to ACC/ open load error " ;
VAL_ 722 Microphone_Cha3DTCInfo 0 " No error in this channel " 1 " Short to ground/short to ACC/ open load error " ;
VAL_ 722 Microphone_Cha4DTCInfo 0 " No error in this channel " 1 " Short to ground/short to ACC/ open load error " ;
VAL_ 722 ANCSwtStatus 0 " OFF " 1 " ON " ;
VAL_ 723 EngSpd_ForIP 0 " Valid values  " ;
VAL_ 723 EWP_Err 0 " No error " 1 " Error " ;
VAL_ 728 ADAS_Stub_MsgTyp 0 " System Specific " 1 " Position " 2 " Segment " 3 " Stub " 4 " Profile Short " 5 " Profile Long " 6 " Meta-data " 7 " Reserved " ;
VAL_ 728 ADAS_Stub_Offset 0 " Valid data " 8191 " Invalid data " ;
VAL_ 728 ADAS_Stub_CycCnt 0 " Valid value " ;
VAL_ 728 ADAS_Stub_PathIdx 0 " Valid value " ;
VAL_ 728 ADAS_Stub_StubPathIdx 0 " Valid value " ;
VAL_ 728 ADAS_Stub_Retr 0 " False " 1 " True " ;
VAL_ 728 ADAS_Stub_Update 0 " False " 1 " True " ;
VAL_ 728 ADAS_Stub_RelProbb 0 " unknown " 1 " Valid data " 31 " Invalid " ;
VAL_ 728 ADAS_Stub_FuncRoadClass 0 " Unkown " 1 " Expressway " 2 " City expressway " 3 " National road " 4 " Provincial rode or County road " 5 " City or Village road " 6 " Other road " 7 " Invalid " ;
VAL_ 728 ADAS_Stub_PartOfCalcRoute 0 " New path from this point on is not part of Calculated Route " 1 " New path from this point on is part of Calculated Route " 2 " Unknown " 3 " invalid " ;
VAL_ 728 ADAS_Stub_CmplxInsct 0 " New path is not part of complex intersection " 1 " New path is part of a complex intersection " 2 " Unknown " 3 " invalid " ;
VAL_ 728 ADAS_Stub_FormOfWay 0 " Unkown " 1 " Freeway or Controlled Access road that is not a slip road/ramp " 2 " Multiple Carriageway or Multiply Digitized Road " 3 " Single Carriageway (default) " 4 " Roundabout Circle " 5 " Traffic Square/Special Traffic Figure " 6 " Reserved " 8 " Parallel Road (as special type of a slip road/ramp) " 9 " Slip Road/Ramp on a Freeway or Controlled Access road " 10 " Slip Road/Ramp (not on a Freeway or Controlled Access road) " 11 " Service Road or Frontage Road " 12 " Entrance to or exit of a Car Park " 13 " Entrance to or exit to Service " 14 " Pedestrian Zone " 15 " Unknow " ;
VAL_ 728 ADAS_Stub_TurnAngl 0 " In path direction " 1 " 1.417 degrees right " 2 " Right from path direction " 126 " 178.583 degrees right " 127 " Opposite direction " 128 " 178.583 degrees left (181.417 degrees right) " 129 " Left from path direction " 253 " 1.417 degrees left (358.583 degrees right) " 254 " Unknown " 255 " Invalid " ;
VAL_ 728 ADAS_Stub_LastStub 0 " False " 1 " True " ;
VAL_ 728 ADAS_Stub_RtOfWay 0 " Drvg towards this stub has priority over all conflicting vehicle movements " 1 " Drvg towards this stub might require yielding to conflicting vehicle movements " 2 " Unknown " 3 " Invalid " ;
VAL_ 728 ADAS_Stub_NumOfLaneOppDir 0 " one-direction road " 1 " one lane only " 2 " indicates 2 or more lanes " 3 " invalid " ;
VAL_ 728 ADAS_Stub_NumOfLaneDrvDir 0 " One-direction road driven in wrong direction " 1 " Verbatim values " 6 " 6 or more lanes " 7 " invalid " ;
VAL_ 730 ADAS_Seg_MsgTyp 0 " System Specific " 1 " Position " 2 " Segment " 3 " Stub " 4 " Profile Short " 5 " Profile Long " 6 " Meta-data " 7 " Reserved " ;
VAL_ 730 ADAS_Seg_Offset 0 " Valid data " 8191 " Invalid data " ;
VAL_ 730 ADAS_Seg_CycCnt 0 " Valid value " ;
VAL_ 730 ADAS_Seg_PathIdx 0 " Valid value " ;
VAL_ 730 ADAS_Seg_Tunnel 0 " Segment is not part of a tunnel " 1 " Segment is part of a tunnel " 2 " Unknown " 3 " Invalid " ;
VAL_ 730 ADAS_Seg_Brdg 0 " Segment is not part of a bridge " 1 " Segment is part of a bridge " 2 " Unknown " 3 " Invalid " ;
VAL_ 730 ADAS_Seg_BuildUpArea 0 " Segment is not part of a built-up area " 1 " Segment is part of a built-up area " 2 " Unknown " 3 " Invalid " ;
VAL_ 730 ADAS_Seg_Retr 0 " False " 1 " True " ;
VAL_ 730 ADAS_Seg_Update 0 " False " 1 " True " ;
VAL_ 730 ADAS_Seg_RelProbb 0 " Unknown " 1 " Valid data " 31 " Invalid " ;
VAL_ 730 ADAS_Seg_FuncRoadClass 0 " Unkown " 1 " Expressway " 2 " City expressway " 3 " National road " 4 " Provincial rode or County road " 5 " City or Village road " 6 " Other road " 7 " Invalid " ;
VAL_ 730 ADAS_Seg_PartOfCalcRoute 0 " Segment is not part of Calculated Route " 1 " Segment is part of Calculated Route " 2 " Unknown " 3 " Invalid " ;
VAL_ 730 ADAS_Seg_CmplxInsct 0 " Segment is not part of complex intersection " 1 " Segment is part of a complex intersection " 2 " Unknown " 3 " Invalid " ;
VAL_ 730 ADAS_Seg_FormOfWay 0 " Unkown " 1 " Freeway or Controlled Access road that is not a slip road/ramp " 2 " Multiple Carriageway or Multiply Digitized Road " 3 " Single Carriageway (default) " 4 " Roundabout Circle " 5 " Traffic Square/Special Traffic Figure " 6 " Reserved " 8 " Parallel Road (as special type of a slip road/ramp) " 9 " Slip Road/Ramp on a Freeway or Controlled Access road " 10 " Slip Road/Ramp (not on a Freeway or Controlled Access road) " 11 " Service Road or Frontage Road " 12 " Entrance to or exit of a Car Park " 13 " Entrance to or exit to Service " 14 " Pedestrian Zone " 15 " Unknow " ;
VAL_ 730 ADAS_Seg_EffSpdLmt 0 " Unknown (including variable speed sign controlled) " 1 " value ≤ 5 km/h [mph] " 2 " 5 < value ≤ 7 km/h [mph] " 3 " 7 < value ≤ 10 km/h [mph] " 4 " 10 < value ≤ 15 km/h [mph] " 5 " 15 < value ≤ 20 km/h [mph] " 6 " 20 < value ≤ 25 km/h [mph] " 7 " 25 < value ≤ 30 km/h [mph] " 8 " 30 < value ≤ 35 km/h [mph] " 9 " 35 < value ≤ 40 km/h [mph] " 10 " 40 < value ≤ 45 km/h [mph] " 11 " 45 < value ≤ 50 km/h [mph] " 12 " 50 < value ≤ 55 km/h [mph] " 13 " 55 < value ≤ 60 km/h [mph] " 14 " 60 < value ≤ 65 km/h [mph] " 15 " 65 < value ≤ 70 km/h [mph] " 16 " 70 < value ≤ 75 km/h [mph] " 17 " 75 < value ≤ 80 km/h [mph] " 18 " 80 < value ≤ 85 km/h [mph] " 19 " 85 < value ≤ 90 km/h [mph] " 20 " 90 < value ≤ 95 km/h [mph] " 21 " 95 < value ≤ 100 km/h [mph] " 22 " 100 < value ≤ 105 km/h [mph] " 23 " 105 < value ≤ 110 km/h [mph] " 24 " 110 < value ≤ 115 km/h [mph] " 25 " 115 < value ≤ 120 km/h [mph] " 26 " 120 < value ≤ 130 km/h [mph] " 27 " 130 < value ≤ 140 km/h [mph] " 28 " 140 < value ≤ 150 km/h [mph] " 29 " 150 < value < unlimited " 30 " Unlimited " 31 " N/A " ;
VAL_ 730 ADAS_Seg_EffSpdLmtTyp 0 " Implicit (for instance, default speed limit in the cities) " 1 " Explicit – on traffic sign " 2 " Explicit – by night " 3 " Explicit – by day " 4 " Explicit – time of day " 5 " Explicit – Electronic eye " 6 " Explicit – snow " 7 " Unknown " ;
VAL_ 730 ADAS_Seg_DivideRoad 0 " Segment is not part of a divided road/dual carriageway " 1 " Segment is part of a divided road/dual carriageway " 2 " Unknown " 3 " N/A " ;
VAL_ 730 ADAS_Seg_NumOfLaneOppDir 0 " One-direction road " 1 " One lane only " 2 " Indicates 2 or more lanes " 3 " Invalid " ;
VAL_ 730 ADAS_Seg_NumOfLaneDrvDir 0 " One-direction road driven in wrong direction " 1 " Verbatim values " 6 " Six or more lanes " 7 " invalid " ;
VAL_ 731 ALCMSwtSts 0 " OFF " 1 " ON " ;
VAL_ 733 ADAS_ProfShort_MsgTyp 0 " System Specific " 1 " Position " 2 " Segment " 3 " Stub " 4 " Profile Short " 5 " Profile Long " 6 " Meta-data " 7 " Reserved " ;
VAL_ 733 ADAS_ProfShort_Offset 0 " 0-8190m " 8191 " Invalid " ;
VAL_ 733 ADAS_ProfShort_CycCnt 0 " Valid value " ;
VAL_ 733 ADAS_ProfShort_PathIdx 0 " Valid value " ;
VAL_ 733 ADAS_ProfShort_ProfTyp 0 " Unknow " 1 " Curvature " 2 " Route Number Types " 3 " Slope（step） " 4 " Slope（liner） " 5 " Road ACCessibility " 6 " Road condition " 7 " Variable Speed Sign Position " 8 " Heading Change " 9 " Reserved for standard types " 16 " Reserved for system specific types " 18 " History average speed " 19 " Traffic Flow " 20 " Reserved for system specific types " ;
VAL_ 733 ADAS_ProfShort_CtrlPoint 0 " false " 1 " true " ;
VAL_ 733 ADAS_ProfShort_Retr 0 " false " 1 " true " ;
VAL_ 733 ADAS_ProfShort_Update 0 " false " 1 " true " ;
VAL_ 733 ADAS_ProfShort_AccurClass 0 " Hiest accuracy " 1 " Medium accuracy " 2 " Lowest accuracy " 3 " Unknown " ;
VAL_ 733 ADAS_ProfShort_Dist1 0 " no other profile values are defined in this message " 1 " Valid value " 1023 " Invalid " ;
VAL_ 733 ADAS_ProfShort_Value0 0 " Valid data " 1023 " Unknow " ;
VAL_ 733 ADAS_ProfShort_Value1 0 " Valid data " 1023 " Unknow " ;
VAL_ 734 ADAS_ProfLong_MsgTyp 0 " System Specific " 1 " Position " 2 " Segment " 3 " Stub " 4 " Profile Short " 5 " Profile Long " 6 " Meta-data " 7 " Reserved " ;
VAL_ 734 ADAS_ProfLong_Offset 0 " Valid value " 8191 " Invalid " ;
VAL_ 734 ADAS_ProfLong_CycCnt 0 " Valid value " ;
VAL_ 734 ADAS_ProfLong_PathIdx 0 " Valid value " ;
VAL_ 734 ADAS_ProfLong_ProfTyp 0 " unkown " 1 " Longitude " 2 " Latitude " 3 " Altitude " 4 " Control Point Longitude " 5 " Control Point Latitude " 6 " Control Point Altitude " 7 " Link Identifier " 8 " Traffic Sign " 9 " Truck Speed Limits " 10 " Extended Lane " 11 " Reserved for standard types " 16 " Reserved for system specific types " 19 " Traffic Event " 20 " weather " 21 " Reserved for system specific types " ;
VAL_ 734 ADAS_ProfLong_CtrlPoint 0 " false " 1 " true " ;
VAL_ 734 ADAS_ProfLong_Retr 0 " false " 1 " true " ;
VAL_ 734 ADAS_ProfLong_Update 0 " false " 1 " true " ;
VAL_ 734 ADAS_ProfLong_Value 0 " Valid value " -2147483648 " invalid " ;
VAL_ 737 VSG_Sts 0 " Standby " 1 " Sound on " 2 " Fault " 3 " OFF " ;
VAL_ 737 VSG_HUTSoundResp 0 " sound 1 " 1 " sound 2  " 2 " sound 3 " 3 " Reserved " ;
VAL_ 748 DVRRemtCnSts 0 " Default " 1 " Connect success " 2 " Connect fail " 3 " Reserved " ;
VAL_ 748 DVR_360VideoCaptureReq 0 " Off " 1 " On " ;
VAL_ 749 RPAS_NearBrrdstn 0 " Valid value " 151 " Reserved " 255 " No Display " ;
VAL_ 762 HCU_EnerSavePowerMod 0 " No action " 1 " Close blower " 2 " Close seat heat " 3 " Close both blower and seat heat " ;
VAL_ 762 HCU_SOCLow_Indcn 0 " Not active " 1 " Active " ;
VAL_ 762 HCU_RemoveChrgLine_Indcn 0 " Not active " 1 " Active " ;
VAL_ 762 HCU_Shift_P_Indcn 0 " Not active " 1 " Active " ;
VAL_ 762 HCU_ConnectChrgLine_Indcn 0 " Not active " 1 " Active " ;
VAL_ 762 HCU_EgyRecFB 0 " Standard " 1 " Enhanced " 2 " Low " 3 " Not Available " ;
VAL_ 762 HCU_ACStsReq 0 " Disable " 1 " Derating " 2 " Normal " 3 " Invalid " ;
VAL_ 762 HCU_RefuReq 0 " No request " 1 " Refueling request " 2 " When vehicle is ready inhibit refuel " 3 " When engine is run inhibit refuel " 4 " When charger is connected inhibit refuel " 5 " Reserved " ;
VAL_ 762 HCU_OilTankCoverSts 0 " Closed " 1 " Open " ;
VAL_ 762 HCU_InhbChrgInfo 0 " No warning " 1 " When vehicle is refueling inhibit charge " ;
VAL_ 762 OPDParkWarnReq 0 " No Request " 1 " Request " ;
VAL_ 762 HCU_OPDFail 0 " Normal (Default)  " 1 " OPD function not available due to temporary hybrid system limitations " 2 " OPD function not available due to Snow mode " 3 " Reserved " ;
VAL_ 762 CarWashMode_StsDisp 0 " No Display " 1 " Speed too high,Transport/Car Wash Mode is not available " 2 " 12V battery SOC too low,Transport/Car Wash Mode is not available " 3 " Reserved " ;
VAL_ 762 CarWashMode_Sts 0 " Normal Mode " 1 " Car Wash Mode " ;
VAL_ 762 HCU_RefuBtnSts 0 " No pressed " 1 " Pressed " ;
VAL_ 766 PLG_Sts 0 " PLG unknown " 1 " Fully opened " 2 " Fully closed " 3 " Opening " 4 " Closing " 5 " PLG stopped " 6 " Latch releasing " 7 " Latch cinching " ;
VAL_ 770 WarnPowerNotInOffPosn 0 " No Warning " 1 " Warning " ;
VAL_ 770 WarnKeyInCarWhenExit 0 " No Warning " 1 " Warning " ;
VAL_ 770 WarnVldKeyNotFound 0 " No Warning " 1 " Warning " ;
VAL_ 770 WarnEngStrtNotMeet 0 " No Warning " 1 " Warning " ;
VAL_ 770 PowerRlyFault 0 " No failure " 1 " ACC/IGN1/IGN2 Relay failure(ACC Reserved) " ;
VAL_ 771 RotSteerWheel 0 " Off " 1 " Warning " ;
VAL_ 773 ClsWinRmd 0 " No Alarm " 1 " Alarm " ;
VAL_ 788 HCU_ACLineDisconnect 0 " Init " 1 " Not connect " 2 " connect " 3 " Reserved " ;
VAL_ 788 HCU_ChargSts 0 " Default " 1 " Charging（充电中） " 2 " Delaying " 3 " Charge complete " 4 " Charge stopped " 5 " Charge Initialize " 6 " Heating（插枪仅加热） " 7 " Charging and Heating（充电且加热） " ;
VAL_ 788 HCU_WorkshopMode 0 " Not active " 1 " Active " ;
VAL_ 788 HCU_IntelBattTempMagSts 0 " Off " 1 " On " ;
VAL_ 790 OBC_ModSts 0 " Discharging " 1 " Init " 2 " Standby " 3 " Heating " 4 " Charging Normal " 5 " Reserved " 8 " Fault " 9 " Reduced Power " 10 " Reserved " 11 " Sleep (Shutdown) " 12 " OFF " 13 " Reserved " ;
VAL_ 791 OBC_ConnectSts 0 " Not connected " 1 " Connected " 2 " Error " 3 " Reserved " ;
VAL_ 793 IPBackgroundLmpCmd 0 " Backlight OFF " 1 " Backlight ON " ;
VAL_ 793 TrunkSts 0 " Closed " 1 " Open " ;
VAL_ 793 DrvDoorSts 0 " Closed " 1 " Open " ;
VAL_ 793 LRDoorSts 0 " Closed " 1 " Open " ;
VAL_ 793 PassengerDoorSts 0 " Closed " 1 " Open " ;
VAL_ 793 RRDoorSts 0 " Closed " 1 " Open " ;
VAL_ 793 BrkPedalSts_BCM 0 " Off " 1 " On " ;
VAL_ 793 BackgroundLightLvl 0 " Valid Values " ;
VAL_ 793 DrowsyDrvDetWarn 0 " No warning " 1 " Warning 1 " 2 " Warning 2 " 3 " Not available " ;
VAL_ 793 RLSFailSts 0 " No failure " 1 " Failure " ;
VAL_ 793 ReversGearSts 0 " Off " 1 " On " 2 " Reserved " 3 " Not available " ;
VAL_ 793 PosnLightReq 0 " Off " 1 " On " ;
VAL_ 796 AudioMuteSts 0 " Not used " 1 " not producing audio " 2 " producing audio " 3 " Reserved " ;
VAL_ 796 VSGSwtSet 0 " VSG OFF " 1 " VSG ON " ;
VAL_ 805 HUD_SwtSts 0 " OFF " 1 " ON " ;
VAL_ 805 HUD_BrightnessLvl 0 " Level 1 " 1 " Level 2 " 2 " Level 3 " 3 " Level 4 " 4 " Level 5 " 5 " Level 6 " 6 " Level 7 " 7 " Level 8 " 8 " Level 9 " 9 " Reserved " ;
VAL_ 805 HUD_HeightLvl 0 " Level 1 " 1 " Level 2 " 2 " Level 3 " 3 " Level 4 " 4 " Level 5  " 5 " Level 6 " 6 " Level 7 " 7 " Level 8  " 8 " Level 9 " 9 " Level 10 " 10 " Level 11 " 11 " Level 12 " 12 " Level 13 " 13 " Level 14 " 14 " Level 15 " 15 " Level 16 " 16 " Level 17 " 17 " Level 18 " 18 " Level 19 " 19 " Level 20 " 20 " Level 21  " 21 " Reserved " ;
VAL_ 805 HUD_UIMod 0 " Normal Mode " 1 " Dot Matrix Mode " ;
VAL_ 805 HUD_UIModVld 0 " Invalid " 1 " Valid " ;
VAL_ 817 HUT_EgyRecvrySet 0 " Strong  " 1 " Normal  " 2 " Weak " 3 " No action " ;
VAL_ 817 ACDualReq_VR 0 " No action " 1 " Close " 2 " Open " 3 " Reserved " ;
VAL_ 817 ACAQSReq_VR 0 " No action " 1 " Close " 2 " Open " 3 " Reserved " ;
VAL_ 817 ACRearDefrstReq_VR 0 " No action " 1 " Close " 2 " Open " 3 " Reserved " ;
VAL_ 817 ACPassTempReq_VR 0 " No action " 1 " Low " 2 " Valid value(phys = 0.5 * raw + 15.5) " 33 " High " 34 " Reserved " ;
VAL_ 817 ACAIUReq_VR 0 " No action " 1 " Close " 2 " Open " 3 " Reserved " ;
VAL_ 817 IPVolSet 0 " Reserved " 10 " IP volume step 10-20 " 21 " Reserved " 63 " Invalid Value " ;
VAL_ 817 ALCMStatSwt 0 " Off " 1 " On " ;
VAL_ 817 ALCMDynSwt 0 " Off " 1 " On " ;
VAL_ 817 ALCMClrSet 0 " Colour set 0-63 " ;
VAL_ 817 ALCMRhmSwt 0 " Off " 1 " On " ;
VAL_ 817 PASSwtReq_VR 0 " No action " 1 " off " 2 " on " 3 " Reserved " ;
VAL_ 825 CarWashMode_Req 0 " Car Wash Mode OFF " 1 " Car Wash Mode ON " 2 " No action " 3 " Reserved " ;
VAL_ 825 HUT_ChrgnMode 0 " Immediate Charging " 1 " Delay Charging " 2 " Invalid value " 3 " No action " ;
VAL_ 825 HUT_BattKeepTemp 0 " Default " 1 " ON " 2 " OFF " 3 " Reserved " ;
VAL_ 825 HUT_IntelEngIdlChrgnSet 0 " Default " 1 " ON " 2 " OFF " 3 " Reserved " ;
VAL_ 825 HUT_BattSOCLim 0 " 100% " 1 " 50% " 2 " 60% " 3 " 70% " 4 " 80% " 5 " 90% " 6 " No action " 7 " Reserved " ;
VAL_ 825 HUT_AvailInputCur 0 " 10A " 1 " 8A " 2 " 13A " 3 " 16A(Reserved for 3.3kw) " 4 " No action " 5 " 32A(For 6.6kw) " 6 " Reserved " ;
VAL_ 825 HUT_IntelBattTempMagSet 0 " Default " 1 " ON " 2 " OFF " 3 " Reserved " ;
VAL_ 827 AVMSwtReq 0 " OFF " 1 " ON " ;
VAL_ 827 NaviMediaVolLvlReq 0 " Level 0 " 1 " Level 1 " 2 " Level 2 " 3 " Level 3 " 4 " Level 4 " 5 " Level 5 " 6 " Level 6 " 7 " Level 7 " 8 " Level 8 " 9 " Level 9 " 10 " Level 10 " 11 " Invalid " ;
VAL_ 827 AVMMediaVolLvlReq 0 " Level 0 " 1 " Level 1 " 2 " Level 2 " 3 " Level 3 " 4 " Level 4 " 5 " Level 5 " 6 " Level 6 " 7 " Level 7 " 8 " Level 8 " 9 " Level 9 " 10 " Level 10 " 11 " Invalid " ;
VAL_ 827 FPASChanSwtReq 0 " OFF " 1 " ON " ;
VAL_ 827 RPASChanSwtReq 0 " OFF " 1 " ON " ;
VAL_ 827 BackgroundLightLvlSet 0 " 1 " 1 " 2 " 2 " 3 " 3 " 4 " 4 " 5 " 5 " 6 " 6 " 7 " 7 " 8 " 8 " 9 " 9 " 10 " 10 " No action " 11 " Reserved " ;
VAL_ 827 ManCmpSet 0 " 0 " 1 " 1 " 2 " 2 " 3 " 3 " 4 " 4 " 5 " 5 " 6 " 6 " 7 " 7 " 8 " 8 " 9 " 9 " 10 " 10 " 11 " Reserved " ;
VAL_ 827 DispModSet 0 " Automode " 1 " Day mode " 2 " Night mode " 3 " Reserved " ;
VAL_ 827 OPDSwtSts 0 " ON " 1 " OFF " 2 " Unselect able " 3 " No action " ;
VAL_ 827 PLGReq_VR 0 " No action " 1 " Close " 2 " Open " 3 " Reserved " ;
VAL_ 827 WPC_SwtReq 0 " No action " 1 " Initial value " 2 " Close " 3 " Open " ;
VAL_ 833 FLTirePressIndSts 0 " Normal " 1 " Low  " 2 " Reserved  " 3 " High " 4 " Not available " 5 " Reserved " ;
VAL_ 833 FRTirePressIndSts 0 " Normal " 1 " Low  " 2 " Reserved  " 3 " High " 4 " Not available " 5 " Reserved " ;
VAL_ 833 TirePressSysFailrIndcn 0 " No failure " 1 " Failure " 2 " Reserved " ;
VAL_ 833 RLTirePressIndSts 0 " Normal " 1 " Low  " 2 " Reserved  " 3 " High " 4 " Not available " 5 " Reserved " ;
VAL_ 833 RRTirePressIndSts 0 " Normal " 1 " Low  " 2 " Reserved  " 3 " High " 4 " Not available " 5 " Reserved " ;
VAL_ 833 FLTireTempSts 0 " Normal " 1 " High " 2 " Not available " 3 " Reserved " ;
VAL_ 833 FRTireTempSts 0 " Normal " 1 " High " 2 " Not available " 3 " Reserved " ;
VAL_ 833 RLTireTempSts 0 " Normal " 1 " High " 2 " Not available " 3 " Reserved " ;
VAL_ 833 RRTireTempSts 0 " Normal " 1 " High " 2 " Not available " 3 " Reserved " ;
VAL_ 833 TPMS_AutoLoctSts 0 " Auto-Learn or Auto-Locate not in progress / TPMS is base system " 1 " Auto-Learn in progress " 2 " Auto-Locate in progress (Auto-Learn complete) " 3 " Auto-Locate complete " 4 " Auto-Learn timeout " 5 " Auto-Locate timeout " 6 " Reserved " ;
VAL_ 837 LasHdLmpSts 0 " Off  " 1 " On " ;
VAL_ 837 AntitheftSts 0 " Disarmed " 1 " Armed " 2 " Prearmed " 3 " Alarmed " ;
VAL_ 837 DrvDoorLockSts 0 " Lock " 1 " Unlock " ;
VAL_ 837 DoorLockSts 0 " NA " 1 " All doors locked " 2 " Driver door unlocked " 3 " All doors unlocked " ;
VAL_ 837 RLDoorLockSts 0 " Lock " 1 " Unlock " ;
VAL_ 837 PassDoorLockSts 0 " Lock " 1 " Unlock " ;
VAL_ 837 RRDoorLockSts 0 " Lock " 1 " Unlock " ;
VAL_ 837 HiLowBeamSts 0 " Off " 1 " ON " 2 " error " 3 " Reserved " ;
VAL_ 840 PowerSet 0 " OFF " 1 " ON " ;
VAL_ 842 IP_RemainDistance 0 " 0~2000 " 2001 " Reserved " 4095 " Invalid " ;
VAL_ 842 IP_InstFuelConsUnit 0 " L/100km " 1 " L/h " ;
VAL_ 842 IP_EBDFailSts 0 " No failure " 1 " Failure " ;
VAL_ 842 IP_AvgFuelCons 0 " Valid " 3000 " Reserved " 4095 " Invalid " ;
VAL_ 842 IP_InstFuelCons 0 " Valid " 10000 " Reserved " 16383 " Invalid " ;
VAL_ 849 CheckSum_ABM1 0 " Valid values " ;
VAL_ 849 SecRowLSBR 0 " No reminder " 1 " Reminder " ;
VAL_ 849 AirbFailLmpCmd 0 " Lamp off " 1 " Lamp on " ;
VAL_ 849 SecRowMidSBR 0 " No reminder " 1 " Reminder " ;
VAL_ 849 DrvSBR 0 " No reminder " 1 " Reminder " ;
VAL_ 849 SecRowRSBR 0 " No reminder " 1 " Reminder " ;
VAL_ 849 PassSBR 0 " No reminder " 1 " Reminder " ;
VAL_ 849 PassSBR_Visual 0 " Lamp off " 1 " Lamp on " 2 " Reserved " 3 " Lamp  blink & sound remind " ;
VAL_ 849 DrvSBR_Visual 0 " Lamp off " 1 " Lamp on " 2 " Reserved " 3 " Lamp  blink & sound remind " ;
VAL_ 849 SecRowLSBR_Visual 0 " Lamp off " 1 " Lamp on " 2 " Reserved " 3 " Lamp  blink & sound remind " ;
VAL_ 849 SecRowMidSBR_Visual 0 " Lamp off " 1 " Lamp on " 2 " Reserved " 3 " Lamp  blink & sound remind " ;
VAL_ 849 SecRowRSBR_Visual 0 " Lamp off " 1 " Lamp on " 2 " Reserved " 3 " Lamp  blink & sound remind " ;
VAL_ 849 CrashOutputSts 0 " No crash " 1 " Reserved " 2 " Front First level " 3 " rear crash(Reserved) " 4 " Reserved " 8 " Right hand side " 9 " Reserved " 16 " Left hand side  " 17 " Rollover(Reserved) " 18 " Static Roll(Reserved)  " 19 " Reserved " ;
VAL_ 849 RollingCounter_ABM1 0 " Valid value " 15 " Invalid value " ;
VAL_ 850 BMS_RemtPreHeatSts 0 " Default " 1 " Remote Pre-Heat Successfully set but not start " 2 " start heating " 3 " Fail to start heating " 4 " Remote Pre-Heating is complete " 5 " Reserved " ;
VAL_ 850 BMS_BattKeepTempSts 0 " Off " 1 " On " ;
VAL_ 850 BMS_IntelEngIdlChrgnSts 0 " Default " 1 " ON " 2 " Off " 3 " Reserved " ;
VAL_ 862 RoofModFb 0 " OFF " 1 " ON " ;
VAL_ 862 AllTerrainDislFb 0 " OFF " 1 " ON " ;
VAL_ 862 ElecSideStepSysFb 0 " OFF " 1 " ON " ;
VAL_ 871 DomeLmpDlyTimSet 0 " 3seconds " 1 " 10seconds " 2 " 20seconds " 3 " 30seconds " 4 " Reserved " ;
VAL_ 871 FolwMeHomeDlyTimSet 0 " 0seconds " 1 " 30seconds " 2 " 60seconds " 3 " 90seconds " 4 " Reserved " ;
VAL_ 871 TranPMode_Req 0 " Transport Mode OFF " 1 " Transport Mode ON " ;
VAL_ 871 RearviewFoldModSet 0 " Automatical " 1 " Manual " ;
VAL_ 871 BattSaveDelayTimeSet 0 " 2minutes " 1 " 5minutes " 2 " 8minutes " 3 " Reserved " ;
VAL_ 871 ACDualReq_TC 0 " No action " 1 " Pressed " 2 " Reserved " 3 " Reserved " ;
VAL_ 871 ACAutoModReq_TC 0 " No action " 1 " Pressed " 2 " Reserved " 3 " Reserved " ;
VAL_ 871 ACAirInletReq_TC 0 " No action " 1 " Pressed " 2 " OneButtonCloseWindows " 3 " Reserved " ;
VAL_ 871 ACAQSReq_TC 0 " No action " 1 " Pressed " 2 " Reserved " 3 " Reserved " ;
VAL_ 871 ACCmprReq_TC 0 " No action " 1 " Pressed " 2 " Reserved " 3 " Reserved " ;
VAL_ 871 ACFrntDefrstReq_TC 0 " No action " 1 " Pressed " 2 " Reserved " 3 " Reserved " ;
VAL_ 871 ACFrntBlwrSpdDecReq_TC 0 " No action " 1 " Pressed " 2 " Reserved " 3 " Reserved " ;
VAL_ 871 DrvDrowsnsDetnSet 0 " OFF " 1 " ON " ;
VAL_ 871 ACFrntBlwrSpdIncReq_TC 0 " No action " 1 " Pressed " 2 " Reserved " 3 " Reserved " ;
VAL_ 871 ACDrvAirDistribModReq_TC 0 " No action " 1 " Face " 2 " Face & Foot " 3 " Foot " 4 " Foot & Defrost " 5 " Reserved " ;
VAL_ 871 ACDrvTempDecReq_TC 0 " No action " 1 " Pressed " 2 " Reserved " 3 " Reserved " ;
VAL_ 871 ChairMemPosnEna 0 " Disable " 1 " Enable " ;
VAL_ 871 ACDrvTempIncReq_TC 0 " No action " 1 " Pressed " 2 " Reserved " 3 " Reserved " ;
VAL_ 871 ACFrntPassTempDecReq_TC 0 " No action " 1 " Pressed " 2 " Reserved " 3 " Reserved " ;
VAL_ 871 ACFrntPassTempIncReq_TC 0 " No action " 1 " Pressed " 2 " Reserved " 3 " Reserved " ;
VAL_ 871 ACAIUReq_TC 0 " No action " 1 " Pressed " ;
VAL_ 871 ACOffReq_TC 0 " No action " 1 " Pressed " 2 " Reserved " 3 " Reserved " ;
VAL_ 871 ACBlwrsteplsSpdReq_TC 0 " No Command " 1 " Stepless Speed1_Low " 2 " Stepless Speed2 " 3 " Stepless Speed3 " 4 " Stepless Speed4 " 5 " Stepless Speed5 " 6 " Stepless Speed6 " 7 " Stepless Speed7_High " 8 " Reserved " ;
VAL_ 873 AMP_MediaCallSourceSet 0 " Media Source on " 1 " Call Source on " 2 " Reserved " ;
VAL_ 873 AMP_NaviSourceSet 0 " None " 1 " Navi on " 2 " VR & TTS on " 3 " Reserved " ;
VAL_ 873 AMP_BeepSourceSet 0 " None " 1 " Beep on " 2 " IP on " 3 " IP turn light on " 4 " Radar alarm on " 5 " Reserved " ;
VAL_ 873 AMP_LRAudioBalanceSet 0 " Lch+10-Lch+1 " 10 " Center " 11 " Rch+1-Rch+10 " 21 " Reserved " ;
VAL_ 873 AMP_AudioVolVSCModReq 0 " OFF " 1 " Low " 2 " Middle " 3 " High " ;
VAL_ 873 AMP_FRAudioFaderSet 0 " Rear+10-Rear+1 " 10 " Center " 11 " Front+1-Front+10 " 21 " Reserved " ;
VAL_ 873 AMP_LRDrvSideSet 0 " Left " 1 " Right " ;
VAL_ 873 AMP_LowFrqAudioSet 0 " -10 " 1 " -9 " 2 " -8 " 3 " -7 " 4 " -6 " 5 " -5 " 6 " -4 " 7 " -3 " 8 " -2 " 9 " -1 " 10 " 0 " 11 " 1 " 12 " 2 " 13 " 3 " 14 " 4 " 15 " 5 " 16 " 6 " 17 " 7 " 18 " 8 " 19 " 9 " 20 " 10 " 21 " Reserved " ;
VAL_ 873 AMP_MuteSet 0 " Unmute " 1 " Mute " ;
VAL_ 873 AMP_MidFrqAudioSet 0 " -10 " 1 " -9 " 2 " -8 " 3 " -7 " 4 " -6 " 5 " -5 " 6 " -4 " 7 " -3 " 8 " -2 " 9 " -1 " 10 " 0 " 11 " 1 " 12 " 2 " 13 " 3 " 14 " 4 " 15 " 5 " 16 " 6 " 17 " 7 " 18 " 8 " 19 " 9 " 20 " 10 " 21 " Reserved " ;
VAL_ 873 AMP_HighFrqAudioSet 0 " -10 " 1 " -9 " 2 " -8 " 3 " -7 " 4 " -6 " 5 " -5 " 6 " -4 " 7 " -3 " 8 " -2 " 9 " -1 " 10 " 0 " 11 " 1 " 12 " 2 " 13 " 3 " 14 " 4 " 15 " 5 " 16 " 6 " 17 " 7 " 18 " 8 " 19 " 9 " 20 " 10 " 21 " Reserved " ;
VAL_ 873 T_box_ECallSet 0 " OFF " 1 " ON " ;
VAL_ 873 QLISurroundSet 0 " Stereo " 1 " QLI Surround " ;
VAL_ 873 ANCSwtSet 0 " OFF " 1 " ON " ;
VAL_ 873 RearWinHeatCmd_TC 0 " No action " 1 " Pressed " 2 " Reserved " 3 " Reserved " ;
VAL_ 873 FrntWinHeatSwt 0 " No action " 1 " Pressed " ;
VAL_ 875 AMP_HFMVolSet 0 " HFM volume step 0-39 " 40 " Reserved " 63 " Invalid Value " ;
VAL_ 875 AMP_TTSVolSet_VR 0 " VR_TTS volume step 0-39 " 40 " Reserved " 63 " Invalid Value " ;
VAL_ 875 AMP_NaviVolSet 0 " Navi volume step 0-39 " 40 " Reserved " 63 " Invalid Value " ;
VAL_ 875 AMP_MainVolSet 0 " Main volume step 0-39 " 40 " Reserved " 63 " Invalid Value " ;
VAL_ 875 AMP_GetSWInfoReq 0 " No action " 1 " Get information " ;
VAL_ 875 AMP_GetHWInfoReq 0 " No action " 1 " Get information " ;
VAL_ 875 AMP_GetTempInfoReq 0 " No action " 1 " Get information " ;
VAL_ 875 AMP_GetIntVoltInfoReq 0 " No action " 1 " Get information " ;
VAL_ 875 AMP_GetDTCInfoReq 0 " No action " 1 " Get information " ;
VAL_ 875 IESS_MdlSwtReq 0 " OFF " 1 " Model 1 " 2 " Model 2 " 3 " Model 3 " ;
VAL_ 875 IESS_MdlInfoReq 0 " No action " 1 " Get information " ;
VAL_ 875 AMP_BestListegPosnReq 0 " All Seat " 1 " Front Seat " 2 " Rear Seat " 3 " Driver Seat " 4 " Boss Seat " 5 " Children sleep Seat " 6 " reserved " 7 " reserved " ;
VAL_ 875 AMP_Clari_FiReq 0 " OFF " 1 " ON " ;
VAL_ 877 DrvSeatHeatgLvlSet 0 " OFF " 1 " Level 1_Low " 2 " Level 2_Middle " 3 " Level 3_High " ;
VAL_ 877 PassSeatHeatgLvlSet 0 " OFF " 1 " Level 1_Low " 2 " Level 2_Middle " 3 " Level 3_High " ;
VAL_ 877 DrvSeatVentnLvlSet 0 " OFF " 1 " Level 1_Low " 2 " Level 2_Middle " 3 " Level 3_High " ;
VAL_ 877 PassSeatVentnLvlSet 0 " OFF " 1 " Level 1_Low " 2 " Level 2_Middle " 3 " Level 3_High " ;
VAL_ 877 ACAutoModReq_VR 0 " No action " 1 " Not active_reserved " 2 " Active " 3 " Reserved " ;
VAL_ 877 ACCmprReq_VR 0 " No action " 1 " Not active " 2 " Active " 3 " Reserved " ;
VAL_ 877 ACPowerReq_VR 0 " No action " 1 " Power off " 2 " Power on " 3 " Reserved " ;
VAL_ 877 ACBlwrSpdReq_VR 0 " No Command " 1 " Stepless Speed1_Low " 2 " Stepless Speed2 " 3 " Stepless Speed3 " 4 " Stepless Speed4 " 5 " Stepless Speed5 " 6 " Stepless Speed6 " 7 " Stepless Speed7_High " 8 " Reserved " ;
VAL_ 877 ACDrvTempReq_VR 0 " No action " 1 " Low " 2 " valid value(phys=0.5 * raw + 15.5) " 33 " High " 34 " Reserved " ;
VAL_ 877 ACFrntDefrostReq_VR 0 " No action " 1 " Not active " 2 " Active " 3 " Reserved " ;
VAL_ 877 ACDrvAirDistribModReq_VR 0 " No action " 1 " Face " 2 " Face & Foot " 3 " Foot " 4 " Foot & Defrost " 5 " Reserved " ;
VAL_ 877 ACAirInletReq_VR 0 " no action " 1 " Fresh " 2 " Recirculation " 3 " Reserved " ;
VAL_ 877 ACModReq_HUT 0 " no action " 1 " comfort " 2 " economy " 3 " reserved " ;
VAL_ 877 ElecSideSteppingSysSet 0 " OFF " 1 " ON " ;
VAL_ 877 RoofModSet 0 " OFF " 1 " ON " ;
VAL_ 877 AllTerrainDislSet 0 " OFF " 1 " ON " ;
VAL_ 880 TimeMod 0 " 24 " 1 " 12 " ;
VAL_ 880 TimeIndcn 0 " am " 1 " pm " ;
VAL_ 880 Time_Hour 0 " Valid hour " 24 " Reserved " 31 " Invalid " ;
VAL_ 880 Time_Minutes 0 " Valid minute " 60 " Reserved " 63 " Invalid " ;
VAL_ 880 Time_Second 0 " Valid second " 60 " Reserved " 63 " Invalid " ;
VAL_ 880 Time_Year_Left 0 " Valid year " 10 " Reserved " 15 " Invalid " ;
VAL_ 880 Time_Year_Right 0 " Valid year " 10 " Reserved " 15 " Invalid " ;
VAL_ 880 Time_Month 0 " Invalid " 1 " Valid month " 13 " Reserved " ;
VAL_ 880 Time_Day 0 " Invalid " 1 " Valid day " ;
VAL_ 881 EngCoolantTemp 0 " Valid values " ;
VAL_ 881 GPF_Warning 0 " No Warning " 1 " GPF is regenerating " 2 " GPF need to regenerate " 3 " Reserved " ;
VAL_ 881 GentrWarnLmpSts 0 " Off " 1 " On " ;
VAL_ 881 EngClntTempWarn 0 " No " 1 " Yes " ;
VAL_ 881 EngClntTempVldty 0 " Invalid " 1 " Valid " 2 " Init value " ;
VAL_ 881 SS_Screen_tip 0 " no screen tip " 1 " screen tip " ;
VAL_ 881 SSSSetSts 0 " Off " 1 " On " ;
VAL_ 881 SS_Enable_Lamp 0 " Lamp off  " 1 " Lamp on " ;
VAL_ 881 SS_Fault_Lamp 0 " Lamp off  " 1 " Lamp on " ;
VAL_ 881 BaroPressure 0 " Valid values " 255 " Invalid value " ;
VAL_ 901 ACFrntDefrstSts 0 " Off " 1 " On " ;
VAL_ 901 ACHMIDispCmd 0 " No Display " 1 " No Display（AC status changed in Auto mode） " 2 " Display " 3 " Reserved " ;
VAL_ 901 ACFrntBlwrSpd 0 " Off " 1 " Level 1（Low）-7（Hi） " 8 " Reserved " 14 " Auto blower level " 15 " Initial value " ;
VAL_ 901 ACOpenSts 0 " Off " 1 " On " ;
VAL_ 901 ACDualModEnaSts 0 " Disable " 1 " Enable " ;
VAL_ 901 ACDrvTemp_ATC 0 " Low " 1 " Valid value " 32 " High " 33 " Initial value " 34 " Reserved " ;
VAL_ 901 ACAmbTemp 0 " Valid value " 254 " Initial value " 255 " Invalid Value " ;
VAL_ 901 ACAirInletSts 0 " Recirculation " 1 " Fresh " 2 " Auto " 3 " Initial value " ;
VAL_ 901 ACFrntPasstTemp_ATC 0 " Low " 1 " Valid value " 32 " High " 33 " Initial value " 34 " Reserved " ;
VAL_ 901 ACAutoModEnaSts 0 " Disable " 1 " Enable " ;
VAL_ 901 ACCmprEnaSts 0 " Disable " 1 " Enable " ;
VAL_ 901 AC_FrntWinHeatEnaSts 0 " Disable " 1 " Enable " ;
VAL_ 901 AC_FrntWinHeatDislSts 0 " Active " 2 " Forbidden " ;
VAL_ 901 ACAutoDefrstModEnaSts 0 " Disable " 1 " Enable " ;
VAL_ 909 HCU_PowertrainSts_RM 1 " ON " 2 " OFF " 3 " Other Mode " ;
VAL_ 909 HCU_ChargSts_RM 1 " Parking charging " 2 " Driving charging " 3 " Uncharged " 4 " Charge end " 5 " Reserved " ;
VAL_ 909 HCU_PTDrvMod_RM 1 " EV Mode " 2 " Hybrid Mode " 3 " Fuel oil Mode " ;
VAL_ 909 HCU_Powerflag_RM 0 " No power " 1 " Power " ;
VAL_ 909 HCU_AccelPedalPosn_Diag_RM 0 " Vaild value " ;
VAL_ 909 HCU_BrkPedalSts_RM 0 " 0% " 101 " Brake pedal pressed " ;
VAL_ 909 HCU_DrvPower_RM 0 " No Power " 1 " Power " ;
VAL_ 909 HCU_BrkPower_RM 0 " No Power " 1 " Power " ;
VAL_ 909 HCU_GearSts_RM 0 " N " 1 " Valid value " 13 " R " 14 " D " 15 " P " ;
VAL_ 917 FLTirePress 0 " Valid Value " 255 " Invalid Value " ;
VAL_ 917 FLTireTemp 0 " Valid Value " 255 " Invalid Value " ;
VAL_ 917 FRTirePress 0 " Valid Value " 255 " Invalid Value " ;
VAL_ 917 FRTireTemp 0 " Valid Value " 255 " Invalid Value " ;
VAL_ 917 RLTirePress 0 " Valid Value " 255 " Invalid Value " ;
VAL_ 917 RLTireTemp 0 " Valid Value " 255 " Invalid Value " ;
VAL_ 917 RRTirePress 0 " Valid Value " 255 " Invalid Value " ;
VAL_ 917 RRTireTemp 0 " Valid Value " 255 " Invalid Value " ;
VAL_ 929 IESS_SwitchModel 0 " OFF " 1 " Model 1 " 2 " Model 2 " 3 " Model 3 " ;
VAL_ 948 TMCU_ActHvDcCurr_RM 0 " Valid value " 20001 " Reserved " 65534 " Error " 65535 " Invalid value " ;
VAL_ 948 TMCU_ActHvDcVolt_RM 0 " Valid value " 60001 " Reserved " 65534 " Error " 65535 " Invalid value " ;
VAL_ 948 TMCU_ActTemp_RM 0 " Valid value " 251 " Reserved " 254 " Error " 255 " Invalid value " ;
VAL_ 948 TMCU_Tempwarning_RM 0 " Normal " 1 " Warning " ;
VAL_ 948 TMCU_InvTempwarning_RM 0 " Normal " 1 " Warning " ;
VAL_ 948 TMCU_OperMode_RM 0 " Reserved " 1 " Consume power " 2 " Generate electricity " 3 " Shut down " 4 " Ready " 5 " Reserved " 254 " Error " 255 " Invalid value " ;
VAL_ 951 ECM_VehDstBackup 0 " 0-9999999-km " 10000000 " Reserved " 16777215 " Invalid " ;
VAL_ 951 EngRoStrt_Failure 13 " Bit4 " 12 " Bit5 " 10 " Engine auth no passed " 9 " Vehicle not in remote mode " 8 " BCM checksum or " 7 " Engine is fault(mil on) " 6 " The vehicle is not stop " 5 " The fuel is less " 4 " The veihcle in collision state " 3 " Exceed the max run time " 2 " No error " 1 " Bit3 " 0 " No error " 11 " Engine auth no passed " ;
VAL_ 957 DCDC_Tempwarning_RM 0 " No warning " 1 " warning " ;
VAL_ 957 DCDC_ActSts_RM 0 " Initial value " 1 " On " 2 " Off " 3 " Reserved " ;
VAL_ 957 DCDC_FailStswarning_RM 0 " No warning " 1 " warning " ;
VAL_ 959 BMS_ChrgDurationTime 0 " Valid value " 1023 " Invalid " ;
VAL_ 962 HCU_EVContnsDistance 0 " Vaild value " 101 " Reserved " 127 " Invalid " ;
VAL_ 962 HCU_EVContnsDistanceVld 0 " Invalid " 1 " Valid " ;
VAL_ 962 HCU_RecupPwr 0 " Valid value " ;
VAL_ 962 HCU_EgyUsed 0 " Valid value " ;
VAL_ 962 HCU_HiVoltInterlockSts_RM 0 " Normal  " 1 " Warning " ;
VAL_ 969 TMCU_Amount_RM 0 " Reserved " 1 " Valid value " 254 " Invalid value " ;
VAL_ 969 TMCU_MotorSerNumber_RM 0 " Reserved " 1 " Valid value " 254 " Invalid value " ;
VAL_ 969 TMCU_InvActTemp_RM 0 " Valid value " 251 " Reserved " 254 " Error " 255 " Invalid value " ;
VAL_ 969 TMCU_ActSpd_RM 0 " Valid value " 65532 " Reserved " 65534 " Error " 65535 " Invalid value " ;
VAL_ 969 TMCU_ActTrq_RM 0 " Valid value " 65532 " Reserved " 65534 " Error " 65535 " Invalid value " ;
VAL_ 976 BMS_BattTempMax 0 " Valid value " 166 " Reserved " 255 " invalid " ;
VAL_ 976 BMS_BattTempMin 0 " Valid value " 166 " Reserved " 255 " invalid " ;
VAL_ 977 BMS_BattModuleTe_11 0 " Valid value " 166 " Reserved " 255 " invalid " ;
VAL_ 977 BMS_BattModuleTe_12 0 " Valid value " 166 " Reserved " 255 " invalid " ;
VAL_ 977 BMS_BattModuleTe_21 0 " Valid value " 166 " Reserved " 255 " invalid " ;
VAL_ 977 BMS_BattModuleTe_22 0 " Valid value " 166 " Reserved " 255 " invalid " ;
VAL_ 977 BMS_BattModuleTe_31 0 " Valid value " 166 " Reserved " 255 " invalid " ;
VAL_ 977 BMS_BattModuleTe_32 0 " Valid value " 166 " Reserved " 255 " invalid " ;
VAL_ 977 BMS_BattModuleTe_41 0 " Valid value " 166 " Reserved " 255 " invalid " ;
VAL_ 977 BMS_BattModuleTe_42 0 " Valid value " 166 " Reserved " 255 " invalid " ;
VAL_ 977 BMS_BattModuleTe_51 0 " Valid value " 166 " Reserved " 255 " invalid " ;
VAL_ 977 BMS_BattModuleTe_52 0 " Valid value " 166 " Reserved " 255 " invalid " ;
VAL_ 977 BMS_BattModuleTe_61 0 " Valid value " 166 " Reserved " 255 " invalid " ;
VAL_ 977 BMS_BattModuleTe_62 0 " Valid value " 166 " Reserved " 255 " invalid " ;
VAL_ 977 BMS_BattModuleTe_71 0 " Valid value " 166 " Reserved " 255 " invalid " ;
VAL_ 977 BMS_BattModuleTe_72 0 " Valid value " 166 " Reserved " 255 " invalid " ;
VAL_ 977 BMS_BattModuleTe_81 0 " Valid value " 166 " Reserved " 255 " invalid " ;
VAL_ 977 BMS_BattModuleTe_82 0 " Valid value " 166 " Reserved " 255 " invalid " ;
VAL_ 977 BMS_SingleCellVolt_1 0 " Valid value " 60001 " Reserved " ;
VAL_ 977 BMS_SingleCellVolt_2 0 " Valid value " 60001 " Reserved " ;
VAL_ 977 BMS_SingleCellVolt_3 0 " Valid value " 60001 " Reserved " ;
VAL_ 977 BMS_SingleCellVolt_4 0 " Valid value " 60001 " Reserved " ;
VAL_ 977 BMS_SingleCellVolt_5 0 " Valid value " 60001 " Reserved " ;
VAL_ 977 BMS_SingleCellVolt_6 0 " Valid value " 60001 " Reserved " ;
VAL_ 977 BMS_SingleCellVolt_7 0 " Valid value " 60001 " Reserved " ;
VAL_ 977 BMS_SingleCellVolt_8 0 " Valid value " 60001 " Reserved " ;
VAL_ 977 BMS_SingleCellVolt_9 0 " Valid value " 60001 " Reserved " ;
VAL_ 977 BMS_SingleCellVolt_10 0 " Valid value " 60001 " Reserved " ;
VAL_ 977 BMS_SingleCellVolt_11 0 " Valid value " 60001 " Reserved " ;
VAL_ 977 BMS_SingleCellVolt_12 0 " Valid value " 60001 " Reserved " ;
VAL_ 978 BMS_SingleCellVolt_13 0 " Valid value " 60001 " Reserved " ;
VAL_ 978 BMS_SingleCellVolt_14 0 " Valid value " 60001 " Reserved " ;
VAL_ 978 BMS_SingleCellVolt_15 0 " Valid value " 60001 " Reserved " ;
VAL_ 978 BMS_SingleCellVolt_16 0 " Valid value " 60001 " Reserved " ;
VAL_ 978 BMS_SingleCellVolt_17 0 " Valid value " 60001 " Reserved " ;
VAL_ 978 BMS_SingleCellVolt_18 0 " Valid value " 60001 " Reserved " ;
VAL_ 978 BMS_SingleCellVolt_19 0 " Valid value " 60001 " Reserved " ;
VAL_ 978 BMS_SingleCellVolt_20 0 " Valid value " 60001 " Reserved " ;
VAL_ 978 BMS_SingleCellVolt_21 0 " Valid value " 60001 " Reserved " ;
VAL_ 978 BMS_SingleCellVolt_22 0 " Valid value " 60001 " Reserved " ;
VAL_ 978 BMS_SingleCellVolt_23 0 " Valid value " 60001 " Reserved " ;
VAL_ 978 BMS_SingleCellVolt_24 0 " Valid value " 60001 " Reserved " ;
VAL_ 978 BMS_SingleCellVolt_25 0 " Valid value " 60001 " Reserved " ;
VAL_ 978 BMS_SingleCellVolt_26 0 " Valid value " 60001 " Reserved " ;
VAL_ 978 BMS_SingleCellVolt_27 0 " Valid value " 60001 " Reserved " ;
VAL_ 978 BMS_SingleCellVolt_28 0 " Valid value " 60001 " Reserved " ;
VAL_ 978 BMS_SingleCellVolt_29 0 " Valid value " 60001 " Reserved " ;
VAL_ 978 BMS_SingleCellVolt_30 0 " Valid value " 60001 " Reserved " ;
VAL_ 978 BMS_SingleCellVolt_31 0 " Valid value " 60001 " Reserved " ;
VAL_ 978 BMS_SingleCellVolt_32 0 " Valid value " 60001 " Reserved " ;
VAL_ 978 BMS_SingleCellVolt_33 0 " Valid value " 60001 " Reserved " ;
VAL_ 978 BMS_SingleCellVolt_34 0 " Valid value " 60001 " Reserved " ;
VAL_ 978 BMS_SingleCellVolt_35 0 " Valid value " 60001 " Reserved " ;
VAL_ 978 BMS_SingleCellVolt_36 0 " Valid value " 60001 " Reserved " ;
VAL_ 978 BMS_SingleCellVolt_37 0 " Valid value " 60001 " Reserved " ;
VAL_ 978 BMS_SingleCellVolt_38 0 " Valid value " 60001 " Reserved " ;
VAL_ 978 BMS_SingleCellVolt_39 0 " Valid value " 60001 " Reserved " ;
VAL_ 978 BMS_SingleCellVolt_40 0 " Valid value " 60001 " Reserved " ;
VAL_ 979 BMS_SingleCellVolt_41 0 " Valid value " 60001 " Reserved " ;
VAL_ 979 BMS_SingleCellVolt_42 0 " Valid value " 60001 " Reserved " ;
VAL_ 979 BMS_SingleCellVolt_43 0 " Valid value " 60001 " Reserved " ;
VAL_ 979 BMS_SingleCellVolt_44 0 " Valid value " 60001 " Reserved " ;
VAL_ 979 BMS_SingleCellVolt_45 0 " Valid value " 60001 " Reserved " ;
VAL_ 979 BMS_SingleCellVolt_46 0 " Valid value " 60001 " Reserved " ;
VAL_ 979 BMS_SingleCellVolt_47 0 " Valid value " 60001 " Reserved " ;
VAL_ 979 BMS_SingleCellVolt_48 0 " Valid value " 60001 " Reserved " ;
VAL_ 979 BMS_SingleCellVolt_49 0 " Valid value " 60001 " Reserved " ;
VAL_ 979 BMS_SingleCellVolt_50 0 " Valid value " 60001 " Reserved " ;
VAL_ 979 BMS_SingleCellVolt_51 0 " Valid value " 60001 " Reserved " ;
VAL_ 979 BMS_SingleCellVolt_52 0 " Valid value " 60001 " Reserved " ;
VAL_ 979 BMS_SingleCellVolt_53 0 " Valid value " 60001 " Reserved " ;
VAL_ 979 BMS_SingleCellVolt_54 0 " Valid value " 60001 " Reserved " ;
VAL_ 979 BMS_SingleCellVolt_55 0 " Valid value " 60001 " Reserved " ;
VAL_ 979 BMS_SingleCellVolt_56 0 " Valid value " 60001 " Reserved " ;
VAL_ 979 BMS_SingleCellVolt_57 0 " Valid value " 60001 " Reserved " ;
VAL_ 979 BMS_SingleCellVolt_58 0 " Valid value " 60001 " Reserved " ;
VAL_ 979 BMS_SingleCellVolt_59 0 " Valid value " 60001 " Reserved " ;
VAL_ 979 BMS_SingleCellVolt_60 0 " Valid value " 60001 " Reserved " ;
VAL_ 979 BMS_SingleCellVolt_61 0 " Valid value " 60001 " Reserved " ;
VAL_ 979 BMS_SingleCellVolt_62 0 " Valid value " 60001 " Reserved " ;
VAL_ 979 BMS_SingleCellVolt_63 0 " Valid value " 60001 " Reserved " ;
VAL_ 979 BMS_SingleCellVolt_64 0 " Valid value " 60001 " Reserved " ;
VAL_ 979 BMS_SingleCellVolt_65 0 " Valid value " 60001 " Reserved " ;
VAL_ 979 BMS_SingleCellVolt_66 0 " Valid value " 60001 " Reserved " ;
VAL_ 979 BMS_SingleCellVolt_67 0 " Valid value " 60001 " Reserved " ;
VAL_ 979 BMS_SingleCellVolt_68 0 " Valid value " 60001 " Reserved " ;
VAL_ 980 BMS_SingleCellVolt_69 0 " Valid value " 60001 " Reserved " ;
VAL_ 980 BMS_SingleCellVolt_70 0 " Valid value " 60001 " Reserved " ;
VAL_ 980 BMS_SingleCellVolt_71 0 " Valid value " 60001 " Reserved " ;
VAL_ 980 BMS_SingleCellVolt_72 0 " Valid value " 60001 " Reserved " ;
VAL_ 980 BMS_SingleCellVolt_73 0 " Valid value " 60001 " Reserved " ;
VAL_ 980 BMS_SingleCellVolt_74 0 " Valid value " 60001 " Reserved " ;
VAL_ 980 BMS_SingleCellVolt_75 0 " Valid value " 60001 " Reserved " ;
VAL_ 980 BMS_SingleCellVolt_76 0 " Valid value " 60001 " Reserved " ;
VAL_ 980 BMS_SingleCellVolt_77 0 " Valid value " 60001 " Reserved " ;
VAL_ 980 BMS_SingleCellVolt_78 0 " Valid value " 60001 " Reserved " ;
VAL_ 980 BMS_SingleCellVolt_79 0 " Valid value " 60001 " Reserved " ;
VAL_ 980 BMS_SingleCellVolt_80 0 " Valid value " 60001 " Reserved " ;
VAL_ 980 BMS_SingleCellVolt_81 0 " Valid value " 60001 " Reserved " ;
VAL_ 980 BMS_SingleCellVolt_82 0 " Valid value " 60001 " Reserved " ;
VAL_ 980 BMS_SingleCellVolt_83 0 " Valid value " 60001 " Reserved " ;
VAL_ 980 BMS_SingleCellVolt_84 0 " Valid value " 60001 " Reserved " ;
VAL_ 980 BMS_SingleCellVolt_85 0 " Valid value " 60001 " Reserved " ;
VAL_ 980 BMS_SingleCellVolt_86 0 " Valid value " 60001 " Reserved " ;
VAL_ 980 BMS_SingleCellVolt_87 0 " Valid value " 60001 " Reserved " ;
VAL_ 980 BMS_SingleCellVolt_88 0 " Valid value " 60001 " Reserved " ;
VAL_ 980 BMS_SingleCellVolt_89 0 " Valid value " 60001 " Reserved " ;
VAL_ 980 BMS_SingleCellVolt_90 0 " Valid value " 60001 " Reserved " ;
VAL_ 980 BMS_SingleCellVolt_91 0 " Valid value " 60001 " Reserved " ;
VAL_ 980 BMS_SingleCellVolt_92 0 " Valid value " 60001 " Reserved " ;
VAL_ 980 BMS_SingleCellVolt_93 0 " Valid value " 60001 " Reserved " ;
VAL_ 980 BMS_SingleCellVolt_94 0 " Valid value " 60001 " Reserved " ;
VAL_ 980 BMS_SingleCellVolt_95 0 " Valid value " 60001 " Reserved " ;
VAL_ 980 BMS_SingleCellVolt_96 0 " Valid value " 60001 " Reserved " ;
VAL_ 981 BMS_SingleCellVolt_97 0 " Valid value " 60001 " Reserved " ;
VAL_ 981 BMS_SingleCellVolt_98 0 " Valid value " 60001 " Reserved " ;
VAL_ 981 BMS_SingleCellVolt_99 0 " Valid value " 60001 " Reserved " ;
VAL_ 981 BMS_SingleCellVolt_100 0 " Valid value " 60001 " Reserved " ;
VAL_ 981 BMS_SingleCellVolt_101 0 " Valid value " 60001 " Reserved " ;
VAL_ 981 BMS_SingleCellVolt_102 0 " Valid value " 60001 " Reserved " ;
VAL_ 981 BMS_SingleCellVolt_103 0 " Valid value " 60001 " Reserved " ;
VAL_ 981 BMS_SingleCellVolt_104 0 " Valid value " 60001 " Reserved " ;
VAL_ 981 BMS_SingleCellVolt_105 0 " Valid value " 60001 " Reserved " ;
VAL_ 981 BMS_SingleCellVolt_106 0 " Valid value " 60001 " Reserved " ;
VAL_ 981 BMS_SingleCellVolt_107 0 " Valid value " 60001 " Reserved " ;
VAL_ 981 BMS_SingleCellVolt_108 0 " Valid value " 60001 " Reserved " ;
VAL_ 981 BMS_SingleCellVolt_109 0 " Valid value " 60001 " Reserved " ;
VAL_ 981 BMS_SingleCellVolt_110 0 " Valid value " 60001 " Reserved " ;
VAL_ 981 BMS_SingleCellVolt_111 0 " Valid value " 60001 " Reserved " ;
VAL_ 981 BMS_SingleCellVolt_112 0 " Valid value " 60001 " Reserved " ;
VAL_ 981 BMS_BattModuleTe_91 0 " Valid value " 166 " Reserved " 255 " invalid " ;
VAL_ 981 BMS_BattModuleTe_92 0 " Valid value " 166 " Reserved " 255 " invalid " ;
VAL_ 981 BMS_DTCNumber 0 " Default " 1 " Valid value " 502 " Reserved " ;
VAL_ 981 BMS_NumberCellVoltMin_RM 0 " Reseved " 1 " Valid value " 251 " Reseved " ;
VAL_ 981 BMS_ModuleMaxTemp_RM 0 " Valid value " 251 " Reseved " ;
VAL_ 993 AMP_SWVersion 1 " Major Version " 11 " Major Version " ;
VAL_ 993 AMP_HWVersion 1 " Sample Phase " 11 " Sample Phase " ;
VAL_ 993 AMP_Chan1DTCInfo 0 " No error in this channel " 1 " Short to ground/short to ACC/ open load error " ;
VAL_ 993 AMP_Chan2DTCInfo 0 " No error in this channel " 1 " Short to ground/short to ACC/ open load error " ;
VAL_ 993 AMP_Chan3DTCInfo 0 " No error in this channel " 1 " Short to ground/short to ACC/ open load error " ;
VAL_ 993 AMP_Chan4DTCInfo 0 " No error in this channel " 1 " Short to ground/short to ACC/ open load error " ;
VAL_ 993 AMP_Chan5DTCInfo 0 " No error in this channel " 1 " Short to ground/short to ACC/ open load error " ;
VAL_ 993 AMP_Chan6DTCInfo 0 " No error in this channel " 1 " Short to ground/short to ACC/ open load error " ;
VAL_ 993 AMP_Chan7DTCInfo 0 " No error in this channel " 1 " Short to ground/short to ACC/ open load error " ;
VAL_ 993 AMP_Chan8DTCInfo 0 " No error in this channel " 1 " Short to ground/short to ACC/ open load error " ;
VAL_ 993 AMP_TempValue 0 " Amplifier internal temperature value " 255 " Invalid value " ;
VAL_ 993 AMP_TempSts 0 " Temperature normal " 1 " Temperature value lower than working temperature " 2 " Temperature value higher than working temperature " 3 " Invalid temperature value " ;
VAL_ 993 AMP_VolValue 0 " Amplifier internal voltage value " 255 " Invalid value " ;
VAL_ 993 BestListegPosnResp 0 " All Seat " 1 " Front Seat " 2 " Rear Seat " 3 " Driver Seat " 4 " Boss Seat " 5 " Children sleep Seat " 6 " reserved " 7 " reserved " ;
VAL_ 993 Clari_FiResp 0 " OFF " 1 " ON " ;
VAL_ 995 MediaCallSourceState 0 " Media Source on " 1 " Call Source on " 2 " Reserved-CH I CH II通道 " ;
VAL_ 995 BeepSourceSts 0 " None " 1 " Beep on " 2 " IP on " 3 " IP turn light on " 4 " Radar alarm on " 5 " Reserved CH III " ;
VAL_ 995 BalanceSetState 0 " Lch+10 - Lch+1 " 10 " Center " 11 " Rch+1 - Rch+10 " 21 " Reserved " ;
VAL_ 995 VSCModeState 0 " OFF " 1 " LOW " 2 " MID " 3 " HI " ;
VAL_ 995 FadeSetState 0 " Rear+10 - Rear+1 " 10 " Center " 11 " Front+1 - Front+10 " 21 " Reserved " ;
VAL_ 995 DriveSideSts 0 " LHD " 1 " RHD " ;
VAL_ 995 BassSetState 0 " -10 - -1 " 10 " 0 " 11 " +1 - +10 " 21 " Reserved " ;
VAL_ 995 MuteState 0 " Unmute " 1 " Mute " ;
VAL_ 995 NaviSourceState 0 " None " 1 " Navi on " 2 " VR/TTS on " 3 " Reserved-CH IV " ;
VAL_ 995 MidrangeSetState 0 " -10 " 1 " -9 " 2 " -8 " 3 " -7 " 4 " -6 " 5 " -5 " 6 " -4 " 7 " -3 " 8 " -2 " 9 " -1 " 10 " 0 " 11 " 1 " 12 " 2 " 13 " 3 " 14 " 4 " 15 " 5 " 16 " 6 " 17 " 7 " 18 " 8 " 19 " 9 " 20 " 10 " 21 " Reserved " ;
VAL_ 995 T_box_ECallSts 0 " OFF " 1 " ON " ;
VAL_ 995 GetHUTInfoSts 0 " No action " 1 " Action " ;
VAL_ 995 TrebleSetState 0 " -10 " 1 " -9 " 2 " -8 " 3 " -7 " 4 " -6 " 5 " -5 " 6 " -4 " 7 " -3 " 8 " -2 " 9 " -1 " 10 " 0 " 11 " 1 " 12 " 2 " 13 " 3 " 14 " 4 " 15 " 5 " 16 " 6 " 17 " 7 " 18 " 8 " 19 " 9 " 20 " 10 " 21 " Reserved " ;
VAL_ 995 QLISurroundSetSt 0 " Stereo " 1 " Surround " ;
VAL_ 995 AVMStResp 0 " OFF " 1 " ON " ;
VAL_ 995 NaviMediaVolLvlResp 0 " Main audio attenuation Level 0 " 1 " Main audio attenuation Level 1 " 2 " Main audio attenuation Level 2 " 3 " Main audio attenuation Level 3 " 4 " Main audio attenuation Level 4 " 5 " Main audio attenuation Level 5 " 6 " Main audio attenuation Level 6 " 7 " Main audio attenuation Level 7 " 8 " Main audio attenuation Level 8 " 9 " Main audio attenuation Level 9 " 10 " Main audio attenuation Level 10 " 11 " Invalid " ;
VAL_ 995 AVMMediaVolLvlResp 0 " Main audio attenuation Level 0 " 1 " Main audio attenuation Level 1 " 2 " Main audio attenuation Level 2 " 3 " Main audio attenuation Level 3 " 4 " Main audio attenuation Level 4 " 5 " Main audio attenuation Level 5 " 6 " Main audio attenuation Level 6 " 7 " Main audio attenuation Level 7 " 8 " Main audio attenuation Level 8 " 9 " Main audio attenuation Level 9 " 10 " Main audio attenuation Level 10 " 11 " Invalid " ;
VAL_ 995 FPASChStResp 0 " OFF " 1 " ON " ;
VAL_ 995 RPASChStResp 0 " OFF " 1 " ON " ;
VAL_ 997 HFMVolSetSts 0 " HFM/RT/Tbox-I&B Call volume step 0-39 " 40 " Reserved " 63 " Invalid Value " ;
VAL_ 997 VR_TTSVolSetSts 0 " VR/TTS volume step 0-39 " 40 " Reserved " 63 " Invalid Value " ;
VAL_ 997 NaviVolumeSetState 0 " Navi volume step 0-39 " 40 " Reserved " 63 " Invalid Value " ;
VAL_ 997 MainVolumeSetState 0 " Main volume step 0-39 " 40 " Reserved " 63 " Invalid Value " ;
VAL_ 997 AMPPowerSts 0 " OFF " 1 " ON " ;
VAL_ 997 IPVolSetSts 0 " Reserved " 10 " IP volume step 10-20 " 21 " Reserved " 63 " Invalid Value " ;
VAL_ 1001 T_Box_SWUpdSts 0 " Idle " 1 " NAD start update " 2 " NAD update inprogress " 3 " NAD update done " 4 " NAD update failed " 5 " MCU start update " 6 " MCU update done " 7 " Reserved " ;
VAL_ 1001 T_Box_SysErrSts 0 " No error " 1 " Error " 2 " Reserved " ;
VAL_ 1008 BMS_CellMaxVolt_RM 0 " Valid " 15001 " Reserved " ;
VAL_ 1008 BMS_CellVoltMin_RM 0 " Valid " 15001 " Reserved " ;
VAL_ 1008 BMS_NumCellMaxTemp_RM 0 " Reseved " 1 " Valid value " 251 " Reseved " ;
VAL_ 1008 BMS_NumCellMinTemp_RM 0 " Reseved " 1 " Valid value " 251 " Reseved " ;
VAL_ 1008 BMS_ModuleMinTemp_RM 0 " Valid value " 251 " Reseved " ;
VAL_ 1008 BMS_NumberCellVoltMax_RM 0 " Reseved " 1 " Valid value " 251 " Reseved " ;
VAL_ 1008 BMS_SocJumpWarn_RM 0 " No warning " 1 " warning " ;
VAL_ 1008 BMS_PackOverChrgWarn_RM 0 " No warning " 1 " warning " ;
VAL_ 1008 BMS_IsolationRValue_RM 0 " Valid value " 60001 " Reseved " ;
VAL_ 1008 BMS_PackCurr_RM 0 " Valid value " 20001 " Reserved " ;
VAL_ 1008 BMS_SocOverWarn_RM 0 " No warning " 1 " warning " ;
VAL_ 1008 BMS_BattOverTempRank_RM 0 " Normal " 1 " Waining " ;
VAL_ 1008 BMS_BattOverVoltRank_RM 0 " Normal " 1 " Waining " ;
VAL_ 1008 BMS_BattSOCLowRank_RM 0 " Normal " 1 " Waining " ;
VAL_ 1008 BMS_VCUIsolateErr_RM 0 " Normal " 1 " Waining " ;
VAL_ 1008 BMS_BattUnderVoltRank_RM 0 " Normal " 1 " Waining " ;
VAL_ 1008 BMS_CellDeltaVoltRank_RM 0 " Normal " 1 " Waining " ;
VAL_ 1008 BMS_CellOverVoltRank_RM 0 " Normal " 1 " Waining " ;
VAL_ 1008 BMS_CellUnderVoltRank_RM 0 " Normal " 1 " Waining " ;
VAL_ 1008 BMS_DeltaTempRank_RM 0 " Normal " 1 " Waining " ;
VAL_ 1008 BMS_PackMismatchWarn_RM 0 " No warning " 1 " warning " ;
VAL_ 1008 BMS_PackVolt_RM 0 " Valid value " 10001 " Reserved " ;
VAL_ 1008 BMS_SysNumberCellVoltMax_RM 0 " Reseved " 1 " Valid value " 251 " Reseved " ;
VAL_ 1008 BMS_SysNumberCellVoltMin_RM 0 " Reseved " 1 " Valid value " 251 " Reseved " ;
VAL_ 1008 BMS_SysNumCellMaxTemp_RM 0 " Reseved " 1 " Valid value " 251 " Reseved " ;
VAL_ 1008 BMS_SysNumCellMinTemp_RM 0 " Reseved " 1 " Valid value " 251 " Reseved " ;
VAL_ 1008 BMS_BattSysNum_RM 0 " Reseved " 1 " Valid value " 251 " Reseved " ;
VAL_ 1009 BMS_CellUnderVolt 0 " Normal " 1 " warning " ;
VAL_ 1009 BMS_CellOverVolt 0 " Normal " 1 " warning " ;
VAL_ 1009 BMS_CellDeltaVolt 0 " Normal " 1 " warning " ;
VAL_ 1009 BMS_BattUnderVolt 0 " Normal " 1 " warning " ;
VAL_ 1009 BMS_BattOverVolt 0 " Normal " 1 " warning " ;
VAL_ 1009 BMS_BattUnderTemp 0 " Normal " 1 " warning " ;
VAL_ 1009 BMS_SOC_Plaucheck 0 " Normal " 1 " warning（＞10%） " ;
VAL_ 1009 BMS_DeltaTemp 0 " Normal " 1 " warning " ;
VAL_ 1009 BMS_CANComErr 0 " Normal " 1 " warning " ;
VAL_ 1009 BMS_SOCLowWarn 0 " Normal " 1 " Need to charge " ;
VAL_ 1009 BMS_BattSOCLow 0 " Normal " 1 " warning " ;
VAL_ 1009 BMS_BattSOCTooLow 0 " Normal " 1 " warning " ;
VAL_ 1009 BMS_BattSOCHigh 0 " Normal " 1 " warning " ;
VAL_ 1009 BMS_ChrgnCurrLager 0 " Normal " 1 " warning " ;
VAL_ 1009 BMS_DischrgnCurrLager 0 " Normal " 1 " warning " ;
VAL_ 1009 BMS_ModuleMismatchWarn 0 " Normal " 1 " warning " ;
VAL_ 1009 BMS_cohrnc 0 " Normal " 1 " warning " ;
VAL_ 1009 BMS_moduleNumber 0 " Module1~Module9 " ;
VAL_ 1009 BMS_NumModuleTempSnsr 0 " sensor1~sensor18 " ;
VAL_ 1009 BMS_NumCell 0 " Cell1~Cell108 " 108 " Reserved " ;
VAL_ 1010 BMS_CellVoltMin 0 " Valid value " ;
VAL_ 1010 BMS_NumberCellVoltMin 0 " Cell1~Cell108 " 108 " Reserved " ;
VAL_ 1010 BMS_CellMaxVolt 0 " Valid value " ;
VAL_ 1010 BMS_NumberCellMaxVolt 0 " Cell1~Cell108 " 108 " Reserved " ;
VAL_ 1010 BMS_CellBalanceSts 0 " not active " 1 " active normally " 2 " reserved " ;
VAL_ 1010 BMS_RlyCounterSts 0 " Normal " 1 " positive relay OUL(over use of life) " 2 " negative relay OUL " 3 " Precharge relay OUL " ;
VAL_ 1010 BMS_SOH_R 0 " Valid value " 1001 " Reserved " 1023 " Invalid " ;
VAL_ 1011 BMS_ModuleMinTemp 0 " Valid Value " 131 " Reserved " 255 " Invalid " ;
VAL_ 1011 BMS_ModuleNumCellMinTemp 0 " Module1~Module9 " ;
VAL_ 1011 BMS_ModuleNumCellMaxTemp 0 " Module1~Module9 " ;
VAL_ 1011 BMS_ModuleMaxTemp 0 " Valid Value " 131 " Reserved " 255 " Invalid " ;
VAL_ 1011 BMS_NumCellMinTemp 0 " Module1~Module17 " ;
VAL_ 1011 BMS_NumCellMaxTemp 0 " Module1~Module17 " ;
VAL_ 1011 BMS_BattOverTempWarn 0 " Normal " 1 " warning 1 (55~65oC) " 2 " warning 2 (≥65oC) " 3 " Reserved " ;
VAL_ 1011 BMS_ModuleNumberCellMinVolt 0 " Number1~number9 " ;
VAL_ 1011 BMS_ModuleNumberCellMaxVolt 0 " Number1~number9 " ;
VAL_ 1045 ADAS_Meta_MsgTyp 0 " System Specific " 1 " Position " 2 " Segment " 3 " Stub " 4 " Profile Short " 5 " Profile Long " 6 " Meta-data " 7 " Reserved " ;
VAL_ 1045 ADAS_Meta_MapProvider 0 " Unknown " 1 " Nokia HERE (NAVTEQ) " 2 " TomTom (Tele Atlas) " 3 " Zenrin " 4 " IPC " 5 " NavInfo " 6 " Other " 7 " N/A " ;
VAL_ 1045 ADAS_Meta_CountryCode 0 " Unknown " 1 " Valid values " ;
VAL_ 1045 ADAS_Meta_CycCnt 0 " Valid values " ;
VAL_ 1045 ADAS_Meta_ProtVer_Major 0 " Valid values " ;
VAL_ 1045 ADAS_Meta_ProtVer_MinorSub 0 " Valid values " ;
VAL_ 1045 ADAS_Meta_HwVer 0 " Unknown " 1 " Valid values " ;
VAL_ 1045 ADAS_Meta_DrvSide 0 " Drvg Side Left " 1 " Drvg Side Right " ;
VAL_ 1045 ADAS_Meta_RegionCode 0 " Unknow " 1 " Valid values " 32767 " Invalid " ;
VAL_ 1045 ADAS_Meta_MapVerQtr 0 " Valid values " ;
VAL_ 1045 ADAS_Meta_MapVerYear 0 " Valid values " 63 " invalid " ;
VAL_ 1045 ADAS_Meta_SpdUnits 0 " KM/H " 1 " MPH " ;
VAL_ 1045 ADAS_Meta_ProtVer_Minor 0 " Valid values " ;
VAL_ 1290 Destination_T_Box_NM 1 "GW" 2 "PEPS" 3 "ESCL" 4 "LRSDS" 5 "RRSDS" 6 "BCM" 7 "Trailer" 8 "T-Box" 9 "CMS" 10 "AC" 11 "SCM" 12 "DSM" 13 "DDCM" 14 "PDCM" 15 "HUT" 16 "HCM" 17 "AC_RCP" 18 "TPMS" 32 "ACU" 33 "HCU" 34 "OBC" 35 "BMS" 36 "MCU" 37 "BSG" ;
VAL_ 1290 OpCode_T_Box_NM 1 "Alive" 2 "ring" 4 "limphome" 18 "ring_sleep_ind" 20 "limphome_sleep_ind" 50 "ring_sleep_ack" ;
VAL_ 1289 Destination_HUT_NM 1 "GW" 2 "PEPS" 3 "ESCL" 4 "LRSDS" 5 "RRSDS" 6 "BCM" 7 "Trailer" 8 "T-Box" 9 "CMS" 10 "AC" 11 "SCM" 12 "DSM" 13 "DDCM" 14 "PDCM" 15 "HUT" 16 "HCM" 17 "AC_RCP" 18 "TPMS" 32 "ACU" 33 "HCU" 34 "OBC" 35 "BMS" 36 "MCU" 37 "BSG" ;
VAL_ 1289 OpCode_HUT_NM 1 "Alive" 2 "ring" 4 "limphome" 18 "ring_sleep_ind" 20 "limphome_sleep_ind" 50 "ring_sleep_ack" ;
VAL_ 1302 Destination_DMS_NM 1 "GW" 2 "PEPS" 3 "ESCL" 4 "LRSDS" 5 "RRSDS" 6 "BCM" 7 "Trailer" 8 "T-Box" 9 "CMS" 10 "AC" 11 "SCM" 12 "DSM" 13 "DDCM" 14 "PDCM" 15 "HUT" 16 "HCM" 17 "AC_RCP" 18 "TPMS" 32 "ACU" 33 "HCU" 34 "OBC" 35 "BMS" 36 "MCU" 37 "BSG" ;
VAL_ 1302 OpCode_DMS_NM 1 "Alive" 2 "ring" 4 "limphome" 18 "ring_sleep_ind" 20 "limphome_sleep_ind" 50 "ring_sleep_ack" ;
VAL_ 1303 Destination_DVR_NM 1 "GW" 2 "PEPS" 3 "ESCL" 4 "LRSDS" 5 "RRSDS" 6 "BCM" 7 "Trailer" 8 "T-Box" 9 "CMS" 10 "AC" 11 "SCM" 12 "DSM" 13 "DDCM" 14 "PDCM" 15 "HUT" 16 "HCM" 17 "AC_RCP" 18 "TPMS" 32 "ACU" 33 "HCU" 34 "OBC" 35 "BMS" 36 "MCU" 37 "BSG" ;
VAL_ 1303 OpCode_DVR_NM 1 "Alive" 2 "ring" 4 "limphome" 18 "ring_sleep_ind" 20 "limphome_sleep_ind" 50 "ring_sleep_ack" ;
VAL_ 1281 Destination_GW_NM 1 "GW" 2 "PEPS" 3 "ESCL" 4 "LRSDS" 5 "RRSDS" 6 "BCM" 7 "Trailer" 8 "T-Box" 9 "CMS" 10 "AC" 11 "SCM" 12 "DSM" 13 "DDCM" 14 "PDCM" 15 "HUT" 16 "HCM" 17 "AC_RCP" 18 "TPMS" 32 "ACU" 33 "HCU" 34 "OBC" 35 "BMS" 36 "MCU" 37 "BSG" ;
VAL_ 1281 OpCode_GW_NM 1 "Alive" 2 "ring" 4 "limphome" 18 "ring_sleep_ind" 20 "limphome_sleep_ind" 50 "ring_sleep_ack" ;
